VERSION ""

NS_ :

BS_:

BU_: PFAF_HS LVMPC_HS DCDC_HS AMP_HS VICM2_HS FICM_HS ARS_HS MCP_B_HS MCP_A_HS ICCM_OBD_HS SAS_HS ACCM_HS VLBS_HS EBCM_OBD_HS EDI_HS HPCC_HS VITM_OBD_HS PTAM_HS OBCM_HS VICM_HS HCP_HS FDCM_HS APPS_HS ICCM_HS EOCM_F_HS GPCM_HS FSCM_ITBC_HS SCM_HS ITBC_HS VCM_HS HMIM_HS FCP_HS VES_HS Dummy_HS MCP_C_HS RWS_HS ONSTAR_HS EPS_HS TestTool_HS MCP_HS BCP_HS ALC_HS AHL_AFL_HS SADS_HS EPB_HS FSCM_HS AFS_HS FCM_HS TCCM_HS RDCM_HS PTO_HS PCM_HS EBCM_HS ACC_HS BCM_HS TCM_HS ECM_HS
VAL_TABLE_ vt_BooleanValues 1 "true" 0 "false" ;
VAL_TABLE_ TCTPIR_DrvNotfn 15 "Indication 15" 14 "Indication 14" 13 "Indication 13" 12 "Indication 12" 11 "Indication 11" 10 "Indication 10" 9 "Indication 9" 8 "Indication 8" 7 "Indication 7" 6 "Indication 6" 5 "Indication 5" 4 "Indication 4" 3 "Indication 3" 2 "Indication 2" 1 "Indication 1" 0 "No Indication" ;
VAL_TABLE_ PltfrmEngSpdCmmndSt 3 "Request Denied" 2 "Lost Arbitration" 1 "Request Honored" 0 "No Request" ;
VAL_TABLE_ TrStPTGrdBrkDsMdOvr 3 "Unused and Reserved" 2 "To Grade Braking Disable" 1 "To Not Grade Braking Disable" 0 "No Override" ;
VAL_TABLE_ SpdLmtrSttngTyp 1 "Auto" 0 "Manual" ;
VAL_TABLE_ HiPresFuelPmpCntMd 6 "Zero Flow Mode" 5 "Noise Control Max Mode" 4 "Noise Control Disable Mode" 3 "Start Mode" 2 "Normal Mode" 1 "DFCO Mode" 0 "Disable Mode" ;
VAL_TABLE_ ClmtCtrlHtrEngRunRq 1 "Engine Run Requested" 0 "No Action" ;
VAL_TABLE_ TrnsStWntrMdOvrd 2 "Override To Winter" 1 "Override To Not Winter" 0 "No Override" ;
VAL_TABLE_ TrnsStTwHaulMdOvrd 2 "Override To Tow Haul" 1 "Override To Not Tow Haul" 0 "No Override" ;
VAL_TABLE_ TrnsStSprtMdOvrd 2 "Override To Sport" 1 "Override To Not Sport" 0 "No Override" ;
VAL_TABLE_ TrnsStEconMdOvrd 2 "Override To Economy" 1 "Override To Not Economy" 0 "No Override" ;
VAL_TABLE_ StgSysPerfMdRq 7 "Performance Mode 7" 6 "Performance Mode 6" 5 "Performance Mode 5" 4 "Performance Mode 4" 3 "Performance Mode 3" 2 "Performance Mode 2" 1 "Performance Mode 1" 0 "No Action" ;
VAL_TABLE_ SndEnhcmtPerfMdRq 7 "Performance Mode 7" 6 "Performance Mode 6" 5 "Performance Mode 5" 4 "Performance Mode 4" 3 "Performance Mode 3" 2 "Performance Mode 2" 1 "Performance Mode 1" 0 "No Action" ;
VAL_TABLE_ RideCntrlPerfMdRq 7 "Performance Mode 7" 6 "Performance Mode 6" 5 "Performance Mode 5" 4 "Performance Mode 4" 3 "Performance Mode 3" 2 "Performance Mode 2" 1 "Performance Mode 1" 0 "No Action" ;
VAL_TABLE_ ExhstPerfMdRq 7 "Performance Mode 7" 6 "Performance Mode 6" 5 "Performance Mode 5" 4 "Performance Mode 4" 3 "Performance Mode 3" 2 "Performance Mode 2" 1 "Performance Mode 1" 0 "No Action" ;
VAL_TABLE_ DsplyPerfMdRq 7 "Performance Mode 7" 6 "Performance Mode 6" 5 "Performance Mode 5" 4 "Performance Mode 4" 3 "Performance Mode 3" 2 "Performance Mode 2" 1 "Performance Mode 1" 0 "No Action" ;
VAL_TABLE_ DiffPerfMdRq 7 "Performance Mode 7" 6 "Performance Mode 6" 5 "Performance Mode 5" 4 "Performance Mode 4" 3 "Performance Mode 3" 2 "Performance Mode 2" 1 "Performance Mode 1" 0 "No Action" ;
VAL_TABLE_ AWDPerfMdRq 7 "Performance Mode 7" 6 "Performance Mode 6" 5 "Performance Mode 5" 4 "Performance Mode 4" 3 "Performance Mode 3" 2 "Performance Mode 2" 1 "Performance Mode 1" 0 "No Action" ;
VAL_TABLE_ RdHVltBatPckVltM 1 "Use Data" 0 "Don't Use Data" ;
VAL_TABLE_ RdHVltBatPckCrntM 1 "Use Data" 0 "Don't Use Data" ;
VAL_TABLE_ RdHVltBatMinClVltM 1 "Use Data" 0 "Don't Use Data" ;
VAL_TABLE_ RdHVltBatMaxClVltM 1 "Use Data" 0 "Don't Use Data" ;
VAL_TABLE_ AFRP_SnsTyp 3 "Gauge Pressure" 2 "Absolute Pressure" 1 "Pressure Relative Manifold Vacuum" 0 "Not Supported" ;
VAL_TABLE_ FICMDS3_DTCStatus 4 "Diagnostic Failed" 3 "Diagnostic Passed" 2 "No Status to Report" 1 "Critically Disabled" 0 "Not Supported" ;
VAL_TABLE_ FICMDS2_DTCStatus 4 "Diagnostic Failed" 3 "Diagnostic Passed" 2 "No Status to Report" 1 "Critically Disabled" 0 "Not Supported" ;
VAL_TABLE_ FICMDS1_DTCStatus 4 "Diagnostic Failed" 3 "Diagnostic Passed" 2 "No Status to Report" 1 "Critically Disabled" 0 "Not Supported" ;
VAL_TABLE_ PropSysOffTmeM 1 "Use Data" 0 "Don't Use Data" ;
VAL_TABLE_ OffBrdChrgOffTmeM 1 "Use Data" 0 "Don't Use Data" ;
VAL_TABLE_ BattThrmlCondOffTmeM 1 "Use Data" 0 "Don't Use Data" ;
VAL_TABLE_ CrsSecSwStat 15 "Unused and Reserved 7" 14 "Unused and Reserved 6" 13 "Unused and Reserved 5" 12 "Unused and Reserved 4" 11 "Unused and Reserved 3" 10 "Unused and Reserved 2" 9 "Between Ranges" 8 "Short to Power" 7 "Open/Short to Ground" 6 "Speed Decrease High" 5 "Speed Increase High" 4 "Gap Up" 3 "Gap Down" 2 "Unused and Reserved 1" 1 "No Activation" 0 "Indeterminate" ;
VAL_TABLE_ EDADS_RcmndtFwdGr 15 "Unused and Reserved 7" 14 "Unused and Reserved 6" 13 "Unused and Reserved 5" 12 "Unused and Reserved 4" 11 "Unused and Reserved 3" 10 "Unused and Reserved 2" 9 "Unused and Reserved 1" 8 "Eighth Gear" 7 "Seventh Gear" 6 "Sixth Gear" 5 "Fifth Gear" 4 "Fourth Gear" 3 "Third Gear" 2 "Second Gear" 1 "First Gear" 0 "None" ;
VAL_TABLE_ EDADS_CrntFwdMsdG 15 "Unused and Reserved 7" 14 "Unused and Reserved 6" 13 "Unused and Reserved 5" 12 "Unused and Reserved 4" 11 "Unused and Reserved 3" 10 "Unused and Reserved 2" 9 "Unused and Reserved 1" 8 "Eighth Gear" 7 "Seventh Gear" 6 "Sixth Gear" 5 "Fifth Gear" 4 "Fourth Gear" 3 "Third Gear" 2 "Second Gear" 1 "First Gear" 0 "None" ;
VAL_TABLE_ EDADS_ShftIndStat 2 "No Shift" 1 "Shift Up" 0 "Shift Down" ;
VAL_TABLE_ PrsElvtdIdlCntlStat 1 "Enabled" 0 "Disabled" ;
VAL_TABLE_ GPCMDS2_DTCStatus 4 "Diagnostic Failed" 3 "Diagnostic Passed" 2 "No Status to Report" 1 "Critically Disabled" 0 "Not Supported" ;
VAL_TABLE_ EngPwrCnfg 15 "Configuration 15" 14 "Configuration 14" 13 "Configuration 13" 12 "Configuration 12" 11 "Configuration 11" 10 "Configuration 10" 9 "Configuration 9" 8 "Configuration 8" 7 "Configuration 7" 6 "Configuration 6" 5 "Configuration 5" 4 "Configuration 4" 3 "Configuration 3" 2 "Configuration 2" 1 "Configuration 1" 0 "Default" ;
VAL_TABLE_ CTSS_StbltyLvl 7 "Level 7" 6 "Level 6" 5 "Level 5" 4 "Level 4" 3 "Level 3" 2 "Level 2" 1 "Level 1" 0 "Level 0" ;
VAL_TABLE_ CTSS_StbltyTyp 7 "Unused and Reserved 4" 6 "Unused and Reserved 3" 5 "Unused and Reserved 2" 4 "Unused and Reserved 1" 3 "Torque Increase Pending" 2 "Torque Decrease Pending" 1 "Torque High Pulsation" 0 "Normal Stability" ;
VAL_TABLE_ DslExhFldWrngIdRqER 15 "Warning Level 15" 14 "Warning Level 14" 13 "Warning Level 13" 12 "Warning Level 12" 11 "Warning Level 11" 10 "Warning Level 10" 9 "Warning Level 9" 8 "Warning Level 8" 7 "Warning Level 7" 6 "Warning Level 6" 5 "Warning Level 5" 4 "Warning Level 4" 3 "Warning Level 3" 2 "Warning Level 2" 1 "Warning Level 1" 0 "No Indication" ;
VAL_TABLE_ DslExhFldQlyWrngIReq 15 "Warning Level 15" 14 "Warning Level 14" 13 "Warning Level 13" 12 "Warning Level 12" 11 "Warning Level 11" 10 "Warning Level 10" 9 "Warning Level 9" 8 "Warning Level 8" 7 "Warning Level 7" 6 "Warning Level 6" 5 "Warning Level 5" 4 "Warning Level 4" 3 "Warning Level 3" 2 "Warning Level 2" 1 "Warning Level 1" 0 "No Indication" ;
VAL_TABLE_ DslExNxEmWrngIndRq 15 "Warning Level 15" 14 "Warning Level 14" 13 "Warning Level 13" 12 "Warning Level 12" 11 "Warning Level 11" 10 "Warning Level 10" 9 "Warning Level 9" 8 "Warning Level 8" 7 "Warning Level 7" 6 "Warning Level 6" 5 "Warning Level 5" 4 "Warning Level 4" 3 "Warning Level 3" 2 "Warning Level 2" 1 "Warning Level 1" 0 "No Indication" ;
VAL_TABLE_ DslExFldTpWrngIndRq 15 "Warning Level 15" 14 "Warning Level 14" 13 "Warning Level 13" 12 "Warning Level 12" 11 "Warning Level 11" 10 "Warning Level 10" 9 "Warning Level 9" 8 "Warning Level 8" 7 "Warning Level 7" 6 "Warning Level 6" 5 "Warning Level 5" 4 "Warning Level 4" 3 "Warning Level 3" 2 "Warning Level 2" 1 "Warning Level 1" 0 "No Indication" ;
VAL_TABLE_ DslExFldCnWrngIndRq 15 "Warning Level 15" 14 "Warning Level 14" 13 "Warning Level 13" 12 "Warning Level 12" 11 "Warning Level 11" 10 "Warning Level 10" 9 "Warning Level 9" 8 "Warning Level 8" 7 "Warning Level 7" 6 "Warning Level 6" 5 "Warning Level 5" 4 "Warning Level 4" 3 "Warning Level 3" 2 "Warning Level 2" 1 "Warning Level 1" 0 "No Indication" ;
VAL_TABLE_ DrvSelMdSw3Sta 1 "Active" 0 "Inactive" ;
VAL_TABLE_ DrvSelMdSw2Sta 1 "Active" 0 "Inactive" ;
VAL_TABLE_ DrvSelMd8Stat 1 "Active" 0 "Inactive" ;
VAL_TABLE_ DrvSelMd7Stat 1 "Active" 0 "Inactive" ;
VAL_TABLE_ DrvSelMd6Stat 1 "Active" 0 "Inactive" ;
VAL_TABLE_ DrvSelMd5Stat 1 "Active" 0 "Inactive" ;
VAL_TABLE_ DrvSelMd4Stat 1 "Active" 0 "Inactive" ;
VAL_TABLE_ DrvSelMd3Stat 1 "Active" 0 "Inactive" ;
VAL_TABLE_ DrvSelMd2Stat 1 "Active" 0 "Inactive" ;
VAL_TABLE_ A6ERRAlrmReq 2 "Cancel Alarm" 1 "Set Alarm" 0 "No Action" ;
VAL_TABLE_ MntnceMdDsplyRq 15 "Unused and Reserved" 14 "Continue FM" 13 "Force FM" 12 "FM 1 Day Warning" 11 "FM 2 Day Warning" 10 "FM 3 Day Warning" 9 "FM 4 Day Warning" 8 "FM 5 Day Warning" 7 "Continue EM" 6 "Force EM" 5 "EM 1 Day Warning" 4 "EM 2 Day Warning" 3 "EM 3 Day Warning" 2 "EM 4 Day Warning" 1 "EM 5 Day Warning" 0 "No Request" ;
VAL_TABLE_ HybACCompRq 3 "Reserved" 2 "Disengage" 1 "Engage" 0 "No Action" ;
VAL_TABLE_ TrnsInpDvcStat 7 "Unused and Reserved 5" 6 "Unused and Reserved 4" 5 "Unused and Reserved 3" 4 "Unused and Reserved 2" 3 "Unused and Reserved 1" 2 "Permanent Isolation" 1 "Temporary Isolation" 0 "Normal Control" ;
VAL_TABLE_ AuxClntHtrVlvStat 7 "Unused and Reserved 2" 6 "De-Aeration Routine Active" 5 "Diagnostic Override" 4 "Re-Calibration" 3 "Fault Active" 2 "Engine Link" 1 "Transition" 0 "Engine Bypass" ;
VAL_TABLE_ DrvSelMdSw1Sta 1 "Active" 0 "Inactive" ;
VAL_TABLE_ VICntlModRunCrkTrmSt 1 "Active" 0 "Inactive" ;
VAL_TABLE_ DrvSelMd1Stat 1 "Active" 0 "Inactive" ;
VAL_TABLE_ ETC_EngOpMd 1 "Half Cylinders" 0 "All cylinders" ;
VAL_TABLE_ EngCntrlUtldTrnCsRng 3 "Neutral" 2 "Unused and Reserved" 1 "Low" 0 "High" ;
VAL_TABLE_ CSTATRS_ReqStat 6 "Control System Failure Permanent" 5 "Control System Failure Temporary" 4 "Serial Data Failure Permanent" 3 "Serial Data Failure Temporary" 2 "Lost Arbitration" 1 "Request Honored" 0 "No Request" ;
VAL_TABLE_ CSTATRS_LmtgStat 3 "Rate and Value Limited" 2 "Value Limited" 1 "Rate Limited" 0 "Not Limited" ;
VAL_TABLE_ PTTrnsfrCseMd 3 "Neutral" 2 "4 Wheel Drive Low" 1 "4 Wheel Drive High" 0 "2 Wheel Drive High" ;
VAL_TABLE_ TrnsHybEngSrtStpOvrd 2 "Engine Off" 1 "Engine On" 0 "No Override" ;
VAL_TABLE_ EngCntrlDtrmdTrfCRng 3 "Neutral" 2 "Unused and Reserved" 1 "Low" 0 "High" ;
VAL_TABLE_ ElecPrkBrkAvailStat 7 "Unused and Reserved 3" 6 "Unused and Reserved 2" 5 "Unused and Reserved 1" 4 "Unavailable, Failed other" 3 "Unavailable, Failed Released" 2 "Unavailable, Failed Applied" 1 "Available, Not Failed" 0 "Unavailable, Not Failed" ;
VAL_TABLE_ ElecPrkBrkApplStat 3 "Park Brake Application in Progress" 2 "Park brake Released" 1 "Park Brake Applied" 0 "Unknown" ;
VAL_TABLE_ BCHR_BattCrntRwVlMu 3 "Multiplier Factor 256" 2 "Multiplier Factor 64" 1 "Multiplier Factor 8" 0 "Multiplier Factor 1" ;
VAL_TABLE_ BattSOXStat 1 "Use SOC,SOH, & SOF" 0 "Don't Use SOC,SOH, & SOF" ;
VAL_TABLE_ CSPATR_TrqIntrvnTyp 3 "Minimum and Maximum Limit" 2 "Minimum Limit" 1 "Maximum Limit" 0 "No Intervention" ;
VAL_TABLE_ CSPATR_TrqRqTyp 0 "Absolute Torque Request" ;
VAL_TABLE_ ChsSysAxlTqRqRspTyp 4 "Braking Torque Request" 3 "Automatic Actuator Selection" 2 "Maximum Range Request" 1 "Pleasability Limited Request" 0 "Inactive" ;
VAL_TABLE_ EngOffTmPTM 1 "Use Data" 0 "Don't Use Data" ;
VAL_TABLE_ HybMdDisp 15 "Engine Charging Battery While Idle" 14 "Engine Charging Battery Moving" 13 "Engine Power Load Sharing" 12 "Battery Power Load Sharing" 11 "Undetermined" 10 "Charging With Engine On" 9 "Charging With Engine Off" 8 "Hybrid Power 4WD" 7 "Hybrid Power 2WD" 6 "Engine Power 4WD" 5 "Engine Power 2WD" 4 "Battery Power 4WD" 3 "Battery Power 2WD" 2 "Auto Stop" 1 "Engine Idle" 0 "Default / Accessory" ;
VAL_TABLE_ PerfTrcTrqRqStat 6 "Control System Failure Permanent" 5 "Control System Failure Temporary" 4 "Serial Data Failure Permanent" 3 "Serial Data Failure Temporary" 2 "Lost Arbitration" 1 "Request Honored" 0 "No Request" ;
VAL_TABLE_ PTTR_TrqRedRlzSugg 1 "Transient Optimized" 0 "No Suggestion" ;
VAL_TABLE_ PTTR_TrqInvTyp 1 "Maximum Limit" 0 "No Intervention" ;
VAL_TABLE_ PerfTrcTrqLmtStat 3 "Rate & Value Limited" 2 "Value Limited" 1 "Rate Limited" 0 "Not Limited" ;
VAL_TABLE_ PerfTrcEngSpdRqStat 6 "Control System Failure Permanent" 5 "Control System Failure Temporary" 4 "Serial Data Failure Permanent" 3 "Serial Data Failure Temporary" 2 "Lost Arbitration" 1 "Request Honored" 0 "No Request" ;
VAL_TABLE_ PTESR_EngSpdCntlRs 3 "Stability Optimized Cond 2" 2 "Stability Optimized Cond 1" 1 "Transient Optimized" 0 "No Suggestion" ;
VAL_TABLE_ PTESR_EngSpdIntTyp 1 "Engine Speed Max Limit" 0 "No Intervention" ;
VAL_TABLE_ PerfTrcEngSpdLmtStat 3 "Rate & Value Limited" 2 "Value Limited" 1 "Rate Limited" 0 "Not Limited" ;
VAL_TABLE_ TPCTR_TrqIntrvnTyp 3 "Unused and Reserved" 2 "Minimum Limit" 1 "Maximum Limit" 0 "No Request" ;
VAL_TABLE_ TICTR_TorqRespTyp 3 "Automatic Actuator Selection" 2 "Maximum Range" 1 "Pleasability Limited" 0 "Inactive" ;
VAL_TABLE_ EngCrsCntrlMode 5 "Tap" 4 "Coast" 3 "Accel" 2 "Resume" 1 "Engaged" 0 "Inactive" ;
VAL_TABLE_ EngPrdctTrqTnsRqStat 7 "Unused and Reserved" 6 "Control System Failure Permanent" 5 "Control System Failure Temporary" 4 "Serial Data Failure Permanent" 3 "Serial Data Failure Temporary" 2 "Lost Arbitration" 1 "Request Honored" 0 "No Request" ;
VAL_TABLE_ EngPrdctTrqTnsRqLmS 7 "Unused and Reserved 4" 6 "Unused and Reserved 3" 5 "Unused and Reserved 2" 4 "Unused and Reserved 1" 3 "Value Limited High" 2 "Value Limited Low" 1 "Rate Limited" 0 "Not Limited" ;
VAL_TABLE_ EngImmTrqTnsRqStat 0 "No Request" 7 "Unused and Reserved" 6 "Control System Failure Permanent" 5 "Control System Failure Temporary" 4 "Serial Data Failure Permanent" 3 "Serial Data Failure Temporary" 2 "Lost Arbitration" 1 "Request Honored" ;
VAL_TABLE_ EngImmTrqTnsRqLmSt 7 "Unused and Reserved 4" 6 "Unused and Reserved 3" 5 "Unused and Reserved 2" 4 "Unused and Reserved 1" 3 "Value Limited High" 2 "Value Limited Low" 1 "Rate Limited" 0 "Not Limited" ;
VAL_TABLE_ CrsSpdLmtrSwStat 9 "Between Ranges" 8 "Short to Power" 7 "Open/Short to Ground" 6 "Cancel" 5 "Cruise On/Off" 4 "SL/SW On/Off/GAP" 3 "Set" 2 "Resume" 1 "No Activation" 0 "Indeterminate" ;
VAL_TABLE_ RrAxlSta 3 "Permanently Failed" 2 "Temporary Limited" 1 "Temporary Inhibit" 0 "Normal" ;
VAL_TABLE_ SecAxlStat 3 "Permanently Failed" 2 "Temporary Limited" 1 "Temporary Inhibit" 0 "Normal" ;
VAL_TABLE_ HESSI_EngStrtTyp 9 "Compression Test" 8 "Auto Start Generic" 7 "Auto Start Aggressive" 6 "Auto Start Normal" 5 "Auto Start Smooth" 4 "Key Start Generic" 3 "Key Start Low Power B" 2 "Key Start Low Power" 1 "Key Start Normal" 0 "No Start" ;
VAL_TABLE_ HESSI_EngStrtStpMd 7 "Start Failed" 6 "Stop Pending" 5 "Disable Fuel" 4 "Producing Torque" 3 "Enable Fuel" 2 "Start Pending" 1 "Immediate Stop" 0 "Stop" ;
VAL_TABLE_ HybDFCOReq 1 "DFCO Requested" 0 "DFCO Not Requested" ;
VAL_TABLE_ EngCntlSenPTRlyVltM 1 "Use Data" 0 "Don't Use Data" ;
VAL_TABLE_ GPCMDS_DTCStatus 4 "Diagnostic Failed" 3 "Diagnostic Passed" 2 "No Status to Report" 1 "Critically Disabled" 0 "Not Supported" ;
VAL_TABLE_ IQAI_InjIdInd 7 "Injector 8" 6 "Injector 7" 5 "Injector 6" 4 "Injector 5" 3 "Injector 4" 2 "Injector 3" 1 "Injector 2" 0 "Injector 1" ;
VAL_TABLE_ IQAI_DataStat 1 "IQA Data Byte Stored" 0 "IQA Data Byte Not Stored" ;
VAL_TABLE_ ACCATC_DrvAstdGoSt 2 "Apply Acc Pedal or Resume Sw To Go" 1 "Apply Accel Pedal to Go" 0 "Not Stopped" ;
VAL_TABLE_ WhlSlpSt 3 "Slip Detection Fault" 2 "Positive Slip Detected" 1 "Negative Slip Detected" 0 "No Slip Detected" ;
VAL_TABLE_ EnhSvVehTopSpdLmR 2 "Inactive" 1 "Active" 0 "No Action" ;
VAL_TABLE_ ACCmEngRunReq 1 "Engine Run Requested" 0 "No Action" ;
VAL_TABLE_ FuelMdSwAct 1 "True" 0 "False" ;
VAL_TABLE_ FuelMdStat 3 "Alternative Fuel Cut-off Active" 2 "Liquified Petroleum Gas Mode" 1 "Natural Gas Mode" 0 "Gasoline Mode" ;
VAL_TABLE_ WrmUpShftPtrnRq 1 "Active" 0 "Inactive" ;
VAL_TABLE_ EngCntrlRunCrnkTrmSt 1 "Active" 0 "Inactive" ;
VAL_TABLE_ ACCATC_ACCTyp 2 "Full Speed Range ACC with Booster" 1 "Full Speed Range ACC" 0 "Adaptive Cruise Control" ;
VAL_TABLE_ ACCATCS_RqStat 4 "Request Suspended Till Driver Input" 3 "Request Denied" 2 "Lost Arbitration" 1 "Request Honored" 0 "No Request" ;
VAL_TABLE_ ACCATCS_LmtgStat 3 "Request Rate Limited" 2 "Request Value Limited Maximum" 1 "Request Value Limited Minimum" 0 "Request Not Limited" ;
VAL_TABLE_ EPBSysWrnIndReq 3 "Flash Rate #2 Indication" 2 "Flash Rate #1 Indication" 1 "Continuous Indication" 0 "No Indication" ;
VAL_TABLE_ VehSpeSta 3 "Invalid" 2 "Fast" 1 "Slow" 0 "Stationary" ;
VAL_TABLE_ DslPartFltrClngAlgActM 1 "Use Data" 0 "Don't Use Data" ;
VAL_TABLE_ SecAxlOpeMod 3 "Active All Wheel Drive (High)" 2 "4 Wheel Drive Low Locked" 1 "4 Wheel Drive High Locked" 0 "2 Wheel Drive High" 15 "Neutral" 14 "Unknown" 7 "2 Wheel Drive Low" 6 "Active All Wheel Drive (Low)" 5 "4 Wheel Drive Low Open" 4 "4 Wheel Drive High Open" ;
VAL_TABLE_ SecAxlCtrlMod 1 "External" 0 "Internal" ;
VAL_TABLE_ RrAxlOpeMod 3 "Unknown" 2 "Locked" 1 "Active" 0 "Open" ;
VAL_TABLE_ RrAxlCtrlMod 1 "External" 0 "Internal" ;
VAL_TABLE_ EPBSwSta 2 "Apply" 1 "Release" 0 "NotActive" ;
VAL_TABLE_ EPBSta 2 "Fault" 1 "Applied" 0 "Released" ;
VAL_TABLE_ FlPmpEDscOtptCmdSta 1 "Fuel Pump Enabled" 0 "Fuel Pump Disabled" ;
VAL_TABLE_ TransTUDMdStat 2 "Electronic Range Select Active" 1 "Driver Shift Control Active" 0 "No Activation" ;
VAL_TABLE_ TrnShftPtrnActStat 6 "PT Protection Pattern Active" 5 "PT Non-Protection Pattern Active" 4 "Shift Pattern 4 Active" 3 "Shift Pattern 3 Active" 2 "Shift Pattern 2 Active" 1 "Shift Pattern 1 Active" 0 "Default Shift Pattern Active" ;
VAL_TABLE_ EPBSysAudWarnReq 2 "Warning #2" 1 "Warning #1" 0 "Off" ;
VAL_TABLE_ NotEventSta 2 "Pretensioner Deployment Event" 1 "Near Deployment Event" 0 "No Event" 3 "Airbag Deployment Event" ;
VAL_TABLE_ VehMovSta 4 "Invalid" 3 "Reverse" 2 "Forward" 1 "Neutral" 0 "Parked" ;
VAL_TABLE_ PFTrnsTUDSwSt 3 "Illegal Up/Down Switch State Active" 2 "Decrement Switch Active" 1 "Increment Switch Active" 0 "No Activation" ;
VAL_TABLE_ PFTrnsTUDEnSwSt 3 "Illegal Enable Switch State" 2 "Electronic Range Select Enable Sw" 1 "Driver Shift Control Enable Switch" 0 "No Activation" ;
VAL_TABLE_ AuxHtrRq 1 "On" 0 "Off" ;
VAL_TABLE_ TrnsEngdState 3 "Operating State Not Reached" 2 "Transmission Engaged in Reverse" 1 "Transmission Engaged in Forward" 0 "Transmission Not Engaged" ;
VAL_TABLE_ EPBSysDspMsgReq 7 "Message #7" 6 "Message #6" 5 "Message #5" 4 "Message #4" 3 "Message #3" 2 "Message #2" 1 "Message #1" 0 "Off" ;
VAL_TABLE_ OtsdAmbtLtLvlStat 2 "Day" 1 "Night" 0 "Unknown" ;
VAL_TABLE_ RdSpdCatType 3 "all speed categories 0 - 50 km/h" 2 "all speed categories 51-80 km/h" 1 "all speed categories 81-130 km/h" 0 "all speed categories > 130 km/h" ;
VAL_TABLE_ LnCat 3 "Four Or More Lanes" 2 "Two Or Three Lanes" 1 "One lane" 0 "no info available" ;
VAL_TABLE_ FncRdClass 7 "COLLECTOR" 6 "ALLEY" 5 "ARTERIAL" 4 "HIGHWAY" 3 "PED-MALL" 2 "FREEWAY" 1 "SFREEWAY" 0 "LOCAL (Residential Road)" ;
VAL_TABLE_ CustomizationSettingRequest 7 "Auto" 6 "Performance Mode 6" 5 "Performance Mode 5" 4 "Performance Mode 4" 3 "Performance Mode 3" 2 "Performance Mode 2" 1 "Performance Mode 1" 0 "No Action" ;
VAL_TABLE_ RstrCustFctrDef 1 "Restore Defaults" 0 "No Action" ;
VAL_TABLE_ PFTrnsTUDSecSwSt 3 "Illegal Up/Down Switch State Active" 2 "Decrement Switch Active" 1 "Increment Switch Active" 0 "No Activation" ;
VAL_TABLE_ AdvFrntLghtSysIndRq 7 "Indication 7" 6 "Indication 6" 5 "Indication 5" 4 "Indication 4" 3 "Indication 3" 2 "Indication 2" 1 "Indication 1" 0 "No Indication" ;
VAL_TABLE_ CustomizationCurrentSettingValue 7 "Auto" 6 "Performance Mode 6" 5 "Performance Mode 5" 4 "Performance Mode 4" 3 "Performance Mode 3" 0 "No Action" 1 "Performance Mode 1" 2 "Performance Mode 2" ;
VAL_TABLE_ EPBSysStatIndReq 3 "Flash Rate 2 Indication" 2 "Flash Rate 1 Indication" 1 "Continuous Indication" 0 "No Indication" ;
VAL_TABLE_ AllNodesVNA 1 "Activate Virtual Network" 0 "No Activation" ;
VAL_TABLE_ ClntCircPmpRq 1 "On" 0 "Off" ;
VAL_TABLE_ ImoIdSt 1 "Info valid" 0 "No info" ;
VAL_TABLE_ LrnEnvIdSt 1 "Info_valid" 0 "No_info" ;
VAL_TABLE_ EnvIdRspSt4 3 "Environment_id_request" 2 "Incorrect_immo_id" 1 "Info_valid" 0 "No_info" ;
VAL_TABLE_ VDAvailability 1 "VirtualDeviceAvailable" 0 "VirtualDeviceUnavailable" ;
VAL_TABLE_ AlrmStat 4 "Arming Delay" 3 "Alarm Active" 2 "Disarmed" 1 "Armed" 0 "Off" ;
VAL_TABLE_ RstVTDTmprDtctd 1 "Reset" 0 "No Action" ;
VAL_TABLE_ RstIllDrIdDevDtctd 1 "Reset" 0 "No Action" ;
VAL_TABLE_ RstDrIdDevLrnd 1 "Reset" 0 "No Action" ;
VAL_TABLE_ CldrMth 12 "December" 11 "November" 10 "October" 9 "September" 8 "August" 7 "July" 6 "June" 5 "May" 4 "April" 3 "March" 2 "February" 1 "January" 0 "Unknown" ;
VAL_TABLE_ TrnSwAct 2 "Right" 1 "Left" 0 "No Activation" ;
VAL_TABLE_ VehHghtStat 4 "Maximum Height" 3 "Kneeling Height" 2 "Aerodynamic Height" 1 "Normal Design Ride Height" 0 "Unknown" ;
VAL_TABLE_ HdlmpBmSelectStat 2 "High Beams" 1 "Low Beams" 0 "Unknown" ;
VAL_TABLE_ ACSAlarm9 2 "Expired" 1 "Active" 0 "Inactive" ;
VAL_TABLE_ ACSAlarm8 2 "Expired" 1 "Active" 0 "Inactive" ;
VAL_TABLE_ ACSAlarm7 2 "Expired" 1 "Active" 0 "Inactive" ;
VAL_TABLE_ ACSAlarm6 2 "Expired" 1 "Active" 0 "Inactive" ;
VAL_TABLE_ ACSAlarm5 2 "Expired" 1 "Active" 0 "Inactive" ;
VAL_TABLE_ ACSAlarm4 2 "Expired" 1 "Active" 0 "Inactive" ;
VAL_TABLE_ ACSAlarm3 2 "Expired" 1 "Active" 0 "Inactive" ;
VAL_TABLE_ ACSAlarm2 2 "Expired" 1 "Active" 0 "Inactive" ;
VAL_TABLE_ ACSAlarm15 2 "Expired" 1 "Active" 0 "Inactive" ;
VAL_TABLE_ ACSAlarm14 2 "Expired" 1 "Active" 0 "Inactive" ;
VAL_TABLE_ ACSAlarm13 2 "Expired" 1 "Active" 0 "Inactive" ;
VAL_TABLE_ ACSAlarm12 2 "Expired" 1 "Active" 0 "Inactive" ;
VAL_TABLE_ ACSAlarm11 2 "Expired" 1 "Active" 0 "Inactive" ;
VAL_TABLE_ ACSAlarm10 2 "Expired" 1 "Active" 0 "Inactive" ;
VAL_TABLE_ ACSAlarm1 2 "Expired" 1 "Active" 0 "Inactive" ;
VAL_TABLE_ ACSAlarm0 2 "Expired" 1 "Active" 0 "Inactive" ;
VAL_TABLE_ ACCHdwyStg 7 "Headway Setting 7" 6 "Headway Setting 6" 5 "Headway Setting 5" 4 "Headway Setting 4" 3 "Headway Setting 3" 2 "Headway Setting 2" 1 "Headway Setting 1" 0 "Minimum Headway Setting" ;
VAL_TABLE_ VehStabEnhmntMd 2 "Competitive" 1 "Normal" 0 "Off" ;
VAL_TABLE_ VehStabEnhmntStat 4 "Not Ready" 3 "Warming Up" 2 "Fault" 1 "Active" 0 "Inactive" ;
VAL_TABLE_ TCSysOpMd 2 "Off Road" 1 "Normal" 0 "Off" ;
VAL_TABLE_ TCSysOpStat 2 "Fault" 1 "Active" 0 "Inactive" ;
VAL_TABLE_ HillDscntCntlSysStat 4 "Temporarily Inhibited" 3 "Failed" 2 "Active" 1 "Enabled" 0 "Normal" ;
VAL_TABLE_ EnrgMgtLdShdRq 4 "Load Shed Level 4" 3 "Load Shed Level 3" 2 "Load Shed Level 2" 1 "Load Shed Level 1" 0 "No Load Shedding" ;
VAL_TABLE_ DrId 7 "Unknown" 6 "Driver #7" 5 "Driver #6" 4 "Driver #5" 3 "Driver #4" 2 "Driver #3" 1 "Driver #2" 0 "Driver #1" ;
VAL_TABLE_ TireRRPrsStat 5 "High" 4 "Low - Extended Mobility" 3 "Low" 2 "Low - Service Now" 1 "Nominal" 0 "Unknown" ;
VAL_TABLE_ TireRFPrsStat 5 "High" 4 "Low - Extended Mobility" 3 "Low" 2 "Low - Service Now" 1 "Nominal" 0 "Unknown" ;
VAL_TABLE_ TireLRPrsStat 5 "High" 4 "Low - Extended Mobility" 3 "Low" 2 "Low - Service Now" 1 "Nominal" 0 "Unknown" ;
VAL_TABLE_ TireLFPrsStat 5 "High" 4 "Low - Extended Mobility" 3 "Low" 2 "Low - Service Now" 1 "Nominal" 0 "Unknown" ;
VAL_TABLE_ DTCI_DTCFaultType 3 "Type C" 2 "Type B" 1 "Type A" 0 "Not Supported" ;
VAL_TABLE_ DistRollCntAvgDrvnSrc 1 "Wheel Speed" 0 "Transmission Output Speed" ;
VAL_TABLE_ VehSpdAvgDrvnSrc 1 "Wheel Speed" 0 "Transmission Output Speed" ;
VAL_TABLE_ TORSLstTransType 3 "Undefined" 2 "Falling Transition" 1 "Rising Transition" 0 "Single Edge Sensor" ;
VAL_TABLE_ TORSRotDir 3 "Undefined" 2 "Reverse" 1 "Forward" 0 "Unknown" ;
VAL_TABLE_ TrnsThrmlMngmntStat 2 "Driver Intervention Requested" 1 "Countermeasures Active" 0 "Normal" ;
VAL_TABLE_ TrnsSftMdStat 3 "Automatic Grade Braking Mode" 2 "Lift-Foot Cornering Mode" 1 "Performance Mode" 0 "No Override Mode" ;
VAL_TABLE_ TrnsRngInhbtStat 4 "Diagnostic Inhibit Active" 3 "Driveline Not Engaged" 2 "Transmission Range Re-Selection Req" 1 "Transmission Inhibit Active" 0 "No Range Inhibit Active" ;
VAL_TABLE_ DrvtShftCntrlTrgtGear 8 "Eighth Gear" 7 "Seventh Gear" 6 "Sixth Gear" 5 "Fifth Gear" 4 "Fourth Gear" 3 "Third Gear" 2 "Second Gear" 1 "First Gear" 0 "Not Supported" ;
VAL_TABLE_ StrWhlAngSenCalStat 2 "Calibrated" 1 "Estimated" 0 "Unknown" ;
VAL_TABLE_ PTOTGRReqdGear 8 "Eighth Gear" 7 "Seventh Gear" 6 "Sixth Gear" 5 "Fifth Gear" 4 "Fourth Gear" 3 "Third Gear" 2 "Second Gear" 1 "First Gear" 0 "No Action" ;
VAL_TABLE_ PTOTGRReqType 3 "Hold Gear" 2 "Min Gear Request" 1 "Max Gear Request" 0 "No Action" ;
VAL_TABLE_ PTORmtEngStrtReq 1 "PTO Remote Start Requested" 0 "PTO Remote Start Not Requested" ;
VAL_TABLE_ FSERDTC_SysDes 15 "U3-Network Codes Reserved" 14 "U2-Network Codes Reserved" 13 "U1-Network Codes MFG Controlled" 12 "U0-Network Codes SAE Controlled" 11 "B3-Body Codes Reserved" 10 "B2-Body Codes Reserved" 9 "B1-Body Codes MFG Controlled" 8 "B0-Body Codes SAE Controlled" 7 "C3-Chassis Codes Reserved" 6 "C2-Chassis Codes Reserved" 5 "C1-Chassis Codes MFG Controlled" 4 "C0-Chassis Codes SAE Controlled" 3 "P3-Powertrain Codes Reserved" 2 "P2-Powertrain Codes Reserved" 1 "P1-Powertrain Codes MFG Controlled" 0 "P0-Powertrain Codes SAE Controlled" ;
VAL_TABLE_ EngFuelCntlState 2 "Stoichiometric Closed Loop" 1 "Non-Stoichiometric Closed Loop" 0 "Open Loop" ;
VAL_TABLE_ EngTrqRdFlrSt 4 "Torq Reduction Communication Failed" 3 "Torque Reduction Limited" 2 "Torque Reduction Permanently Failed" 1 "Torque Reduction Temporarily Failed" 0 "Torque Reduction OK" ;
VAL_TABLE_ ParkNeutralSwStat 1 "Not Park/Neutral" 0 "Park/Neutral" ;
VAL_TABLE_ EngBrkStat 2 "Active Absorbing Torque" 1 "Active Not Absorbing Torque" 0 "Inactive" ;
VAL_TABLE_ ETGRReqdGear 8 "Eighth Gear" 7 "Seventh Gear" 6 "Sixth Gear" 5 "Fifth Gear" 4 "Fourth Gear" 3 "Third Gear" 2 "Second Gear" 1 "First Gear" 0 "No Action" ;
VAL_TABLE_ ETGRReqType 0 "No Action" 3 "Hold Gear" 2 "Min Gear Request" 1 "Max Gear Request" ;
VAL_TABLE_ OAT_PT_EstM 1 "Use Data" 0 "Don't Use Data" ;
VAL_TABLE_ ACCompCmnd 1 "On" 0 "Off" ;
VAL_TABLE_ EngEmsRelMalfIndReq 4 "Flashing 0.5 Hertz Indication" 3 "Flashing 2 Hertz Indication" 2 "Flashing 1 Hertz Indication" 1 "No Indication" 0 "Continuous Indication" ;
VAL_TABLE_ EngCylDeactMd 3 "Reactivation In Progress" 2 "Half of Total Cylinders Active" 1 "Deactivation In Progress" 0 "All Cylinders Active" ;
VAL_TABLE_ PltfrmEngSpdCmdInhtRq 1 "Inhibit Platform Eng. Speed Control" 0 "Allow Platform Engine Speed Control" ;
VAL_TABLE_ PT_BrkPedDscrtInpStat 1 "Brake Applied" 0 "Brake Not Applied" ;
VAL_TABLE_ EngSpdStat 3 "Invalid" 1 "Degraded Operation" 0 "Normal Operation" ;
VAL_TABLE_ TrnsCyDactTransStat 2 "Ready for Half of TotalCylinders" 1 "Ready for All Cylinders" 0 "Not Ready" ;
VAL_TABLE_ ACCompSysVDM 1 "Use Data" 0 "Don't Use Data" ;
VAL_TABLE_ BkupPwrModeMstrVDM 1 "Use Data" 0 "Don't Use Data" ;
VAL_TABLE_ PrkBrkVDM 1 "Use Data" 0 "Don't Use Data" ;
VAL_TABLE_ DispMeasSys 1 "English" 0 "Metric" ;
VAL_TABLE_ ACCompModReq 3 "No Action" 2 "Engage" 1 "Disengage" 0 "Disengage Immediately" ;
VAL_TABLE_ TransNtrlCntrlMdStat 3 "Exiting Neutral Control" 2 "Neutral Control Active" 1 "Entering Neutral Control" 0 "Neutral Control Not Active" ;
VAL_TABLE_ ACCompType 4 "Electric Driven Motor" 3 "Variable Displacement Electronic" 2 "Variable Displacement Mechanical" 1 "Fixed Displacement Clutched" 0 "None" ;
VAL_TABLE_ TrnsShftLvrPos 15 "Lever Position Unknown" 11 "Forward Range H" 10 "Forward Range G" 9 "Forward Range F" 8 "Forward Range E" 7 "Forward Range D" 6 "Forward Range C" 5 "Forward Range B" 4 "Forward Range A" 3 "Neutral Range" 2 "Reverse Range" 1 "Park Range" 0 "Between Ranges" ;
VAL_TABLE_ TrnsTrqCnvCltCmndMd 7 "Not Supported" 3 "Locked" 2 "Controlled Slip" 1 "Transitioning" 0 "Unlocked" ;
VAL_TABLE_ AutoTransComndGear 15 "Park Gear" 14 "Reverse Gear" 13 "Neutral Gear" 12 "CVT Forward Gear" 11 "EVT Mode 2" 10 "EVT Mode 1" 8 "Eighth Gear" 7 "Seventh Gear" 6 "Sixth Gear" 5 "Fifth Gear" 4 "Fourth Gear" 3 "Third Gear" 2 "Second Gear" 1 "First Gear" 0 "Not Supported" ;
VAL_TABLE_ AutoTransGrSftDirect 2 "Downshift in Progress" 1 "Upshift in Progress" 0 "No Shift in Progress" ;
VAL_TABLE_ TransEstGear 15 "Park Gear" 14 "Reverse Gear" 13 "Neutral Gear" 12 "CVT Forward Gear" 11 "EVT Mode 2" 10 "EVT Mode 1" 8 "Eighth Gear" 7 "Seventh Gear" 6 "Sixth Gear" 5 "Fifth Gear" 4 "Fourth Gear" 3 "Third Gear" 2 "Second Gear" 1 "First Gear" 0 "Not Supported" ;
VAL_TABLE_ TERDTC_SysDes 15 "U3-Network Codes Reserved" 14 "U2-Network Codes Reserved" 13 "U1-Network Codes MFG Controlled" 12 "U0-Network Codes SAE Controlled" 11 "B3-Body Codes Reserved" 10 "B2-Body Codes Reserved" 9 "B1-Body Codes MFG Controlled" 8 "B0-Body Codes SAE Controlled" 7 "C3-Chassis Codes Reserved" 6 "C2-Chassis Codes Reserved" 5 "C1-Chassis Codes MFG Controlled" 4 "C0-Chassis Codes SAE Controlled" 3 "P3-Powertrain Codes Reserved" 2 "P2-Powertrain Codes Reserved" 1 "P1-Powertrain Codes MFG Controlled" 0 "P0-Powertrain Codes SAE Controlled" ;
VAL_TABLE_ TESR_EngSpdCntlRsp 3 "Stability Optimized Condition 2" 2 "Stability Optimized Condition 1" 1 "Transient Optimized" 0 "No Suggestion" ;
VAL_TABLE_ TESR_EngSpdIntTyp 2 "Engine Speed Min Limit" 1 "Engine Speed Max Limit" 0 "No Intervention" ;
VAL_TABLE_ TTRLT_TqRdnRlznSgg 3 "Stability Optimized 2" 2 "Stability Optimized 1" 1 "Transient Optimized" 0 "No Suggestion" ;
VAL_TABLE_ TTRLT_TorqInvntnTyp 2 "Minimum Limit" 1 "Maximum Limit" 0 "No Intervention" ;
VAL_TABLE_ TTRST_TorqInvntnTyp 1 "Maximum Limit" 0 "No Intervention" ;
VAL_TABLE_ PTORmStMsEngStRq 1 "PTO Remote Start Requested" 0 "PTO Remote Start Not Requested" ;
VAL_TABLE_ PFESpdCmdSwDIntg 2 "Failure Detected" 1 "Data Invalid" 0 "Data Valid" ;
VAL_TABLE_ RmVehStrRq 1 "Remote Start Requested" 0 "Remote Start Not Requested" ;
VAL_TABLE_ VehSpdCntlSystmType 2 "Adaptive Cruise Control" 1 "Conventional Cruise Control" 0 "No Vehicle Speed Control" ;
VAL_TABLE_ PF_MinIdlBstLvlReq 3 "Boost Level 3" 2 "Boost Level 2" 1 "Boost Level 1" 0 "No Boost Requested" ;
VAL_TABLE_ PltfrmEngSpdCmdSysTp 6 "Auto Elevated Idle" 5 "Enhanced Fast Idle" 4 "Fast Idle" 3 "Mobile Variable PTO" 2 "Stationary Variable PTO" 1 "Stationary PTO" 0 "No Platform Eng. Speed Command Sys." ;
VAL_TABLE_ ThrtlPrgrsnReq 2 "Map C" 1 "Map B" 0 "Map A" ;
VAL_TABLE_ PMMAccTrmSt 1 "Active" 0 "Inactive" ;
VAL_TABLE_ PMMRunCrkTrmSt 1 "Active" 0 "Inactive" ;
VAL_TABLE_ SysBkUpPwrMd 3 "Crank Request" 2 "Run" 1 "Accessory" 0 "Off" ;
VAL_TABLE_ SysPwrMd 3 "Crank Request" 2 "Run" 1 "Accessory" 0 "Off" ;
VAL_TABLE_ ImmblzrPreRelPswdStat 1 "Information Valid" 0 "No Information" ;
VAL_TABLE_ AdptCrsGapSwAct 2 "Increase Gap" 1 "Decrease Gap" 0 "No Activation" ;
VAL_TABLE_ CrsCntrlSwStSwDataIntgty 3 "Illegal Range" 2 "Failure Detected" 1 "Data Invalid" 0 "Data Valid" ;
VAL_TABLE_ CrsCntCncRq 1 "Cancel" 0 "Do Not Cancel" ;
VAL_TABLE_ WhlSpdSnsgDTCStat 4 "Diagnostic Failed" 3 "Diagnostic Passed" 2 "No Status to Report" 1 "Critically Disabled" 0 "Not Supported" ;
VAL_TABLE_ SprTireSt 2 "Spare Detected" 1 "No Spare Detected" 0 "Undetermined" ;
VAL_TABLE_ BSTGRReqdGear 8 "Eighth Gear" 7 "Seventh Gear" 6 "Sixth Gear" 5 "Fifth Gear" 4 "Fourth Gear" 3 "Third Gear" 2 "Second Gear" 1 "First Gear" 0 "No Action" ;
VAL_TABLE_ BSTGRReqType 3 "Hold Gear" 2 "Min Gear Request" 1 "Max Gear Request" 0 "No Action" ;
VAL_TABLE_ VhDynCntlSysSt 7 "Driver Disabled" 6 "Enhanced Operation" 5 "Calibrating" 4 "Warming Up" 3 "Permanently Failed" 2 "Temporarily Inhibited" 1 "Reduced Function" 0 "Normal Operation" ;
VAL_TABLE_ TracCntrlSysDrIntnt 1 "Enabled" 0 "Disabled" ;
VAL_TABLE_ ValidityStates 1 "Invalid" 0 "Valid" ;
VAL_TABLE_ MainLghtSw 3 "HEADLAMP" 2 "PARKLAMP" 1 "OFF" 0 "AUTO" ;
VAL_TABLE_ ExhPrsRgVlvPos 1 "Closed" 0 "Open" ;
VAL_TABLE_ CSETRER_TqIntvnTyp 2 "Increase Torque" 1 "Reduce Torque" 0 "No Intervention" ;

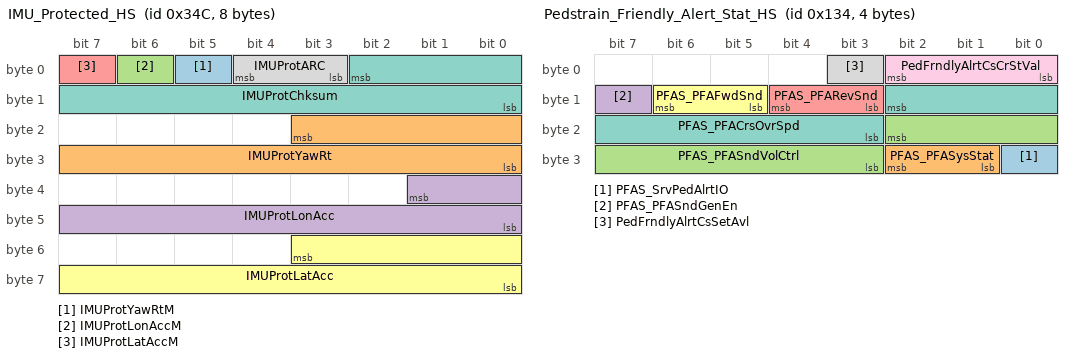
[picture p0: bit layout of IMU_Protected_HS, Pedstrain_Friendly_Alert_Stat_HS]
BO_ 844 IMU_Protected_HS: 8 EBCM_HS
 SG_ IMUProtYawRtM : 5|1@0+ (1,0) [0|1] ""  FCM_HS
 SG_ IMUProtYawRt : 19|12@0- (0.0625,0) [-128|127.9375] "deg/sec"  FCM_HS
 SG_ IMUProtLonAccM : 6|1@0+ (1,0) [0|1] ""  FCM_HS
 SG_ IMUProtLonAcc : 33|10@0- (0.03,0) [-15.36|15.33] "m/s^2"  FCM_HS
 SG_ IMUProtLatAccM : 7|1@0+ (1,0) [0|1] ""  FCM_HS
 SG_ IMUProtLatAcc : 51|12@0- (0.015625,0) [-32|31.984375] "m/s^2"  FCM_HS
 SG_ IMUProtChksum : 2|11@0+ (1,0) [0|2047] ""  FCM_HS
 SG_ IMUProtARC : 4|2@0+ (1,0) [0|3] ""  FCM_HS

BO_ 308 Pedstrain_Friendly_Alert_Stat_HS: 4 PFAF_HS
 SG_ PFAS_SrvPedAlrtIO : 24|1@0+ (1,0) [0|1] ""  BCM_HS
 SG_ PFAS_PFASysStat : 26|2@0+ (1,0) [0|3] ""  BCM_HS
 SG_ PFAS_PFASndVolCtrl : 18|8@0+ (0.392157,0) [0|100.000035] "%"  BCM_HS
 SG_ PFAS_PFASndGenEn : 15|1@0+ (1,0) [0|1] ""  BCM_HS
 SG_ PFAS_PFARevSnd : 12|2@0+ (1,0) [0|3] ""  BCM_HS
 SG_ PFAS_PFAFwdSnd : 14|2@0+ (1,0) [0|3] ""  BCM_HS
 SG_ PFAS_PFACrsOvrSpd : 10|8@0+ (1,0) [0|255] "km/h"  BCM_HS
 SG_ PedFrndlyAlrtCsSetAvl : 3|1@0+ (1,0) [0|1] ""  BCM_HS
 SG_ PedFrndlyAlrtCsCrStVal : 2|3@0+ (1,0) [0|7] ""  BCM_HS

BO_ 806 DC_Converter_Stabilization_HS: 1 DCDC_HS
 SG_ DCCnvStblznErrIO : 0|1@0+ (1,0) [0|1] ""  BCM_HS

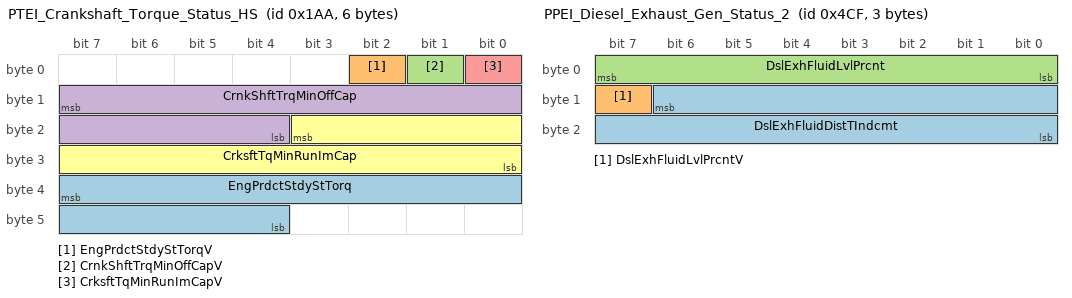
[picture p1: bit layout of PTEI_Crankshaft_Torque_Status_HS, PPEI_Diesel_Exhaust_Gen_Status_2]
BO_ 426 PTEI_Crankshaft_Torque_Status_HS: 6 ECM_HS
 SG_ EngPrdctStdyStTorq : 39|12@0+ (0.5,-848) [-848|1199.5] "Nm"  TCM_HS
 SG_ EngPrdctStdyStTorqV : 2|1@0+ (1,0) [0|1] ""  TCM_HS
 SG_ CrnkShftTrqMinOffCapV : 1|1@0+ (1,0) [0|1] ""  TCM_HS
 SG_ CrnkShftTrqMinOffCap : 15|12@0+ (0.5,-848) [-848|1199.5] "Nm"  TCM_HS
 SG_ CrksftTqMinRunImCapV : 0|1@0+ (1,0) [0|1] ""  TCM_HS
 SG_ CrksftTqMinRunImCap : 19|12@0+ (0.5,-848) [-848|1199.5] "Nm"  TCM_HS

BO_ 1231 PPEI_Diesel_Exhaust_Gen_Status_2: 3 ECM_HS
 SG_ DslExhFluidDistTIndcmt : 14|15@0+ (2,0) [0|65534] "km"  BCM_HS
 SG_ DslExhFluidLvlPrcntV : 15|1@0+ (1,0) [0|1] ""  BCM_HS
 SG_ DslExhFluidLvlPrcnt : 7|8@0+ (0.392157,0) [0|100.000035] "%"  BCM_HS

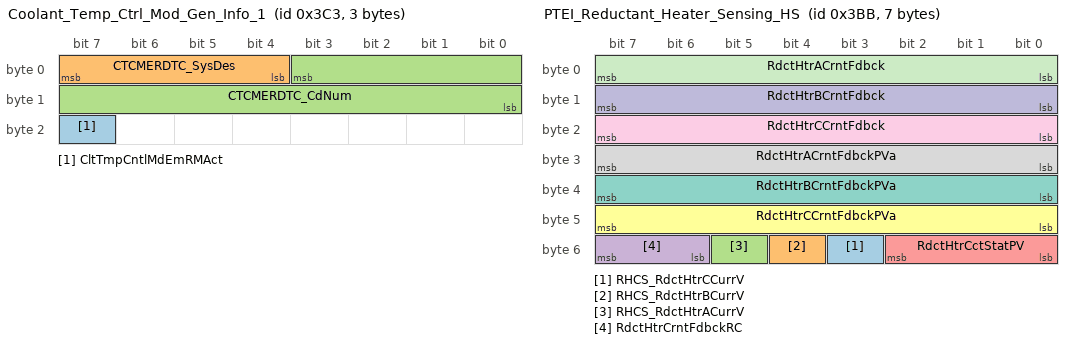
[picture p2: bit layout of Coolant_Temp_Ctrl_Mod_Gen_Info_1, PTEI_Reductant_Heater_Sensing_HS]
BO_ 963 Coolant_Temp_Ctrl_Mod_Gen_Info_1: 3 VICM2_HS
 SG_ CltTmpCntlMdEmRMAct : 23|1@0+ (1,0) [0|1] ""  ECM_HS
 SG_ CTCMERDTC_SysDes : 7|4@0+ (1,0) [0|15] ""  ECM_HS
 SG_ CTCMERDTC_CdNum : 3|12@0+ (1,0) [0|4095] ""  ECM_HS

BO_ 955 PTEI_Reductant_Heater_Sensing_HS: 7 GPCM_HS
 SG_ RHCS_RdctHtrCCurrV : 51|1@0+ (1,0) [0|1] ""  PCM_HS,ECM_HS
 SG_ RHCS_RdctHtrBCurrV : 52|1@0+ (1,0) [0|1] ""  PCM_HS,ECM_HS
 SG_ RHCS_RdctHtrACurrV : 53|1@0+ (1,0) [0|1] ""  PCM_HS,ECM_HS
 SG_ RdctHtrCrntFdbckRC : 55|2@0+ (1,0) [0|3] ""  PCM_HS,ECM_HS
 SG_ RdctHtrCctStatPV : 50|3@0+ (1,0) [0|7] ""  PCM_HS,ECM_HS
 SG_ RdctHtrCCrntFdbckPVa : 47|8@0+ (1,0) [0|255] ""  PCM_HS,ECM_HS
 SG_ RdctHtrBCrntFdbckPVa : 39|8@0+ (1,0) [0|255] ""  PCM_HS,ECM_HS
 SG_ RdctHtrACrntFdbckPVa : 31|8@0+ (1,0) [0|255] ""  PCM_HS,ECM_HS
 SG_ RdctHtrCCrntFdbck : 23|8@0+ (0.117647,0) [0|29.999985] "A"  PCM_HS,ECM_HS
 SG_ RdctHtrBCrntFdbck : 15|8@0+ (0.117647,0) [0|29.999985] "A"  PCM_HS,ECM_HS
 SG_ RdctHtrACrntFdbck : 7|8@0+ (0.117647,0) [0|29.999985] "A"  PCM_HS,ECM_HS

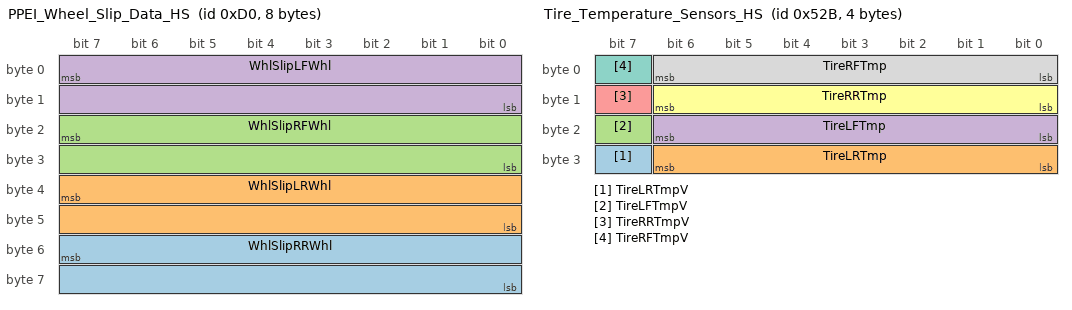
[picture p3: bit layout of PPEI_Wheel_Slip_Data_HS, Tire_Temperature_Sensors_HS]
BO_ 208 PPEI_Wheel_Slip_Data_HS: 8 EBCM_HS
 SG_ WhlSlipRRWhl : 55|16@0+ (0.390625,-12800) [-12800|12799.609375] "%"  TCM_HS
 SG_ WhlSlipLRWhl : 39|16@0+ (0.390625,-12800) [-12800|12799.609375] "%"  TCM_HS
 SG_ WhlSlipRFWhl : 23|16@0+ (0.390625,-12800) [-12800|12799.609375] "%"  TCM_HS
 SG_ WhlSlipLFWhl : 7|16@0+ (0.390625,-12800) [-12800|12799.609375] "%"  TCM_HS

BO_ 2034 CCP_Data_Transmission_Object_HS: 8 PTO_HS
 SG_ DgnInf : 7|64@0+ (1,0) [0|1.844674407371E+019] ""  TestTool_HS

BO_ 2032 CCP_Command_Receive_Object_HS: 8 TestTool_HS
 SG_ DgnInf : 7|64@0+ (1,0) [0|1.844674407371E+019] ""  PTO_HS

BO_ 563 Performance_Mode_Cust_Setings_HS: 5 EBCM_HS
 SG_ SPMCA_SusPrfMd6Avl : 32|1@0+ (1,0) [0|1] ""  BCM_HS
 SG_ SPMCA_SusPrfMd5Avl : 33|1@0+ (1,0) [0|1] ""  BCM_HS
 SG_ SPMCA_SusPrfMd4Avl : 34|1@0+ (1,0) [0|1] ""  BCM_HS
 SG_ SPMCA_SusPrfMd3Avl : 35|1@0+ (1,0) [0|1] ""  BCM_HS
 SG_ SPMCA_SusPrfMd2Avl : 36|1@0+ (1,0) [0|1] ""  BCM_HS
 SG_ SPMCA_SusPrfMd1Avl : 37|1@0+ (1,0) [0|1] ""  BCM_HS
 SG_ SPMCA_StrPrfMd6Avl : 24|1@0+ (1,0) [0|1] ""  BCM_HS
 SG_ SPMCA_StrPrfMd5Avl : 25|1@0+ (1,0) [0|1] ""  BCM_HS
 SG_ SPMCA_StrPrfMd4Avl : 26|1@0+ (1,0) [0|1] ""  BCM_HS
 SG_ SPMCA_StrPrfMd3Avl : 27|1@0+ (1,0) [0|1] ""  BCM_HS
 SG_ SPMCA_StrPrfMd2Avl : 28|1@0+ (1,0) [0|1] ""  BCM_HS
 SG_ SPMCA_StrPrfMd1Avl : 29|1@0+ (1,0) [0|1] ""  BCM_HS
 SG_ SPMCA_SndPrfMd6Avl : 16|1@0+ (1,0) [0|1] ""  BCM_HS
 SG_ SPMCA_SndPrfMd5Avl : 17|1@0+ (1,0) [0|1] ""  BCM_HS
 SG_ SPMCA_SndPrfMd4Avl : 18|1@0+ (1,0) [0|1] ""  BCM_HS
 SG_ SPMCA_SndPrfMd3Avl : 19|1@0+ (1,0) [0|1] ""  BCM_HS
 SG_ SPMCA_SndPrfMd2Avl : 20|1@0+ (1,0) [0|1] ""  BCM_HS
 SG_ SPMCA_SndPrfMd1Avl : 21|1@0+ (1,0) [0|1] ""  BCM_HS
 SG_ DPMCA_DispPrfMd6Avl : 8|1@0+ (1,0) [0|1] ""  BCM_HS
 SG_ DPMCA_DispPrfMd5Avl : 9|1@0+ (1,0) [0|1] ""  BCM_HS
 SG_ DPMCA_DispPrfMd4Avl : 10|1@0+ (1,0) [0|1] ""  BCM_HS
 SG_ DPMCA_DispPrfMd3Avl : 11|1@0+ (1,0) [0|1] ""  BCM_HS
 SG_ DPMCA_DispPrfMd2Avl : 12|1@0+ (1,0) [0|1] ""  BCM_HS
 SG_ DPMCA_DispPrfMd1Avl : 13|1@0+ (1,0) [0|1] ""  BCM_HS
 SG_ DPMCA_DrvlPrfMd6Avl : 0|1@0+ (1,0) [0|1] ""  BCM_HS
 SG_ DPMCA_DrvlPrfMd5Avl : 1|1@0+ (1,0) [0|1] ""  BCM_HS
 SG_ DPMCA_DrvlPrfMd4Avl : 2|1@0+ (1,0) [0|1] ""  BCM_HS
 SG_ DPMCA_DrvlPrfMd3Avl : 3|1@0+ (1,0) [0|1] ""  BCM_HS
 SG_ DPMCA_DrvlPrfMd2Avl : 4|1@0+ (1,0) [0|1] ""  BCM_HS
 SG_ DPMCA_DrvlPrfMd1Avl : 5|1@0+ (1,0) [0|1] ""  BCM_HS

BO_ 1323 Tire_Temperature_Sensors_HS: 4 BCM_HS
 SG_ TireLRTmpV : 31|1@0+ (1,0) [0|1] ""  LVMPC_HS,EDI_HS,EBCM_OBD_HS,EBCM_HS,ICCM_OBD_HS,ICCM_HS,RDCM_HS
 SG_ TireLRTmp : 30|7@0+ (1,-20) [-20|107] "deg C"  LVMPC_HS,EDI_HS,EBCM_OBD_HS,EBCM_HS,ICCM_OBD_HS,ICCM_HS,RDCM_HS
 SG_ TireLFTmpV : 23|1@0+ (1,0) [0|1] ""  LVMPC_HS,EDI_HS,EBCM_OBD_HS,EBCM_HS,ICCM_OBD_HS,ICCM_HS,RDCM_HS
 SG_ TireLFTmp : 22|7@0+ (1,-20) [-20|107] "deg C"  LVMPC_HS,EDI_HS,EBCM_OBD_HS,EBCM_HS,ICCM_OBD_HS,ICCM_HS,RDCM_HS
 SG_ TireRRTmpV : 15|1@0+ (1,0) [0|1] ""  LVMPC_HS,EDI_HS,EBCM_OBD_HS,EBCM_HS,ICCM_OBD_HS,ICCM_HS,RDCM_HS
 SG_ TireRRTmp : 14|7@0+ (1,-20) [-20|107] "deg C"  LVMPC_HS,EDI_HS,EBCM_OBD_HS,EBCM_HS,ICCM_OBD_HS,ICCM_HS,RDCM_HS
 SG_ TireRFTmpV : 7|1@0+ (1,0) [0|1] ""  LVMPC_HS,EDI_HS,EBCM_OBD_HS,EBCM_HS,ICCM_OBD_HS,ICCM_HS,RDCM_HS
 SG_ TireRFTmp : 6|7@0+ (1,-20) [-20|107] "deg C"  LVMPC_HS,EDI_HS,EBCM_OBD_HS,EBCM_HS,ICCM_OBD_HS,ICCM_HS,RDCM_HS

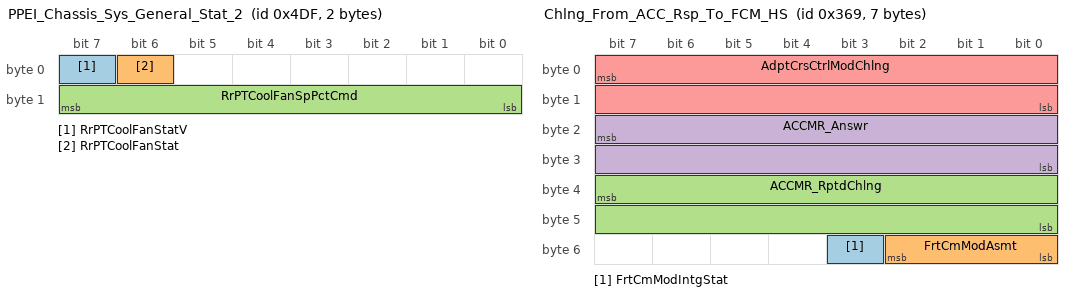
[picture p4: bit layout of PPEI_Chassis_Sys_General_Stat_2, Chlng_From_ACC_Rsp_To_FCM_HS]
BO_ 1247 PPEI_Chassis_Sys_General_Stat_2: 2 ICCM_HS
 SG_ RrPTCoolFanStatV : 7|1@0+ (1,0) [0|2] ""  TCM_HS
 SG_ RrPTCoolFanStat : 6|1@0+ (1,0) [0|1] ""  TCM_HS
 SG_ RrPTCoolFanSpPctCmd : 15|8@0+ (0.392157,0) [0|100.000035] "%"  TCM_HS

BO_ 873 Chlng_From_ACC_Rsp_To_FCM_HS: 7 ACC_HS
 SG_ FrtCmModIntgStat : 51|1@0+ (1,0) [0|1] ""  FCM_HS
 SG_ FrtCmModAsmt : 50|3@0+ (1,0) [0|7] ""  FCM_HS
 SG_ ACCMR_RptdChlng : 39|16@0+ (1,0) [0|65535] ""  FCM_HS
 SG_ ACCMR_Answr : 23|16@0+ (1,0) [0|65535] ""  FCM_HS
 SG_ AdptCrsCtrlModChlng : 7|16@0+ (1,0) [0|65535] ""  FCM_HS

BO_ 306 Exhst_Heat_Recvry_Mngmnt_HS: 1 VICM2_HS
 SG_ ClntCrcFlwRtEst : 7|8@0+ (0.392157,0) [0|100.000035] "%"  BCM_HS

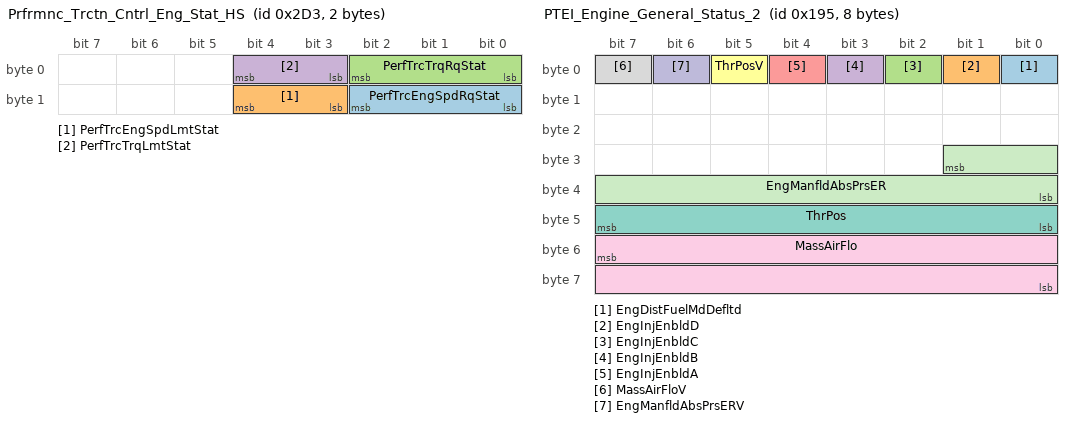
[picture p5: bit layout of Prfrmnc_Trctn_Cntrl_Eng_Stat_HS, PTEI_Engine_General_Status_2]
BO_ 723 Prfrmnc_Trctn_Cntrl_Eng_Stat_HS: 2 ECM_HS
 SG_ PerfTrcEngSpdRqStat : 10|3@0+ (1,0) [0|7] ""  EBCM_OBD_HS,EBCM_HS,PTAM_HS
 SG_ PerfTrcEngSpdLmtStat : 12|2@0+ (1,0) [0|3] ""  EBCM_OBD_HS,EBCM_HS,PTAM_HS
 SG_ PerfTrcTrqRqStat : 2|3@0+ (1,0) [0|7] ""  EBCM_OBD_HS,EBCM_HS,PTAM_HS
 SG_ PerfTrcTrqLmtStat : 4|2@0+ (1,0) [0|3] ""  EBCM_OBD_HS,EBCM_HS,PTAM_HS

BO_ 405 PTEI_Engine_General_Status_2: 8 ECM_HS
 SG_ EngDistFuelMdDefltd : 0|1@0+ (1,0) [0|1] ""  FICM_HS
 SG_ EngInjEnbldD : 1|1@0+ (1,0) [0|1] ""  FICM_HS
 SG_ EngInjEnbldC : 2|1@0+ (1,0) [0|1] ""  FICM_HS
 SG_ EngInjEnbldB : 3|1@0+ (1,0) [0|1] ""  FICM_HS
 SG_ EngInjEnbldA : 4|1@0+ (1,0) [0|1] ""  FICM_HS
 SG_ ThrPosV : 5|1@0+ (1,0) [0|1] ""  FICM_HS
 SG_ ThrPos : 47|8@0+ (0.392157,0) [0|100.000035] "%"  FICM_HS
 SG_ MassAirFloV : 7|1@0+ (1,0) [0|1] ""  VCM_HS,FICM_HS
 SG_ MassAirFlo : 55|16@0+ (0.01,0) [0|655.35] "grams/s"  VCM_HS,FICM_HS
 SG_ EngManfldAbsPrsERV : 6|1@0+ (1,0) [0|1] ""  FICM_HS
 SG_ EngManfldAbsPrsER : 25|10@0+ (0.5,0) [0|511.5] "kPa"  FICM_HS

BO_ 419 PTEI_Engine_Common_Use_1: 1 ECM_HS
 SG_ EngRunng : 7|1@0+ (1,0) [0|1] ""  BCM_HS,DCDC_HS,TCCM_HS,EBCM_OBD_HS,EBCM_HS,OBCM_HS,MCP_C_HS,MCP_B_HS,MCP_A_HS,FICM_HS,TCM_HS,HCP_HS,BCP_HS

BO_ 289 ADASIS_RawData_Multiplexed_HS: 8 HMIM_HS
 SG_ ARDM_RawData : 4|61@0+ (1,0) [0|2.3058430092137E+018] ""  Dummy_HS
 SG_ ARDM_MsgType : 7|3@0+ (1,0) [0|7] ""  Dummy_HS

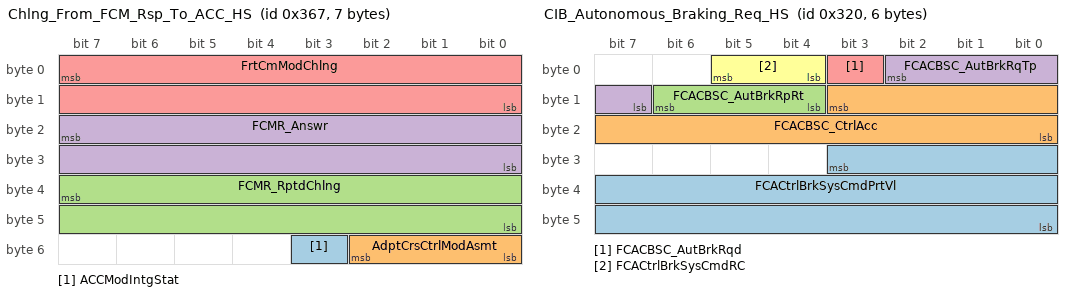
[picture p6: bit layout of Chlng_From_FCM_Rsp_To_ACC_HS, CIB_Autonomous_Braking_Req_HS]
BO_ 871 Chlng_From_FCM_Rsp_To_ACC_HS: 7 FCM_HS
 SG_ ACCModIntgStat : 51|1@0+ (1,0) [0|1] ""  ACC_HS
 SG_ AdptCrsCtrlModAsmt : 50|3@0+ (1,0) [0|7] ""  ACC_HS
 SG_ FCMR_RptdChlng : 39|16@0+ (1,0) [0|65535] ""  ACC_HS
 SG_ FCMR_Answr : 23|16@0+ (1,0) [0|65535] ""  ACC_HS
 SG_ FrtCmModChlng : 7|16@0+ (1,0) [0|65535] ""  ACC_HS

BO_ 800 CIB_Autonomous_Braking_Req_HS: 6 FCM_HS
 SG_ FCACtrlBrkSysCmdPrtVl : 27|20@0+ (1,0) [0|1048575] ""  EBCM_OBD_HS,EBCM_HS
 SG_ FCACBSC_CtrlAcc : 11|12@0- (0.01,0) [-20.48|20.47] "m/s^2"  EBCM_OBD_HS,EBCM_HS
 SG_ FCACBSC_AutBrkRpRt : 14|3@0+ (1,0) [0|7] ""  EBCM_OBD_HS,EBCM_HS
 SG_ FCACBSC_AutBrkRqTp : 2|4@0+ (1,0) [0|15] ""  EBCM_OBD_HS,EBCM_HS
 SG_ FCACBSC_AutBrkRqd : 3|1@0+ (1,0) [0|1] ""  EBCM_OBD_HS,EBCM_HS
 SG_ FCACtrlBrkSysCmdRC : 5|2@0+ (1,0) [0|3] ""  EBCM_OBD_HS,EBCM_HS

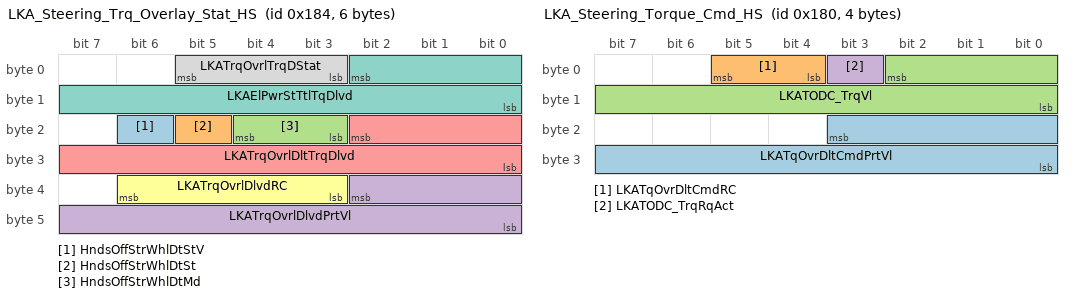
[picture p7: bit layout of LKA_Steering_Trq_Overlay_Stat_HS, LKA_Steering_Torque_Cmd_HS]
BO_ 388 LKA_Steering_Trq_Overlay_Stat_HS: 6 EPS_HS
 SG_ HndsOffStrWhlDtStV : 22|1@0+ (1,0) [0|1] ""  FCM_HS
 SG_ HndsOffStrWhlDtSt : 21|1@0+ (1,0) [0|1] ""  FCM_HS
 SG_ HndsOffStrWhlDtMd : 20|2@0+ (1,0) [0|3] ""  FCM_HS
 SG_ LKATrqOvrlDlvdPrtVl : 34|11@0+ (1,0) [0|2047] ""  FCM_HS
 SG_ LKATrqOvrlDltTrqDlvd : 18|11@0- (0.01,0) [-10.24|10.23] "Nm"  FCM_HS
 SG_ LKATrqOvrlDlvdRC : 38|4@0+ (1,0) [0|15] ""  FCM_HS
 SG_ LKAElPwrStTtlTqDlvd : 2|11@0- (0.01,0) [-10.24|10.23] "Nm"  FCM_HS
 SG_ LKATrqOvrlTrqDStat : 5|3@0+ (1,0) [0|7] ""  FCM_HS

BO_ 384 LKA_Steering_Torque_Cmd_HS: 4 FCM_HS
 SG_ LKATqOvrDltCmdPrtVl : 19|12@0+ (1,0) [0|4095] ""  EPS_HS
 SG_ LKATqOvrDltCmdRC : 5|2@0+ (1,0) [0|3] ""  EPS_HS
 SG_ LKATODC_TrqVl : 2|11@0- (0.01,0) [-10.24|10.23] "Nm"  EPS_HS
 SG_ LKATODC_TrqRqAct : 3|1@0+ (1,0) [0|1] ""  EPS_HS

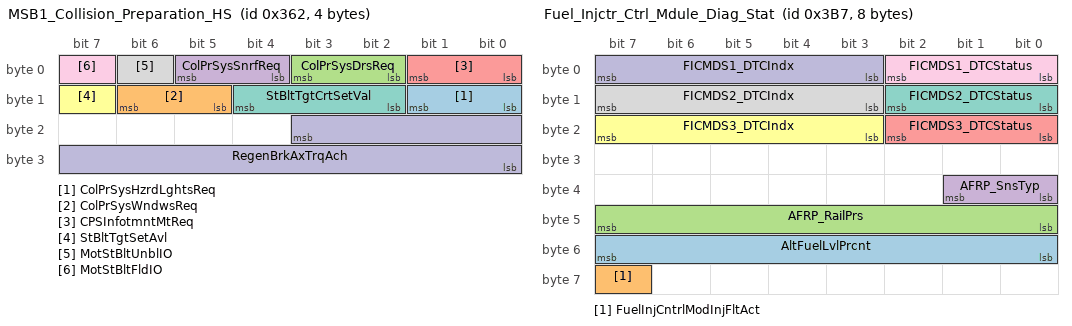
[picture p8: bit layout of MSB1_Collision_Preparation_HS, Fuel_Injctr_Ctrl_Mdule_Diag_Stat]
BO_ 866 MSB1_Collision_Preparation_HS: 4 EBCM_HS
 SG_ ColPrSysHzrdLghtsReq : 9|2@0+ (1,0) [0|3] ""  BCM_HS
 SG_ ColPrSysWndwsReq : 14|2@0+ (1,0) [0|3] ""  BCM_HS
 SG_ ColPrSysDrsReq : 3|2@0+ (1,0) [0|3] ""  BCM_HS
 SG_ ColPrSysSnrfReq : 5|2@0+ (1,0) [0|3] ""  BCM_HS
 SG_ CPSInfotmntMtReq : 1|2@0+ (1,0) [0|3] ""  BCM_HS
 SG_ StBltTgtSetAvl : 15|1@0+ (1,0) [0|1] ""  BCM_HS
 SG_ StBltTgtCrtSetVal : 12|3@0+ (1,0) [0|7] ""  BCM_HS
 SG_ MotStBltUnblIO : 6|1@0+ (1,0) [0|1] ""  BCM_HS
 SG_ MotStBltFldIO : 7|1@0+ (1,0) [0|1] ""  BCM_HS
 SG_ RegenBrkAxTrqAch : 19|12@0+ (2,0) [0|8190] "Nm"  VICM_HS

BO_ 951 Fuel_Injctr_Ctrl_Mdule_Diag_Stat: 8 FICM_HS
 SG_ AltFuelLvlPrcnt : 55|8@0+ (0.392157,0) [0|100.000035] "%"  ECM_HS
 SG_ FuelInjCntrlModInjFltAct : 63|1@0+ (1,0) [0|1] ""  ECM_HS
 SG_ AFRP_RailPrs : 47|8@0+ (3,0) [0|765] "kPa"  ECM_HS
 SG_ AFRP_SnsTyp : 33|2@0+ (1,0) [0|3] ""  ECM_HS
 SG_ FICMDS3_DTCStatus : 18|3@0+ (1,0) [0|7] ""  ECM_HS
 SG_ FICMDS3_DTCIndx : 23|5@0+ (1,0) [0|31] ""  ECM_HS
 SG_ FICMDS2_DTCStatus : 10|3@0+ (1,0) [0|7] ""  ECM_HS
 SG_ FICMDS2_DTCIndx : 15|5@0+ (1,0) [0|31] ""  ECM_HS
 SG_ FICMDS1_DTCStatus : 2|3@0+ (1,0) [0|7] ""  ECM_HS
 SG_ FICMDS1_DTCIndx : 7|5@0+ (1,0) [0|31] ""  ECM_HS

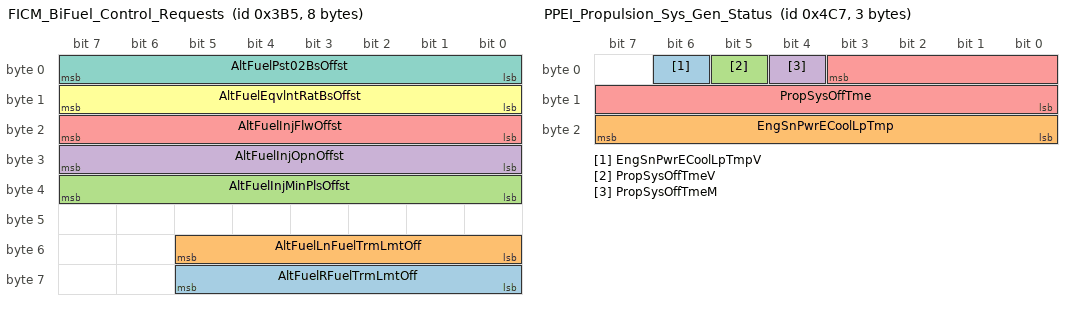
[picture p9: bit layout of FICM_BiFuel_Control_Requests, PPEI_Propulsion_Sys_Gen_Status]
BO_ 949 FICM_BiFuel_Control_Requests: 8 FICM_HS
 SG_ AltFuelRFuelTrmLmtOff : 61|6@0- (0.01,0) [-0.32|0.31] ""  ECM_HS
 SG_ AltFuelLnFuelTrmLmtOff : 53|6@0- (0.01,0) [-0.32|0.31] ""  ECM_HS
 SG_ AltFuelInjMinPlsOffst : 39|8@0- (0.0313725,0) [-4.01568|3.9843075] "grams/s"  ECM_HS
 SG_ AltFuelInjOpnOffst : 31|8@0- (0.0313725,0) [-4.01568|3.9843075] "grams/s"  ECM_HS
 SG_ AltFuelInjFlwOffst : 23|8@0- (0.0313725,0) [-4.01568|3.9843075] "grams/s"  ECM_HS
 SG_ AltFuelEqvlntRatBsOffst : 15|8@0- (0.000392157,0) [-0.050196096|0.049803939] ""  ECM_HS
 SG_ AltFuelPst02BsOffst : 7|8@0- (4,0) [-512|508] "mVolts"  ECM_HS

BO_ 1223 PPEI_Propulsion_Sys_Gen_Status: 3 ECM_HS
 SG_ EngSnPwrECoolLpTmpV : 6|1@0+ (1,0) [0|1] ""  VICM_HS
 SG_ EngSnPwrECoolLpTmp : 23|8@0+ (1,-40) [-40|215] "deg C"  VICM_HS
 SG_ PropSysOffTmeV : 5|1@0+ (1,0) [0|1] ""  VICM2_HS,EBCM_OBD_HS,EBCM_HS,MCP_C_HS,TCM_HS,HCP_HS,BCP_HS,MCP_B_HS,MCP_A_HS,VICM_HS
 SG_ PropSysOffTmeM : 4|1@0+ (1,0) [0|1] ""  VICM2_HS,EBCM_OBD_HS,EBCM_HS,MCP_C_HS,TCM_HS,HCP_HS,BCP_HS,MCP_B_HS,MCP_A_HS,VICM_HS
 SG_ PropSysOffTme : 3|12@0+ (0.5,0) [0|2047.5] "min"  VICM2_HS,EBCM_OBD_HS,EBCM_HS,MCP_C_HS,TCM_HS,HCP_HS,BCP_HS,MCP_B_HS,MCP_A_HS,VICM_HS

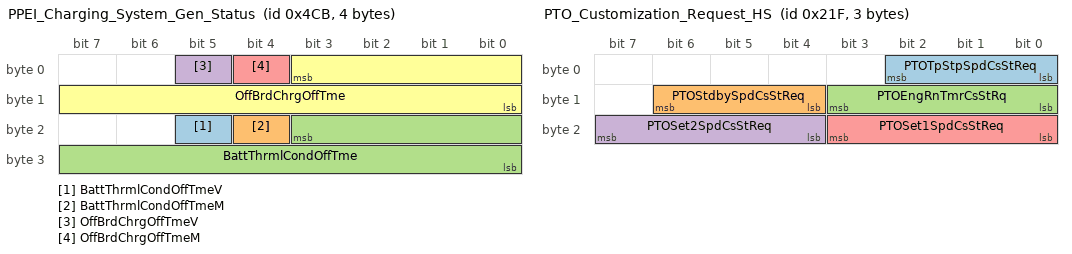
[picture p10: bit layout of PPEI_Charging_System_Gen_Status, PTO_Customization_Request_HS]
BO_ 1227 PPEI_Charging_System_Gen_Status: 4 VICM_HS
 SG_ BattThrmlCondOffTmeV : 21|1@0+ (1,0) [0|1] ""  MCP_C_HS,TCM_HS,HCP_HS,MCP_B_HS,MCP_A_HS,PCM_HS,ECM_HS
 SG_ BattThrmlCondOffTmeM : 20|1@0+ (1,0) [0|1] ""  MCP_C_HS,TCM_HS,HCP_HS,MCP_B_HS,MCP_A_HS,PCM_HS,ECM_HS
 SG_ BattThrmlCondOffTme : 19|12@0+ (0.5,0) [0|2047.5] "min"  MCP_C_HS,TCM_HS,HCP_HS,MCP_B_HS,MCP_A_HS,PCM_HS,ECM_HS
 SG_ OffBrdChrgOffTmeV : 5|1@0+ (1,0) [0|1] ""  MCP_C_HS,TCM_HS,HCP_HS,MCP_B_HS,MCP_A_HS,PCM_HS,ECM_HS
 SG_ OffBrdChrgOffTmeM : 4|1@0+ (1,0) [0|1] ""  MCP_C_HS,TCM_HS,HCP_HS,MCP_B_HS,MCP_A_HS,PCM_HS,ECM_HS
 SG_ OffBrdChrgOffTme : 3|12@0+ (0.5,0) [0|2047.5] "min"  MCP_C_HS,TCM_HS,HCP_HS,MCP_B_HS,MCP_A_HS,PCM_HS,ECM_HS

BO_ 543 PTO_Customization_Request_HS: 3 BCM_HS
 SG_ PTOTpStpSpdCsStReq : 2|3@0+ (1,0) [0|7] ""  PTO_HS
 SG_ PTOStdbySpdCsStReq : 14|3@0+ (1,0) [0|7] ""  PTO_HS
 SG_ PTOEngRnTmrCsStRq : 11|4@0+ (1,0) [0|15] ""  PTO_HS
 SG_ PTOSet2SpdCsStReq : 23|4@0+ (1,0) [0|15] ""  PTO_HS
 SG_ PTOSet1SpdCsStReq : 19|4@0+ (1,0) [0|15] ""  PTO_HS

BO_ 544 PTO_Status_HS: 5 PTO_HS
 SG_ PTOAudExtAlertReq : 19|1@0+ (1,0) [0|1] ""  BCM_HS
 SG_ PTOTransInGearIO : 13|1@0+ (1,0) [0|1] ""  BCM_HS
 SG_ PTOTpStpSpdCsStAvl : 10|1@0+ (1,0) [0|1] ""  BCM_HS
 SG_ PTOTpStSpdCsCrStVal : 26|3@0+ (1,0) [0|7] ""  BCM_HS
 SG_ PTOStdbySpdCsStAvl : 12|1@0+ (1,0) [0|1] ""  BCM_HS
 SG_ PTOStdbSpdCsCrStVal : 18|3@0+ (1,0) [0|7] ""  BCM_HS
 SG_ PTOSetPrkBrkIO : 14|1@0+ (1,0) [0|1] ""  BCM_HS
 SG_ PTOSet2SpdCsStAvl : 9|1@0+ (1,0) [0|1] ""  BCM_HS
 SG_ PTOSet2SpdCsCrStVal : 39|4@0+ (1,0) [0|15] ""  BCM_HS
 SG_ PTOSet1SpdCsStAvl : 8|1@0+ (1,0) [0|1] ""  BCM_HS
 SG_ PTOSet1SpdCsCrStVal : 35|4@0+ (1,0) [0|15] ""  BCM_HS
 SG_ PTORelCltPedIO : 15|1@0+ (1,0) [0|1] ""  BCM_HS
 SG_ PTORelBrkPedIO : 0|1@0+ (1,0) [0|1] ""  BCM_HS
 SG_ PTORelAccPedIO : 1|1@0+ (1,0) [0|1] ""  BCM_HS
 SG_ PTORedEngSpdIO : 2|1@0+ (1,0) [0|1] ""  BCM_HS
 SG_ PTOPrsRelCltPedIO : 3|1@0+ (1,0) [0|1] ""  BCM_HS
 SG_ PTOPrsRelBrkPedIO : 4|1@0+ (1,0) [0|1] ""  BCM_HS
 SG_ PTOEngRnTmrCsStAvl : 11|1@0+ (1,0) [0|1] ""  BCM_HS
 SG_ PTOEnRnTmCsCrStVal : 30|4@0+ (1,0) [0|15] ""  BCM_HS
 SG_ PTOEngmntStatInd : 6|2@0+ (1,0) [0|3] ""  BCM_HS
 SG_ PTODisengCrsCntlIO : 7|1@0+ (1,0) [0|1] ""  BCM_HS

BO_TX_BU_ 844 : EBCM_OBD_HS,EBCM_HS;
BO_TX_BU_ 426 : PCM_HS,ECM_HS;
BO_TX_BU_ 208 : EBCM_OBD_HS,EBCM_HS;
BO_TX_BU_ 563 : EBCM_OBD_HS,EBCM_HS;
BO_TX_BU_ 1247 : ICCM_OBD_HS,ICCM_HS;
BO_TX_BU_ 419 : PCM_HS,ECM_HS;
BO_TX_BU_ 866 : EBCM_OBD_HS,EBCM_HS;
BO_TX_BU_ 951 : VCM_HS,FICM_HS;
BO_TX_BU_ 1223 : PCM_HS,ECM_HS;

CM_ "Primary High Speed GMLAN";
CM_ BU_ PFAF_HS "Pedestrian Friendly Alert Function";
CM_ BU_ LVMPC_HS "Low Volume Module (Performance Computer )";
CM_ BU_ DCDC_HS "DC/DC Converter";
CM_ BU_ AMP_HS "Audio Amplifier";
CM_ BU_ VICM2_HS "Vehicle Integration Control Module 2 (CTCM - Coolant Temperature Control Module)";
CM_ BU_ FICM_HS "Fuel Injection Control Module";
CM_ BU_ ARS_HS "Active Rear Steering";
CM_ BU_ MCP_B_HS "Motor Control Processor B(part of TPIM-Traction Powertrain Inverter Module)";
CM_ BU_ MCP_A_HS "Motor Control Processor A(part of TPIM-Traction Powertrain Inverter Module)";
CM_ BU_ ICCM_OBD_HS "Integrated Chassis Control Module";
CM_ BU_ SAS_HS "Steering Angle Sensor";
CM_ BU_ ACCM_HS "Air Conditioning Control Module";
CM_ BU_ VLBS_HS "Vehicle Location & Blocking System";
CM_ BU_ EBCM_OBD_HS "Electronic Brake Control Module";
CM_ BU_ EDI_HS "Enhanced Driver Interface";
CM_ BU_ HPCC_HS "High Power Charging Contactor";
CM_ BU_ VITM_OBD_HS "Voltage, Current, Temperature Module BAS+";
CM_ BU_ PTAM_HS "Perfomance Traction Algorithm Module";
CM_ BU_ OBCM_HS "On Board Charger Module";
CM_ BU_ VICM_HS "Vehicle Integration Control Module 4Mode";
CM_ BU_ HCP_HS "Hybrid Control Processor";
CM_ BU_ FDCM_HS "Front Drive Control Module";
CM_ BU_ APPS_HS "Active Pedestrian Protection System";
CM_ BU_ ICCM_HS "Integrated Chassis Control Module";
CM_ BU_ EOCM_F_HS "External Object Control Module - Front";
CM_ BU_ GPCM_HS "Glow Plug Control Module";
CM_ BU_ FSCM_ITBC_HS "Fuel System Control Module";
CM_ BU_ SCM_HS "Supervisory Control";
CM_ BU_ ITBC_HS "Integrated Trail Brake Control";
CM_ BU_ VCM_HS "Vaporizer Control Module";
CM_ BU_ HMIM_HS "Next-Gen Infotainment HMIModule ";
CM_ BU_ FCP_HS "Flexible Compute Platform";
CM_ BU_ VES_HS "Variable Effort Steering";
CM_ BU_ Dummy_HS "This is for avoid signle ended signalling";
CM_ BU_ MCP_C_HS "Motor control processor C";
CM_ BU_ RWS_HS "Rear Wheel Steer";
CM_ BU_ ONSTAR_HS "OnStar Module";
CM_ BU_ EPS_HS "Electronic Power Steering";
CM_ BU_ MCP_HS "Motor Control Processor";
CM_ BU_ BCP_HS "BAS+";
CM_ BU_ ALC_HS "Automatic Level Control";
CM_ BU_ AHL_AFL_HS "Automatic Headlamp Levelling";
CM_ BU_ SADS_HS "Semi Active Damping System";
CM_ BU_ EPB_HS "Electronic Park Brake";
CM_ BU_ FSCM_HS "Fuel System Control Module";
CM_ BU_ AFS_HS "Active Front Steering";
CM_ BU_ FCM_HS "Front Camera Module";
CM_ BU_ TCCM_HS "Transfer Case Control Module";
CM_ BU_ RDCM_HS "Rear Drive Control Module";
CM_ BU_ PTO_HS "Power TakeOff Module";
CM_ BU_ PCM_HS "Engine Control Module";
CM_ BU_ EBCM_HS "Electronic Brake Control Module";
CM_ BU_ ACC_HS "Adaptive Cruise Control";
CM_ BU_ BCM_HS "HS Side Global Architecture Gateway and Body Control Module";
CM_ BU_ TCM_HS "Transmission Control Module";
CM_ BU_ ECM_HS "Engine Control Module";
CM_ SG_ 949 AltFuelEqvlntRatBsOffst "Units = Equivalence Ratio";
BA_DEF_  "BusType" STRING ;
BA_DEF_ SG_  "VNSigSLHS_VNReq" ENUM  "No","Yes";
BA_DEF_ SG_  "VNSigSLHSSharedDiagnostic" ENUM  "No","Yes";
BA_DEF_ SG_  "SignalType" STRING ;
BA_DEF_ SG_  "PacketOrder" INT 0 65535;
BA_DEF_ SG_  "SignalLongName" STRING ;
BA_DEF_ SG_  "GenSigStartValue" INT 0 65535;
BA_DEF_ SG_  "VNSigAllNodes" ENUM  "No","Yes";
BA_DEF_ SG_  "GenSigDeltaValue" INT 0 0;
BA_DEF_ SG_  "GenSigSendType" ENUM  "not used","not used","not used","not used","not used","not used","not used","NoSigSendType","not used","not used","OnAnyChange","OnChangeIfActive","OnDelta";
BA_DEF_ SG_  "GenSigSendOnInit" ENUM  "Not Initialized","Application","Handler";
BA_DEF_ BO_  "AppGenMsgCycleTime" INT 0 0;
BA_DEF_ BO_  "GenMsgILSupport" ENUM  "No","Yes";
BA_DEF_ BO_  "TpApplType" STRING ;
BA_DEF_ BO_  "Prio" INT 0 7;
BA_DEF_ BO_  "MessageSubnet" ENUM  "LS","MS","HS","CE","PE","HV","FO";
BA_DEF_ BO_  "DiagState" ENUM  "No","Yes";
BA_DEF_ BO_  "GenMsgDelayTime" INT 0 100000;
BA_DEF_ BO_  "GenMsgCycleTime" INT 0 100000;
BA_DEF_ BO_  "GenMsgSendType" ENUM  "cyclicX","spontanX","cyclicIfActiveX","spontanWithDelay","cyclicAndSpontanX","cyclicAndSpontanWithDelay","spontanWithRepitition","cyclicIfActiveAndSpontanWD";
BA_DEF_ BO_  "DiagResponse" ENUM  "No","Yes";
BA_DEF_ BO_  "DiagRequest" ENUM  "No","Yes";
BA_DEF_ BO_  "NmMessage" ENUM  "No","Yes";
BA_DEF_ BU_  "MessageManagerUsed" ENUM  "No","Yes";
BA_DEF_ BU_  "NmNode" ENUM  "No","Yes";
BA_DEF_ BU_  "ILUsed" ENUM  "No","Yes";
BA_DEF_ BU_  "NodeLayerModules" STRING ;
BA_DEF_ BU_  "VNECUSLHS_VNReq" ENUM  "None","Activator","Remoted","Activator and Remoted","Shared Local";
BA_DEF_ BU_  "VNECUSLHSSharedDiagnostic" ENUM  "None","Activator","Remoted","Activator and Remoted","Shared Local";
BA_DEF_ BU_  "D22_FRdDataByPID" ENUM  "No","Yes";
BA_DEF_ BU_  "D22_N12" ENUM  "No","Yes";
BA_DEF_ BU_  "D22_ReqType" ENUM  "Functional","Physical","Both";
BA_DEF_ BU_  "D2D_ReqType" ENUM  "Functional","Physical","Both";
BA_DEF_ BU_  "DAE_ReqType" ENUM  "Functional","Physical","Both";
BA_DEF_ BU_  "DAE_NE3" ENUM  "No","Yes";
BA_DEF_ BU_  "DAE_N78" ENUM  "No","Yes";
BA_DEF_ BU_  "DAE_N31" ENUM  "No","Yes";
BA_DEF_ BU_  "DAE_N12" ENUM  "No","Yes";
BA_DEF_ BU_  "DAE_FDevCtrl" ENUM  "No","Yes","vector_leerstring";
BA_DEF_ BU_  "DAA_ReqType" ENUM  "Functional","Physical","Both";
BA_DEF_ BU_  "DAA_N81" ENUM  "No","Yes";
BA_DEF_ BU_  "DAA_N78" ENUM  "No","Yes";
BA_DEF_ BU_  "DAA_N31" ENUM  "No","Yes";
BA_DEF_ BU_  "DAA_N12" ENUM  "No","Yes";
BA_DEF_ BU_  "DAA_L04_FastRate" ENUM  "No","Yes";
BA_DEF_ BU_  "DAA_L03_MedRate" ENUM  "No","Yes";
BA_DEF_ BU_  "DAA_L02_SlowRate" ENUM  "No","Yes";
BA_DEF_ BU_  "DAA_L01_SndOneRsp" ENUM  "No","Yes";
BA_DEF_ BU_  "DAA_L00_StopSnd" ENUM  "No","Yes";
BA_DEF_ BU_  "DAA_FRdDPID" ENUM  "No","Yes","vector_leerstring";
BA_DEF_ BU_  "DA9_ReqType" ENUM  "Functional","Physical","Both";
BA_DEF_ BU_  "DA9_N78" ENUM  "No","Yes";
BA_DEF_ BU_  "DA9_N31" ENUM  "No","Yes";
BA_DEF_ BU_  "DA9_N12" ENUM  "No","Yes";
BA_DEF_ BU_  "DA9_L82_SndChgDTC" ENUM  "No","Yes";
BA_DEF_ BU_  "DA9_L81_RdStatDTCbyMsk" ENUM  "No","Yes";
BA_DEF_ BU_  "DA9_L80_RdStatDTCbyNum" ENUM  "No","Yes";
BA_DEF_ BU_  "DA9_FRdDiagInfo" ENUM  "No","Yes","vector_leerstring";
BA_DEF_ BU_  "DA5_ReqType" ENUM  "Functional","Physical","Both";
BA_DEF_ BU_  "DA5_N78" ENUM  "No","Yes";
BA_DEF_ BU_  "DA5_N22" ENUM  "No","Yes";
BA_DEF_ BU_  "DA5_N12" ENUM  "No","Yes";
BA_DEF_ BU_  "DA5_L03_EnabProgMode" ENUM  "No","Yes";
BA_DEF_ BU_  "DA5_L01_ReqProgMode" ENUM  "No","Yes";
BA_DEF_ BU_  "DA5_FProgMode" ENUM  "No","Yes","vector_leerstring";
BA_DEF_ BU_  "DA2_ReqType" ENUM  "Functional","Physical","Both";
BA_DEF_ BU_  "DA2_N78" ENUM  "No","Yes";
BA_DEF_ BU_  "DA2_N12" ENUM  "No","Yes";
BA_DEF_ BU_  "DA2_FRptPrgStat" ENUM  "No","Yes","vector_leerstring";
BA_DEF_ BU_  "D3E_ReqType" ENUM  "Functional","Physical","Both";
BA_DEF_ BU_  "D3E_N12" ENUM  "No","Yes";
BA_DEF_ BU_  "D3E_FTstrPres" ENUM  "No","Yes","vector_leerstring";
BA_DEF_ BU_  "D3B_ReqType" ENUM  "Functional","Physical","Both";
BA_DEF_ BU_  "D3B_N78" ENUM  "No","Yes";
BA_DEF_ BU_  "D3B_N31" ENUM  "No","Yes";
BA_DEF_ BU_  "D3B_N22" ENUM  "No","Yes";
BA_DEF_ BU_  "D3B_N12" ENUM  "No","Yes";
BA_DEF_ BU_  "D3B_FWrtBlk" ENUM  "No","Yes","vector_leerstring";
BA_DEF_ BU_  "D36_ReqType" ENUM  "Functional","Physical","Both";
BA_DEF_ BU_  "D36_N89" ENUM  "No","Yes";
BA_DEF_ BU_  "D36_N85" ENUM  "No","Yes";
BA_DEF_ BU_  "D36_N83" ENUM  "No","Yes";
BA_DEF_ BU_  "D36_N78" ENUM  "No","Yes";
BA_DEF_ BU_  "D36_N31" ENUM  "No","Yes";
BA_DEF_ BU_  "D36_N22" ENUM  "No","Yes";
BA_DEF_ BU_  "D36_N12" ENUM  "No","Yes";
BA_DEF_ BU_  "D36_L80_DwnldExec" ENUM  "No","Yes";
BA_DEF_ BU_  "D36_L00_DownLoad" ENUM  "No","Yes";
BA_DEF_ BU_  "D36_FXfrData" ENUM  "No","Yes","vector_leerstring";
BA_DEF_ BU_  "D34_ReqType" ENUM  "Functional","Physical","Both";
BA_DEF_ BU_  "D34_N99" ENUM  "No","Yes";
BA_DEF_ BU_  "D34_N78" ENUM  "No","Yes";
BA_DEF_ BU_  "D34_N22" ENUM  "No","Yes";
BA_DEF_ BU_  "D34_N12" ENUM  "No","Yes";
BA_DEF_ BU_  "D34_FReqDwnld" ENUM  "No","Yes";
BA_DEF_ BU_  "D2C_ReqType" ENUM  "Functional","Physical","Both";
BA_DEF_ BU_  "D2C_N78" ENUM  "No","Yes";
BA_DEF_ BU_  "D2C_N31" ENUM  "No","Yes";
BA_DEF_ BU_  "D2C_N12" ENUM  "No","Yes";
BA_DEF_ BU_  "D2C_FDynMsg" ENUM  "No","Yes","vector_leerstring";
BA_DEF_ BU_  "D28_ReqType" ENUM  "Functional","Physical","Both";
BA_DEF_ BU_  "D28_N22" ENUM  "No","Yes";
BA_DEF_ BU_  "D28_N12" ENUM  "No","Yes";
BA_DEF_ BU_  "D28_FDisNormComm" ENUM  "No","Yes","vector_leerstring";
BA_DEF_ BU_  "D27_ReqType" ENUM  "Functional","Physical","Both";
BA_DEF_ BU_  "D27_N78" ENUM  "No","Yes";
BA_DEF_ BU_  "D27_N37" ENUM  "No","Yes";
BA_DEF_ BU_  "D27_N36" ENUM  "No","Yes";
BA_DEF_ BU_  "D27_N35" ENUM  "No","Yes";
BA_DEF_ BU_  "D27_N22" ENUM  "No","Yes";
BA_DEF_ BU_  "D27_N12" ENUM  "No","Yes";
BA_DEF_ BU_  "D27_L04_DevCtrlSeedKey" ENUM  "No","Yes";
BA_DEF_ BU_  "D27_L03_CtrlReqSeed" ENUM  "No","Yes";
BA_DEF_ BU_  "D27_L02_SndKey" ENUM  "No","Yes";
BA_DEF_ BU_  "D27_L01_ReqSeed" ENUM  "No","Yes";
BA_DEF_ BU_  "D27_FSecAcc" ENUM  "No","Yes","vector_leerstring";
BA_DEF_ BU_  "D23_ReqType" ENUM  "Functional","Physical","Both";
BA_DEF_ BU_  "D23_N78" ENUM  "No","Yes";
BA_DEF_ BU_  "D23_N31" ENUM  "No","Yes";
BA_DEF_ BU_  "D23_N12" ENUM  "No","Yes";
BA_DEF_ BU_  "D23_FRdMemAddr" ENUM  "No","Yes","vector_leerstring";
BA_DEF_ BU_  "D20_ReqType" ENUM  "Functional","Physical","Both";
BA_DEF_ BU_  "D20_N12" ENUM  "No","Yes";
BA_DEF_ BU_  "D20_FRtnNormComm" ENUM  "No","Yes","vector_leerstring";
BA_DEF_ BU_  "D1A_ReqType" ENUM  "Functional","Physical","Both";
BA_DEF_ BU_  "D1A_N78" ENUM  "No","Yes";
BA_DEF_ BU_  "D1A_N31" ENUM  "No","Yes";
BA_DEF_ BU_  "D1A_N22" ENUM  "No","Yes";
BA_DEF_ BU_  "D1A_N12" ENUM  "No","Yes";
BA_DEF_ BU_  "D1A_FRdDataID" ENUM  "No","Yes","vector_leerstring";
BA_DEF_ BU_  "D12_ReqType" ENUM  "Functional","Physical","Both";
BA_DEF_ BU_  "D12_N78" ENUM  "No","Yes";
BA_DEF_ BU_  "D12_N31" ENUM  "No","Yes";
BA_DEF_ BU_  "D12_N12" ENUM  "No","Yes";
BA_DEF_ BU_  "D12_L02_RdFRcdParam" ENUM  "No","Yes";
BA_DEF_ BU_  "D12_L01_RdFRcdData" ENUM  "No","Yes";
BA_DEF_ BU_  "D12_FRdFailRec" ENUM  "No","Yes","vector_leerstring";
BA_DEF_ BU_  "D10_ReqType" ENUM  "Functional","Physical ","Both";
BA_DEF_ BU_  "D10_N78" ENUM  "No","Yes","vector_leerstring";
BA_DEF_ BU_  "D10_N22" ENUM  "No","Yes","vector_leerstring";
BA_DEF_ BU_  "D10_N12" ENUM  "No","Yes","vector_leerstring";
BA_DEF_ BU_  "D10_L04_WakeUpLinks" ENUM  "No","Yes","vector_leerstring";
BA_DEF_ BU_  "D10_L03_DTCsDurDevCtrl" ENUM  "No","Yes","vector_leerstring";
BA_DEF_ BU_  "D10_L02_DisAllDTCs" ENUM  "No","Yes","vector_leerstring";
BA_DEF_ BU_  "D10_FInitDiagOp" ENUM  "No","Yes","vector_leerstring";
BA_DEF_ BU_  "D04_ReqType" ENUM  "Functional","Physical","Both","vector_leerstring";
BA_DEF_ BU_  "D04_N78" ENUM  "No","Yes","vector_leerstring";
BA_DEF_ BU_  "D04_N22" ENUM  "No","Yes","vector_leerstring";
BA_DEF_ BU_  "D04_N12" ENUM  "No","Yes","vector_leerstring";
BA_DEF_ BU_  "D04_FClrDTC" ENUM  "No","Yes","vector_leerstring";
BA_DEF_ BU_  "VNECUAllNodes" ENUM  "None","Activator","Remoted","Activator and Remoted","Shared Local";
BA_DEF_ BU_  "ECU_Id" HEX 0 255;
BA_DEF_ BU_  "SourceId" HEX 0 253;
BA_DEF_  "SyncJumpWidthMax" INT 0 255;
BA_DEF_  "SyncJumpWidthMin" INT 0 255;
BA_DEF_  "SamplePointMax" FLOAT 0 100;
BA_DEF_  "SamplePointMin" FLOAT 0 100;
BA_DEF_  "Baudrate" INT 0 1000000;
BA_DEF_  "VehicleArchitecture" STRING ;
BA_DEF_  "VNInitActSLHS_VNReq" ENUM  "No","Yes";
BA_DEF_  "VN_SLHS_VNReq" INT 0 255;
BA_DEF_  "VNInitActSLHSSharedDiagnostic" ENUM  "No","Yes";
BA_DEF_  "VN_SLHSSharedDiagnostic" INT 0 255;
BA_DEF_  "NmMessageCount" INT 0 32;
BA_DEF_  "NmBaseAddress" HEX 0 2032;
BA_DEF_  "NetworkType" STRING ;
BA_DEF_  "VNMFPeriodicInterval" INT 0 65535;
BA_DEF_  "BusWakeUpDelay" INT 0 65535;
BA_DEF_  "BusOffRecoveryTime" INT 0 65535;
BA_DEF_  "NodeStatusMsgID" HEX 0 536870911;
BA_DEF_  "NodeStatusMsgCycleTime" INT 0 65535;
BA_DEF_  "NodeStatusMsgTimeoutTime" INT 0 65535;
BA_DEF_  "UseGMParameterIDs" INT 0 1;
BA_DEF_  "VersionWeek" INT 0 255;
BA_DEF_  "VersionYear" INT 0 255;
BA_DEF_  "VN_AllNodes" INT 0 255;
BA_DEF_  "Manufacturer" ENUM  "DBAG","VAG","BMW","PAG","GM";
BA_DEF_  "NmType" STRING ;
BA_DEF_REL_ BU_SG_REL_  "GenSigSuprvRespComment" STRING ;
BA_DEF_REL_ BU_SG_REL_  "GenSigVBitResp" ENUM  "No","Yes";
BA_DEF_REL_ BU_SG_REL_  "GenSigVBitRespComment" STRING ;
BA_DEF_REL_ BU_SG_REL_  "GenSigVDAFailComment" STRING ;
BA_DEF_REL_ BU_SG_REL_  "GenSigVDAFailResp" ENUM  "No","Yes";
BA_DEF_REL_ BU_SG_REL_  "GenSigRxStartValue" STRING ;
BA_DEF_REL_ BU_SG_REL_  "GenSigSuprvRespSubValue" INT 0 65535;
BA_DEF_REL_ BU_SG_REL_  "GenSigSuprvResp" ENUM  "None","Notify App","Substitute Default";
BA_DEF_REL_ BU_SG_REL_  "GenSigTimeoutMsg" HEX -2147483648 268435455;
BA_DEF_REL_ BU_SG_REL_  "GenSigTimeoutTime" INT 0 15000;
BA_DEF_DEF_  "BusType" "";
BA_DEF_DEF_  "VNSigSLHS_VNReq" "No";
BA_DEF_DEF_  "VNSigSLHSSharedDiagnostic" "No";
BA_DEF_DEF_  "SignalType" "";
BA_DEF_DEF_  "PacketOrder" 0;
BA_DEF_DEF_  "SignalLongName" "";
BA_DEF_DEF_  "GenSigStartValue" 0;
BA_DEF_DEF_  "VNSigAllNodes" "No";
BA_DEF_DEF_  "GenSigDeltaValue" 0;
BA_DEF_DEF_  "GenSigSendType" "NoSigSendType";
BA_DEF_DEF_  "GenSigSendOnInit" "Not Initialized";
BA_DEF_DEF_  "AppGenMsgCycleTime" 0;
BA_DEF_DEF_  "GenMsgILSupport" "Yes";
BA_DEF_DEF_  "TpApplType" "";
BA_DEF_DEF_  "Prio" 4;
BA_DEF_DEF_  "MessageSubnet" "FO";
BA_DEF_DEF_  "DiagState" "No";
BA_DEF_DEF_  "GenMsgDelayTime" 0;
BA_DEF_DEF_  "GenMsgCycleTime" 0;
BA_DEF_DEF_  "GenMsgSendType" "spontanX";
BA_DEF_DEF_  "DiagResponse" "No";
BA_DEF_DEF_  "DiagRequest" "No";
BA_DEF_DEF_  "NmMessage" "No";
BA_DEF_DEF_REL_ "GenSigSuprvRespComment" "";
BA_DEF_DEF_REL_ "GenSigVBitResp" "No";
BA_DEF_DEF_REL_ "GenSigVBitRespComment" "";
BA_DEF_DEF_REL_ "GenSigVDAFailComment" "";
BA_DEF_DEF_REL_ "GenSigVDAFailResp" "No";
BA_DEF_DEF_REL_ "GenSigRxStartValue" "";
BA_DEF_DEF_REL_ "GenSigSuprvRespSubValue" 0;
BA_DEF_DEF_REL_ "GenSigSuprvResp" "None";
BA_DEF_DEF_REL_ "GenSigTimeoutMsg" 0;
BA_DEF_DEF_REL_ "GenSigTimeoutTime" 0;
BA_DEF_DEF_  "MessageManagerUsed" "Yes";
BA_DEF_DEF_  "NmNode" "Yes";
BA_DEF_DEF_  "ILUsed" "Yes";
BA_DEF_DEF_  "NodeLayerModules" "gmlan02.dll";
BA_DEF_DEF_  "VNECUSLHS_VNReq" "None";
BA_DEF_DEF_  "VNECUSLHSSharedDiagnostic" "None";
BA_DEF_DEF_  "D22_FRdDataByPID" "No";
BA_DEF_DEF_  "D22_N12" "No";
BA_DEF_DEF_  "D22_ReqType" "Both";
BA_DEF_DEF_  "D2D_ReqType" "Both";
BA_DEF_DEF_  "DAE_ReqType" "Both";
BA_DEF_DEF_  "DAE_NE3" "No";
BA_DEF_DEF_  "DAE_N78" "No";
BA_DEF_DEF_  "DAE_N31" "No";
BA_DEF_DEF_  "DAE_N12" "No";
BA_DEF_DEF_  "DAE_FDevCtrl" "No";
BA_DEF_DEF_  "DAA_ReqType" "Both";
BA_DEF_DEF_  "DAA_N81" "No";
BA_DEF_DEF_  "DAA_N78" "No";
BA_DEF_DEF_  "DAA_N31" "No";
BA_DEF_DEF_  "DAA_N12" "No";
BA_DEF_DEF_  "DAA_L04_FastRate" "No";
BA_DEF_DEF_  "DAA_L03_MedRate" "No";
BA_DEF_DEF_  "DAA_L02_SlowRate" "No";
BA_DEF_DEF_  "DAA_L01_SndOneRsp" "No";
BA_DEF_DEF_  "DAA_L00_StopSnd" "No";
BA_DEF_DEF_  "DAA_FRdDPID" "No";
BA_DEF_DEF_  "DA9_ReqType" "Both";
BA_DEF_DEF_  "DA9_N78" "No";
BA_DEF_DEF_  "DA9_N31" "No";
BA_DEF_DEF_  "DA9_N12" "No";
BA_DEF_DEF_  "DA9_L82_SndChgDTC" "No";
BA_DEF_DEF_  "DA9_L81_RdStatDTCbyMsk" "No";
BA_DEF_DEF_  "DA9_L80_RdStatDTCbyNum" "No";
BA_DEF_DEF_  "DA9_FRdDiagInfo" "Yes";
BA_DEF_DEF_  "DA5_ReqType" "Both";
BA_DEF_DEF_  "DA5_N78" "No";
BA_DEF_DEF_  "DA5_N22" "No";
BA_DEF_DEF_  "DA5_N12" "No";
BA_DEF_DEF_  "DA5_L03_EnabProgMode" "No";
BA_DEF_DEF_  "DA5_L01_ReqProgMode" "No";
BA_DEF_DEF_  "DA5_FProgMode" "Yes";
BA_DEF_DEF_  "DA2_ReqType" "Both";
BA_DEF_DEF_  "DA2_N78" "No";
BA_DEF_DEF_  "DA2_N12" "No";
BA_DEF_DEF_  "DA2_FRptPrgStat" "Yes";
BA_DEF_DEF_  "D3E_ReqType" "Both";
BA_DEF_DEF_  "D3E_N12" "No";
BA_DEF_DEF_  "D3E_FTstrPres" "Yes";
BA_DEF_DEF_  "D3B_ReqType" "Both";
BA_DEF_DEF_  "D3B_N78" "No";
BA_DEF_DEF_  "D3B_N31" "No";
BA_DEF_DEF_  "D3B_N22" "No";
BA_DEF_DEF_  "D3B_N12" "No";
BA_DEF_DEF_  "D3B_FWrtBlk" "No";
BA_DEF_DEF_  "D36_ReqType" "Both";
BA_DEF_DEF_  "D36_N89" "No";
BA_DEF_DEF_  "D36_N85" "No";
BA_DEF_DEF_  "D36_N83" "No";
BA_DEF_DEF_  "D36_N78" "No";
BA_DEF_DEF_  "D36_N31" "No";
BA_DEF_DEF_  "D36_N22" "No";
BA_DEF_DEF_  "D36_N12" "No";
BA_DEF_DEF_  "D36_L80_DwnldExec" "No";
BA_DEF_DEF_  "D36_L00_DownLoad" "No";
BA_DEF_DEF_  "D36_FXfrData" "Yes";
BA_DEF_DEF_  "D34_ReqType" "Both";
BA_DEF_DEF_  "D34_N99" "No";
BA_DEF_DEF_  "D34_N78" "No";
BA_DEF_DEF_  "D34_N22" "No";
BA_DEF_DEF_  "D34_N12" "No";
BA_DEF_DEF_  "D34_FReqDwnld" "Yes";
BA_DEF_DEF_  "D2C_ReqType" "Both";
BA_DEF_DEF_  "D2C_N78" "No";
BA_DEF_DEF_  "D2C_N31" "No";
BA_DEF_DEF_  "D2C_N12" "No";
BA_DEF_DEF_  "D2C_FDynMsg" "No";
BA_DEF_DEF_  "D28_ReqType" "Both";
BA_DEF_DEF_  "D28_N22" "No";
BA_DEF_DEF_  "D28_N12" "No";
BA_DEF_DEF_  "D28_FDisNormComm" "Yes";
BA_DEF_DEF_  "D27_ReqType" "Both";
BA_DEF_DEF_  "D27_N78" "No";
BA_DEF_DEF_  "D27_N37" "No";
BA_DEF_DEF_  "D27_N36" "No";
BA_DEF_DEF_  "D27_N35" "No";
BA_DEF_DEF_  "D27_N22" "No";
BA_DEF_DEF_  "D27_N12" "No";
BA_DEF_DEF_  "D27_L04_DevCtrlSeedKey" "No";
BA_DEF_DEF_  "D27_L03_CtrlReqSeed" "No";
BA_DEF_DEF_  "D27_L02_SndKey" "No";
BA_DEF_DEF_  "D27_L01_ReqSeed" "No";
BA_DEF_DEF_  "D27_FSecAcc" "No";
BA_DEF_DEF_  "D23_ReqType" "Both";
BA_DEF_DEF_  "D23_N78" "No";
BA_DEF_DEF_  "D23_N31" "No";
BA_DEF_DEF_  "D23_N12" "No";
BA_DEF_DEF_  "D23_FRdMemAddr" "No";
BA_DEF_DEF_  "D20_ReqType" "Both";
BA_DEF_DEF_  "D20_N12" "No";
BA_DEF_DEF_  "D20_FRtnNormComm" "Yes";
BA_DEF_DEF_  "D1A_ReqType" "Both";
BA_DEF_DEF_  "D1A_N78" "No";
BA_DEF_DEF_  "D1A_N31" "No";
BA_DEF_DEF_  "D1A_N22" "No";
BA_DEF_DEF_  "D1A_N12" "No";
BA_DEF_DEF_  "D1A_FRdDataID" "Yes";
BA_DEF_DEF_  "D12_ReqType" "Both";
BA_DEF_DEF_  "D12_N78" "No";
BA_DEF_DEF_  "D12_N31" "No";
BA_DEF_DEF_  "D12_N12" "No";
BA_DEF_DEF_  "D12_L02_RdFRcdParam" "No";
BA_DEF_DEF_  "D12_L01_RdFRcdData" "No";
BA_DEF_DEF_  "D12_FRdFailRec" "No";
BA_DEF_DEF_  "D10_ReqType" "Both";
BA_DEF_DEF_  "D10_N78" "No";
BA_DEF_DEF_  "D10_N22" "No";
BA_DEF_DEF_  "D10_N12" "No";
BA_DEF_DEF_  "D10_L04_WakeUpLinks" "No";
BA_DEF_DEF_  "D10_L03_DTCsDurDevCtrl" "No";
BA_DEF_DEF_  "D10_L02_DisAllDTCs" "No";
BA_DEF_DEF_  "D10_FInitDiagOp" "Yes";
BA_DEF_DEF_  "D04_ReqType" "Both";
BA_DEF_DEF_  "D04_N78" "No";
BA_DEF_DEF_  "D04_N22" "No";
BA_DEF_DEF_  "D04_N12" "No";
BA_DEF_DEF_  "D04_FClrDTC" "Yes";
BA_DEF_DEF_  "VNECUAllNodes" "None";
BA_DEF_DEF_  "ECU_Id" 0;
BA_DEF_DEF_  "SourceId" 0;
BA_DEF_DEF_  "SyncJumpWidthMax" 0;
BA_DEF_DEF_  "SyncJumpWidthMin" 0;
BA_DEF_DEF_  "SamplePointMax" 0;
BA_DEF_DEF_  "SamplePointMin" 0;
BA_DEF_DEF_  "Baudrate" 0;
BA_DEF_DEF_  "VehicleArchitecture" "";
BA_DEF_DEF_  "VNInitActSLHS_VNReq" "No";
BA_DEF_DEF_  "VN_SLHS_VNReq" 2;
BA_DEF_DEF_  "VNInitActSLHSSharedDiagnostic" "No";
BA_DEF_DEF_  "VN_SLHSSharedDiagnostic" 0;
BA_DEF_DEF_  "NmMessageCount" 32;
BA_DEF_DEF_  "NmBaseAddress" 1568;
BA_DEF_DEF_  "NetworkType" "";
BA_DEF_DEF_  "VNMFPeriodicInterval" 3000;
BA_DEF_DEF_  "BusWakeUpDelay" 100;
BA_DEF_DEF_  "BusOffRecoveryTime" 0;
BA_DEF_DEF_  "NodeStatusMsgID" 268427264;
BA_DEF_DEF_  "NodeStatusMsgCycleTime" 1200;
BA_DEF_DEF_  "NodeStatusMsgTimeoutTime" 0;
BA_DEF_DEF_  "UseGMParameterIDs" 1;
BA_DEF_DEF_  "VersionWeek" 0;
BA_DEF_DEF_  "VersionYear" 0;
BA_DEF_DEF_  "VN_AllNodes" 1;
BA_DEF_DEF_  "Manufacturer" "GM";
BA_DEF_DEF_  "NmType" "GMLAN";
BA_ "SyncJumpWidthMax" 4;
BA_ "SyncJumpWidthMin" 3;
BA_ "SamplePointMax" 81.25;
BA_ "SamplePointMin" 80;
BA_ "Baudrate" 500000;
BA_ "VehicleArchitecture" "Global A";
BA_ "VNInitActSLHS_VNReq" 1;
BA_ "VNInitActSLHSSharedDiagnostic" 1;
BA_ "NmMessageCount" 16;
BA_ "NmBaseAddress" 1536;
BA_ "NetworkType" "Powertrain";
BA_ "BusWakeUpDelay" 70;
BA_ "BusOffRecoveryTime" 160;
BA_ "NodeStatusMsgID" 0;
BA_ "UseGMParameterIDs" 0;
BA_ "VersionWeek" 49;
BA_ "VersionYear" 6;
BA_ "BusType" "CAN";
BA_ "VNECUSLHS_VNReq" BU_ PFAF_HS 4;
BA_ "VNECUSLHSSharedDiagnostic" BU_ PFAF_HS 4;
BA_ "VNECUAllNodes" BU_ PFAF_HS 4;
BA_ "ECU_Id" BU_ PFAF_HS 12;
BA_ "SourceId" BU_ PFAF_HS 87;
BA_ "VNECUSLHS_VNReq" BU_ LVMPC_HS 4;
BA_ "VNECUSLHSSharedDiagnostic" BU_ LVMPC_HS 4;
BA_ "VNECUAllNodes" BU_ LVMPC_HS 4;
BA_ "VNECUSLHS_VNReq" BU_ DCDC_HS 4;
BA_ "VNECUSLHSSharedDiagnostic" BU_ DCDC_HS 4;
BA_ "VNECUAllNodes" BU_ DCDC_HS 4;
BA_ "ECU_Id" BU_ DCDC_HS 4;
BA_ "SourceId" BU_ DCDC_HS 204;
BA_ "VNECUSLHS_VNReq" BU_ AMP_HS 4;
BA_ "VNECUSLHSSharedDiagnostic" BU_ AMP_HS 4;
BA_ "VNECUAllNodes" BU_ AMP_HS 4;
BA_ "ECU_Id" BU_ AMP_HS 19;
BA_ "SourceId" BU_ AMP_HS 129;
BA_ "VNECUSLHS_VNReq" BU_ VICM2_HS 4;
BA_ "VNECUSLHSSharedDiagnostic" BU_ VICM2_HS 4;
BA_ "VNECUAllNodes" BU_ VICM2_HS 4;
BA_ "ECU_Id" BU_ VICM2_HS 230;
BA_ "SourceId" BU_ VICM2_HS 206;
BA_ "VNECUSLHS_VNReq" BU_ FICM_HS 4;
BA_ "VNECUSLHSSharedDiagnostic" BU_ FICM_HS 4;
BA_ "VNECUAllNodes" BU_ FICM_HS 4;
BA_ "ECU_Id" BU_ FICM_HS 230;
BA_ "SourceId" BU_ FICM_HS 19;
BA_ "VNECUSLHS_VNReq" BU_ ARS_HS 4;
BA_ "VNECUSLHSSharedDiagnostic" BU_ ARS_HS 4;
BA_ "VNECUAllNodes" BU_ ARS_HS 4;
BA_ "ECU_Id" BU_ ARS_HS 29;
BA_ "SourceId" BU_ ARS_HS 50;
BA_ "VNECUSLHS_VNReq" BU_ MCP_B_HS 4;
BA_ "VNECUSLHSSharedDiagnostic" BU_ MCP_B_HS 4;
BA_ "VNECUAllNodes" BU_ MCP_B_HS 4;
BA_ "ECU_Id" BU_ MCP_B_HS 24;
BA_ "SourceId" BU_ MCP_B_HS 30;
BA_ "VNECUSLHS_VNReq" BU_ MCP_A_HS 4;
BA_ "VNECUSLHSSharedDiagnostic" BU_ MCP_A_HS 4;
BA_ "VNECUAllNodes" BU_ MCP_A_HS 4;
BA_ "ECU_Id" BU_ MCP_A_HS 23;
BA_ "SourceId" BU_ MCP_A_HS 206;
BA_ "VNECUSLHS_VNReq" BU_ ICCM_OBD_HS 4;
BA_ "VNECUSLHSSharedDiagnostic" BU_ ICCM_OBD_HS 4;
BA_ "VNECUAllNodes" BU_ ICCM_OBD_HS 4;
BA_ "ECU_Id" BU_ ICCM_OBD_HS 227;
BA_ "SourceId" BU_ ICCM_OBD_HS 19;
BA_ "VNECUSLHS_VNReq" BU_ SAS_HS 4;
BA_ "VNECUSLHSSharedDiagnostic" BU_ SAS_HS 4;
BA_ "VNECUAllNodes" BU_ SAS_HS 4;
BA_ "ECU_Id" BU_ SAS_HS 23;
BA_ "SourceId" BU_ SAS_HS 52;
BA_ "VNECUSLHS_VNReq" BU_ ACCM_HS 4;
BA_ "VNECUSLHSSharedDiagnostic" BU_ ACCM_HS 4;
BA_ "VNECUAllNodes" BU_ ACCM_HS 4;
BA_ "ECU_Id" BU_ ACCM_HS 53;
BA_ "SourceId" BU_ ACCM_HS 156;
BA_ "VNECUSLHS_VNReq" BU_ VLBS_HS 4;
BA_ "VNECUSLHSSharedDiagnostic" BU_ VLBS_HS 4;
BA_ "VNECUAllNodes" BU_ VLBS_HS 4;
BA_ "ECU_Id" BU_ VLBS_HS 31;
BA_ "SourceId" BU_ VLBS_HS 144;
BA_ "VNECUSLHS_VNReq" BU_ EBCM_OBD_HS 4;
BA_ "VNECUSLHSSharedDiagnostic" BU_ EBCM_OBD_HS 4;
BA_ "D22_FRdDataByPID" BU_ EBCM_OBD_HS 1;
BA_ "D22_N12" BU_ EBCM_OBD_HS 1;
BA_ "DAE_NE3" BU_ EBCM_OBD_HS 1;
BA_ "DAE_N78" BU_ EBCM_OBD_HS 1;
BA_ "DAE_N31" BU_ EBCM_OBD_HS 1;
BA_ "DAE_N12" BU_ EBCM_OBD_HS 1;
BA_ "DAE_FDevCtrl" BU_ EBCM_OBD_HS 1;
BA_ "DAA_N81" BU_ EBCM_OBD_HS 1;
BA_ "DAA_N78" BU_ EBCM_OBD_HS 1;
BA_ "DAA_N31" BU_ EBCM_OBD_HS 1;
BA_ "DAA_N12" BU_ EBCM_OBD_HS 1;
BA_ "DAA_L04_FastRate" BU_ EBCM_OBD_HS 1;
BA_ "DAA_L03_MedRate" BU_ EBCM_OBD_HS 1;
BA_ "DAA_L02_SlowRate" BU_ EBCM_OBD_HS 1;
BA_ "DAA_L01_SndOneRsp" BU_ EBCM_OBD_HS 1;
BA_ "DAA_L00_StopSnd" BU_ EBCM_OBD_HS 1;
BA_ "DAA_FRdDPID" BU_ EBCM_OBD_HS 1;
BA_ "DA9_N78" BU_ EBCM_OBD_HS 1;
BA_ "DA9_N31" BU_ EBCM_OBD_HS 1;
BA_ "DA9_N12" BU_ EBCM_OBD_HS 1;
BA_ "DA9_L82_SndChgDTC" BU_ EBCM_OBD_HS 1;
BA_ "DA9_L80_RdStatDTCbyNum" BU_ EBCM_OBD_HS 1;
BA_ "DA5_N22" BU_ EBCM_OBD_HS 1;
BA_ "DA5_N12" BU_ EBCM_OBD_HS 1;
BA_ "DA5_L03_EnabProgMode" BU_ EBCM_OBD_HS 1;
BA_ "DA5_L01_ReqProgMode" BU_ EBCM_OBD_HS 1;
BA_ "DA2_N12" BU_ EBCM_OBD_HS 1;
BA_ "D3E_N12" BU_ EBCM_OBD_HS 1;
BA_ "D3B_N78" BU_ EBCM_OBD_HS 1;
BA_ "D3B_N31" BU_ EBCM_OBD_HS 1;
BA_ "D3B_N22" BU_ EBCM_OBD_HS 1;
BA_ "D3B_N12" BU_ EBCM_OBD_HS 1;
BA_ "D3B_FWrtBlk" BU_ EBCM_OBD_HS 1;
BA_ "D36_N85" BU_ EBCM_OBD_HS 1;
BA_ "D36_N83" BU_ EBCM_OBD_HS 1;
BA_ "D36_N78" BU_ EBCM_OBD_HS 1;
BA_ "D36_N31" BU_ EBCM_OBD_HS 1;
BA_ "D36_N22" BU_ EBCM_OBD_HS 1;
BA_ "D36_N12" BU_ EBCM_OBD_HS 1;
BA_ "D36_L80_DwnldExec" BU_ EBCM_OBD_HS 1;
BA_ "D36_L00_DownLoad" BU_ EBCM_OBD_HS 1;
BA_ "D34_N99" BU_ EBCM_OBD_HS 1;
BA_ "D34_N78" BU_ EBCM_OBD_HS 1;
BA_ "D34_N22" BU_ EBCM_OBD_HS 1;
BA_ "D34_N12" BU_ EBCM_OBD_HS 1;
BA_ "D2C_N78" BU_ EBCM_OBD_HS 1;
BA_ "D2C_N31" BU_ EBCM_OBD_HS 1;
BA_ "D2C_N12" BU_ EBCM_OBD_HS 1;
BA_ "D2C_FDynMsg" BU_ EBCM_OBD_HS 1;
BA_ "D28_N22" BU_ EBCM_OBD_HS 1;
BA_ "D28_N12" BU_ EBCM_OBD_HS 1;
BA_ "D27_N78" BU_ EBCM_OBD_HS 1;
BA_ "D27_N37" BU_ EBCM_OBD_HS 1;
BA_ "D27_N36" BU_ EBCM_OBD_HS 1;
BA_ "D27_N35" BU_ EBCM_OBD_HS 1;
BA_ "D27_N22" BU_ EBCM_OBD_HS 1;
BA_ "D27_N12" BU_ EBCM_OBD_HS 1;
BA_ "D27_L04_DevCtrlSeedKey" BU_ EBCM_OBD_HS 1;
BA_ "D27_L03_CtrlReqSeed" BU_ EBCM_OBD_HS 1;
BA_ "D27_L02_SndKey" BU_ EBCM_OBD_HS 1;
BA_ "D27_L01_ReqSeed" BU_ EBCM_OBD_HS 1;
BA_ "D27_FSecAcc" BU_ EBCM_OBD_HS 1;
BA_ "D23_N31" BU_ EBCM_OBD_HS 1;
BA_ "D23_N12" BU_ EBCM_OBD_HS 1;
BA_ "D23_FRdMemAddr" BU_ EBCM_OBD_HS 1;
BA_ "D20_N12" BU_ EBCM_OBD_HS 1;
BA_ "D1A_N78" BU_ EBCM_OBD_HS 1;
BA_ "D1A_N31" BU_ EBCM_OBD_HS 1;
BA_ "D1A_N22" BU_ EBCM_OBD_HS 1;
BA_ "D1A_N12" BU_ EBCM_OBD_HS 1;
BA_ "D12_N78" BU_ EBCM_OBD_HS 1;
BA_ "D12_N31" BU_ EBCM_OBD_HS 1;
BA_ "D12_N12" BU_ EBCM_OBD_HS 1;
BA_ "D12_L02_RdFRcdParam" BU_ EBCM_OBD_HS 1;
BA_ "D12_L01_RdFRcdData" BU_ EBCM_OBD_HS 1;
BA_ "D12_FRdFailRec" BU_ EBCM_OBD_HS 1;
BA_ "D10_N22" BU_ EBCM_OBD_HS 1;
BA_ "D10_N12" BU_ EBCM_OBD_HS 1;
BA_ "D10_L03_DTCsDurDevCtrl" BU_ EBCM_OBD_HS 1;
BA_ "D10_L02_DisAllDTCs" BU_ EBCM_OBD_HS 1;
BA_ "D04_N22" BU_ EBCM_OBD_HS 1;
BA_ "D04_N12" BU_ EBCM_OBD_HS 1;
BA_ "VNECUAllNodes" BU_ EBCM_OBD_HS 4;
BA_ "ECU_Id" BU_ EBCM_OBD_HS 3;
BA_ "SourceId" BU_ EBCM_OBD_HS 40;
BA_ "VNECUSLHS_VNReq" BU_ EDI_HS 4;
BA_ "VNECUSLHSSharedDiagnostic" BU_ EDI_HS 4;
BA_ "VNECUAllNodes" BU_ EDI_HS 4;
BA_ "VNECUSLHS_VNReq" BU_ HPCC_HS 4;
BA_ "VNECUSLHSSharedDiagnostic" BU_ HPCC_HS 4;
BA_ "VNECUAllNodes" BU_ HPCC_HS 4;
BA_ "ECU_Id" BU_ HPCC_HS 3;
BA_ "SourceId" BU_ HPCC_HS 200;
BA_ "VNECUSLHS_VNReq" BU_ VITM_OBD_HS 4;
BA_ "VNECUSLHSSharedDiagnostic" BU_ VITM_OBD_HS 4;
BA_ "VNECUAllNodes" BU_ VITM_OBD_HS 4;
BA_ "ECU_Id" BU_ VITM_OBD_HS 231;
BA_ "SourceId" BU_ VITM_OBD_HS 205;
BA_ "VNECUSLHS_VNReq" BU_ PTAM_HS 4;
BA_ "VNECUSLHSSharedDiagnostic" BU_ PTAM_HS 4;
BA_ "VNECUAllNodes" BU_ PTAM_HS 4;
BA_ "ECU_Id" BU_ PTAM_HS 16;
BA_ "SourceId" BU_ PTAM_HS 32;
BA_ "VNECUSLHS_VNReq" BU_ OBCM_HS 4;
BA_ "VNECUSLHSSharedDiagnostic" BU_ OBCM_HS 4;
BA_ "VNECUAllNodes" BU_ OBCM_HS 4;
BA_ "ECU_Id" BU_ OBCM_HS 68;
BA_ "SourceId" BU_ OBCM_HS 202;
BA_ "VNECUSLHS_VNReq" BU_ VICM_HS 4;
BA_ "VNECUSLHSSharedDiagnostic" BU_ VICM_HS 4;
BA_ "VNECUAllNodes" BU_ VICM_HS 4;
BA_ "ECU_Id" BU_ VICM_HS 228;
BA_ "SourceId" BU_ VICM_HS 203;
BA_ "VNECUAllNodes" BU_ HCP_HS 4;
BA_ "ECU_Id" BU_ HCP_HS 225;
BA_ "SourceId" BU_ HCP_HS 23;
BA_ "VNECUSLHS_VNReq" BU_ FDCM_HS 4;
BA_ "VNECUSLHSSharedDiagnostic" BU_ FDCM_HS 4;
BA_ "VNECUAllNodes" BU_ FDCM_HS 4;
BA_ "ECU_Id" BU_ FDCM_HS 17;
BA_ "SourceId" BU_ FDCM_HS 54;
BA_ "VNECUSLHS_VNReq" BU_ APPS_HS 4;
BA_ "VNECUSLHSSharedDiagnostic" BU_ APPS_HS 4;
BA_ "VNECUAllNodes" BU_ APPS_HS 4;
BA_ "ECU_Id" BU_ APPS_HS 6;
BA_ "SourceId" BU_ APPS_HS 93;
BA_ "VNECUSLHS_VNReq" BU_ ICCM_HS 4;
BA_ "VNECUSLHSSharedDiagnostic" BU_ ICCM_HS 4;
BA_ "VNECUAllNodes" BU_ ICCM_HS 4;
BA_ "ECU_Id" BU_ ICCM_HS 227;
BA_ "SourceId" BU_ ICCM_HS 34;
BA_ "VNECUSLHS_VNReq" BU_ EOCM_F_HS 4;
BA_ "VNECUSLHSSharedDiagnostic" BU_ EOCM_F_HS 4;
BA_ "VNECUAllNodes" BU_ EOCM_F_HS 4;
BA_ "ECU_Id" BU_ EOCM_F_HS 75;
BA_ "SourceId" BU_ EOCM_F_HS 108;
BA_ "VNECUSLHS_VNReq" BU_ GPCM_HS 4;
BA_ "VNECUSLHSSharedDiagnostic" BU_ GPCM_HS 4;
BA_ "VNECUAllNodes" BU_ GPCM_HS 4;
BA_ "ECU_Id" BU_ GPCM_HS 230;
BA_ "SourceId" BU_ GPCM_HS 22;
BA_ "VNECUSLHS_VNReq" BU_ FSCM_ITBC_HS 4;
BA_ "VNECUSLHSSharedDiagnostic" BU_ FSCM_ITBC_HS 4;
BA_ "VNECUAllNodes" BU_ FSCM_ITBC_HS 4;
BA_ "ECU_Id" BU_ FSCM_ITBC_HS 227;
BA_ "SourceId" BU_ FSCM_ITBC_HS 19;
BA_ "VNECUSLHS_VNReq" BU_ SCM_HS 4;
BA_ "VNECUSLHSSharedDiagnostic" BU_ SCM_HS 4;
BA_ "VNECUAllNodes" BU_ SCM_HS 4;
BA_ "ECU_Id" BU_ SCM_HS 16;
BA_ "SourceId" BU_ SCM_HS 32;
BA_ "VNECUSLHS_VNReq" BU_ ITBC_HS 4;
BA_ "VNECUSLHSSharedDiagnostic" BU_ ITBC_HS 4;
BA_ "VNECUAllNodes" BU_ ITBC_HS 4;
BA_ "ECU_Id" BU_ ITBC_HS 4;
BA_ "SourceId" BU_ ITBC_HS 45;
BA_ "VNECUSLHS_VNReq" BU_ VCM_HS 4;
BA_ "VNECUSLHSSharedDiagnostic" BU_ VCM_HS 4;
BA_ "VNECUAllNodes" BU_ VCM_HS 4;
BA_ "ECU_Id" BU_ VCM_HS 30;
BA_ "SourceId" BU_ VCM_HS 20;
BA_ "VNECUSLHS_VNReq" BU_ HMIM_HS 4;
BA_ "VNECUSLHSSharedDiagnostic" BU_ HMIM_HS 4;
BA_ "VNECUAllNodes" BU_ HMIM_HS 4;
BA_ "ECU_Id" BU_ HMIM_HS 18;
BA_ "SourceId" BU_ HMIM_HS 143;
BA_ "VNECUSLHS_VNReq" BU_ FCP_HS 4;
BA_ "VNECUSLHSSharedDiagnostic" BU_ FCP_HS 4;
BA_ "VNECUAllNodes" BU_ FCP_HS 4;
BA_ "ECU_Id" BU_ FCP_HS 13;
BA_ "SourceId" BU_ FCP_HS 151;
BA_ "VNECUSLHS_VNReq" BU_ VES_HS 4;
BA_ "VNECUSLHSSharedDiagnostic" BU_ VES_HS 4;
BA_ "VNECUAllNodes" BU_ VES_HS 4;
BA_ "ECU_Id" BU_ VES_HS 2;
BA_ "SourceId" BU_ VES_HS 49;
BA_ "VNECUSLHSSharedDiagnostic" BU_ Dummy_HS 4;
BA_ "VNECUAllNodes" BU_ Dummy_HS 4;
BA_ "VNECUSLHS_VNReq" BU_ MCP_C_HS 4;
BA_ "VNECUSLHSSharedDiagnostic" BU_ MCP_C_HS 4;
BA_ "VNECUAllNodes" BU_ MCP_C_HS 4;
BA_ "ECU_Id" BU_ MCP_C_HS 25;
BA_ "SourceId" BU_ MCP_C_HS 31;
BA_ "VNECUSLHS_VNReq" BU_ RWS_HS 4;
BA_ "VNECUSLHSSharedDiagnostic" BU_ RWS_HS 4;
BA_ "VNECUAllNodes" BU_ RWS_HS 4;
BA_ "ECU_Id" BU_ RWS_HS 6;
BA_ "SourceId" BU_ RWS_HS 50;
BA_ "VNECUSLHS_VNReq" BU_ ONSTAR_HS 4;
BA_ "VNECUSLHSSharedDiagnostic" BU_ ONSTAR_HS 4;
BA_ "VNECUAllNodes" BU_ ONSTAR_HS 4;
BA_ "ECU_Id" BU_ ONSTAR_HS 13;
BA_ "SourceId" BU_ ONSTAR_HS 151;
BA_ "VNECUSLHS_VNReq" BU_ EPS_HS 4;
BA_ "VNECUSLHSSharedDiagnostic" BU_ EPS_HS 4;
BA_ "VNECUAllNodes" BU_ EPS_HS 4;
BA_ "ECU_Id" BU_ EPS_HS 2;
BA_ "SourceId" BU_ EPS_HS 49;
BA_ "VNECUSLHS_VNReq" BU_ TestTool_HS 4;
BA_ "VNECUSLHSSharedDiagnostic" BU_ TestTool_HS 4;
BA_ "VNECUAllNodes" BU_ TestTool_HS 4;
BA_ "SourceId" BU_ TestTool_HS 253;
BA_ "VNECUSLHS_VNReq" BU_ MCP_HS 4;
BA_ "VNECUSLHSSharedDiagnostic" BU_ MCP_HS 4;
BA_ "VNECUAllNodes" BU_ MCP_HS 4;
BA_ "ECU_Id" BU_ MCP_HS 23;
BA_ "SourceId" BU_ MCP_HS 206;
BA_ "VNECUSLHS_VNReq" BU_ BCP_HS 4;
BA_ "VNECUSLHSSharedDiagnostic" BU_ BCP_HS 4;
BA_ "VNECUAllNodes" BU_ BCP_HS 4;
BA_ "ECU_Id" BU_ BCP_HS 225;
BA_ "SourceId" BU_ BCP_HS 23;
BA_ "VNECUSLHS_VNReq" BU_ ALC_HS 4;
BA_ "VNECUSLHSSharedDiagnostic" BU_ ALC_HS 4;
BA_ "VNECUAllNodes" BU_ ALC_HS 4;
BA_ "ECU_Id" BU_ ALC_HS 14;
BA_ "SourceId" BU_ ALC_HS 58;
BA_ "VNECUSLHS_VNReq" BU_ AHL_AFL_HS 4;
BA_ "VNECUSLHSSharedDiagnostic" BU_ AHL_AFL_HS 4;
BA_ "VNECUAllNodes" BU_ AHL_AFL_HS 4;
BA_ "ECU_Id" BU_ AHL_AFL_HS 9;
BA_ "SourceId" BU_ AHL_AFL_HS 114;
BA_ "VNECUSLHS_VNReq" BU_ SADS_HS 4;
BA_ "VNECUSLHSSharedDiagnostic" BU_ SADS_HS 4;
BA_ "VNECUAllNodes" BU_ SADS_HS 4;
BA_ "ECU_Id" BU_ SADS_HS 14;
BA_ "SourceId" BU_ SADS_HS 56;
BA_ "VNECUSLHS_VNReq" BU_ EPB_HS 4;
BA_ "VNECUSLHSSharedDiagnostic" BU_ EPB_HS 4;
BA_ "VNECUAllNodes" BU_ EPB_HS 4;
BA_ "ECU_Id" BU_ EPB_HS 20;
BA_ "SourceId" BU_ EPB_HS 43;
BA_ "VNECUSLHS_VNReq" BU_ FSCM_HS 4;
BA_ "VNECUSLHSSharedDiagnostic" BU_ FSCM_HS 4;
BA_ "VNECUAllNodes" BU_ FSCM_HS 4;
BA_ "ECU_Id" BU_ FSCM_HS 227;
BA_ "SourceId" BU_ FSCM_HS 19;
BA_ "VNECUSLHS_VNReq" BU_ AFS_HS 4;
BA_ "VNECUSLHSSharedDiagnostic" BU_ AFS_HS 4;
BA_ "VNECUAllNodes" BU_ AFS_HS 4;
BA_ "ECU_Id" BU_ AFS_HS 21;
BA_ "SourceId" BU_ AFS_HS 51;
BA_ "VNECUSLHS_VNReq" BU_ FCM_HS 4;
BA_ "VNECUSLHSSharedDiagnostic" BU_ FCM_HS 4;
BA_ "VNECUAllNodes" BU_ FCM_HS 4;
BA_ "ECU_Id" BU_ FCM_HS 11;
BA_ "SourceId" BU_ FCM_HS 188;
BA_ "VNECUSLHS_VNReq" BU_ TCCM_HS 4;
BA_ "VNECUSLHSSharedDiagnostic" BU_ TCCM_HS 4;
BA_ "VNECUAllNodes" BU_ TCCM_HS 4;
BA_ "ECU_Id" BU_ TCCM_HS 22;
BA_ "SourceId" BU_ TCCM_HS 26;
BA_ "VNECUSLHS_VNReq" BU_ RDCM_HS 4;
BA_ "VNECUSLHSSharedDiagnostic" BU_ RDCM_HS 4;
BA_ "VNECUAllNodes" BU_ RDCM_HS 4;
BA_ "ECU_Id" BU_ RDCM_HS 15;
BA_ "SourceId" BU_ RDCM_HS 27;
BA_ "VNECUSLHS_VNReq" BU_ PTO_HS 4;
BA_ "VNECUSLHSSharedDiagnostic" BU_ PTO_HS 4;
BA_ "VNECUAllNodes" BU_ PTO_HS 4;
BA_ "ECU_Id" BU_ PTO_HS 7;
BA_ "SourceId" BU_ PTO_HS 25;
BA_ "VNECUSLHS_VNReq" BU_ PCM_HS 4;
BA_ "VNECUSLHSSharedDiagnostic" BU_ PCM_HS 4;
BA_ "VNECUAllNodes" BU_ PCM_HS 4;
BA_ "ECU_Id" BU_ PCM_HS 225;
BA_ "SourceId" BU_ PCM_HS 17;
BA_ "VNECUSLHS_VNReq" BU_ EBCM_HS 4;
BA_ "VNECUSLHSSharedDiagnostic" BU_ EBCM_HS 4;
BA_ "D22_FRdDataByPID" BU_ EBCM_HS 1;
BA_ "D22_N12" BU_ EBCM_HS 1;
BA_ "DAE_NE3" BU_ EBCM_HS 1;
BA_ "DAE_N78" BU_ EBCM_HS 1;
BA_ "DAE_N31" BU_ EBCM_HS 1;
BA_ "DAE_N12" BU_ EBCM_HS 1;
BA_ "DAE_FDevCtrl" BU_ EBCM_HS 1;
BA_ "DAA_N81" BU_ EBCM_HS 1;
BA_ "DAA_N78" BU_ EBCM_HS 1;
BA_ "DAA_N31" BU_ EBCM_HS 1;
BA_ "DAA_N12" BU_ EBCM_HS 1;
BA_ "DAA_L04_FastRate" BU_ EBCM_HS 1;
BA_ "DAA_L03_MedRate" BU_ EBCM_HS 1;
BA_ "DAA_L02_SlowRate" BU_ EBCM_HS 1;
BA_ "DAA_L01_SndOneRsp" BU_ EBCM_HS 1;
BA_ "DAA_L00_StopSnd" BU_ EBCM_HS 1;
BA_ "DAA_FRdDPID" BU_ EBCM_HS 1;
BA_ "DA9_N78" BU_ EBCM_HS 1;
BA_ "DA9_N31" BU_ EBCM_HS 1;
BA_ "DA9_N12" BU_ EBCM_HS 1;
BA_ "DA9_L82_SndChgDTC" BU_ EBCM_HS 1;
BA_ "DA9_L80_RdStatDTCbyNum" BU_ EBCM_HS 1;
BA_ "DA5_N22" BU_ EBCM_HS 1;
BA_ "DA5_N12" BU_ EBCM_HS 1;
BA_ "DA5_L03_EnabProgMode" BU_ EBCM_HS 1;
BA_ "DA5_L01_ReqProgMode" BU_ EBCM_HS 1;
BA_ "DA2_N12" BU_ EBCM_HS 1;
BA_ "D3E_N12" BU_ EBCM_HS 1;
BA_ "D3B_N78" BU_ EBCM_HS 1;
BA_ "D3B_N31" BU_ EBCM_HS 1;
BA_ "D3B_N22" BU_ EBCM_HS 1;
BA_ "D3B_N12" BU_ EBCM_HS 1;
BA_ "D3B_FWrtBlk" BU_ EBCM_HS 1;
BA_ "D36_N85" BU_ EBCM_HS 1;
BA_ "D36_N83" BU_ EBCM_HS 1;
BA_ "D36_N78" BU_ EBCM_HS 1;
BA_ "D36_N31" BU_ EBCM_HS 1;
BA_ "D36_N22" BU_ EBCM_HS 1;
BA_ "D36_N12" BU_ EBCM_HS 1;
BA_ "D36_L80_DwnldExec" BU_ EBCM_HS 1;
BA_ "D36_L00_DownLoad" BU_ EBCM_HS 1;
BA_ "D34_N99" BU_ EBCM_HS 1;
BA_ "D34_N78" BU_ EBCM_HS 1;
BA_ "D34_N22" BU_ EBCM_HS 1;
BA_ "D34_N12" BU_ EBCM_HS 1;
BA_ "D2C_N78" BU_ EBCM_HS 1;
BA_ "D2C_N31" BU_ EBCM_HS 1;
BA_ "D2C_N12" BU_ EBCM_HS 1;
BA_ "D2C_FDynMsg" BU_ EBCM_HS 1;
BA_ "D28_N22" BU_ EBCM_HS 1;
BA_ "D28_N12" BU_ EBCM_HS 1;
BA_ "D27_N78" BU_ EBCM_HS 1;
BA_ "D27_N37" BU_ EBCM_HS 1;
BA_ "D27_N36" BU_ EBCM_HS 1;
BA_ "D27_N35" BU_ EBCM_HS 1;
BA_ "D27_N22" BU_ EBCM_HS 1;
BA_ "D27_N12" BU_ EBCM_HS 1;
BA_ "D27_L04_DevCtrlSeedKey" BU_ EBCM_HS 1;
BA_ "D27_L03_CtrlReqSeed" BU_ EBCM_HS 1;
BA_ "D27_L02_SndKey" BU_ EBCM_HS 1;
BA_ "D27_L01_ReqSeed" BU_ EBCM_HS 1;
BA_ "D27_FSecAcc" BU_ EBCM_HS 1;
BA_ "D23_N31" BU_ EBCM_HS 1;
BA_ "D23_N12" BU_ EBCM_HS 1;
BA_ "D23_FRdMemAddr" BU_ EBCM_HS 1;
BA_ "D20_N12" BU_ EBCM_HS 1;
BA_ "D1A_N78" BU_ EBCM_HS 1;
BA_ "D1A_N31" BU_ EBCM_HS 1;
BA_ "D1A_N22" BU_ EBCM_HS 1;
BA_ "D1A_N12" BU_ EBCM_HS 1;
BA_ "D12_N78" BU_ EBCM_HS 1;
BA_ "D12_N31" BU_ EBCM_HS 1;
BA_ "D12_N12" BU_ EBCM_HS 1;
BA_ "D12_L02_RdFRcdParam" BU_ EBCM_HS 1;
BA_ "D12_L01_RdFRcdData" BU_ EBCM_HS 1;
BA_ "D12_FRdFailRec" BU_ EBCM_HS 1;
BA_ "D10_N22" BU_ EBCM_HS 1;
BA_ "D10_N12" BU_ EBCM_HS 1;
BA_ "D10_L03_DTCsDurDevCtrl" BU_ EBCM_HS 1;
BA_ "D10_L02_DisAllDTCs" BU_ EBCM_HS 1;
BA_ "D04_N22" BU_ EBCM_HS 1;
BA_ "D04_N12" BU_ EBCM_HS 1;
BA_ "VNECUAllNodes" BU_ EBCM_HS 4;
BA_ "ECU_Id" BU_ EBCM_HS 3;
BA_ "SourceId" BU_ EBCM_HS 40;
BA_ "VNECUSLHS_VNReq" BU_ ACC_HS 4;
BA_ "VNECUSLHSSharedDiagnostic" BU_ ACC_HS 4;
BA_ "DAE_NE3" BU_ ACC_HS 1;
BA_ "DAE_N78" BU_ ACC_HS 1;
BA_ "DAE_N31" BU_ ACC_HS 1;
BA_ "DAE_N12" BU_ ACC_HS 1;
BA_ "DAE_FDevCtrl" BU_ ACC_HS 1;
BA_ "DAA_N81" BU_ ACC_HS 1;
BA_ "DAA_N78" BU_ ACC_HS 1;
BA_ "DAA_N31" BU_ ACC_HS 1;
BA_ "DAA_N12" BU_ ACC_HS 1;
BA_ "DAA_L04_FastRate" BU_ ACC_HS 1;
BA_ "DAA_L03_MedRate" BU_ ACC_HS 1;
BA_ "DAA_L02_SlowRate" BU_ ACC_HS 1;
BA_ "DAA_L01_SndOneRsp" BU_ ACC_HS 1;
BA_ "DAA_L00_StopSnd" BU_ ACC_HS 1;
BA_ "DAA_FRdDPID" BU_ ACC_HS 1;
BA_ "DA9_N78" BU_ ACC_HS 1;
BA_ "DA9_N31" BU_ ACC_HS 1;
BA_ "DA9_N12" BU_ ACC_HS 1;
BA_ "DA9_L82_SndChgDTC" BU_ ACC_HS 1;
BA_ "DA9_L81_RdStatDTCbyMsk" BU_ ACC_HS 1;
BA_ "DA9_L80_RdStatDTCbyNum" BU_ ACC_HS 1;
BA_ "DA5_N78" BU_ ACC_HS 1;
BA_ "DA5_N22" BU_ ACC_HS 1;
BA_ "DA5_N12" BU_ ACC_HS 1;
BA_ "DA5_L03_EnabProgMode" BU_ ACC_HS 1;
BA_ "DA5_L01_ReqProgMode" BU_ ACC_HS 1;
BA_ "DA2_N78" BU_ ACC_HS 1;
BA_ "DA2_N12" BU_ ACC_HS 1;
BA_ "D3E_N12" BU_ ACC_HS 1;
BA_ "D3B_N78" BU_ ACC_HS 1;
BA_ "D3B_N31" BU_ ACC_HS 1;
BA_ "D3B_N22" BU_ ACC_HS 1;
BA_ "D3B_N12" BU_ ACC_HS 1;
BA_ "D3B_FWrtBlk" BU_ ACC_HS 1;
BA_ "D36_N89" BU_ ACC_HS 1;
BA_ "D36_N85" BU_ ACC_HS 1;
BA_ "D36_N83" BU_ ACC_HS 1;
BA_ "D36_N78" BU_ ACC_HS 1;
BA_ "D36_N31" BU_ ACC_HS 1;
BA_ "D36_N22" BU_ ACC_HS 1;
BA_ "D36_N12" BU_ ACC_HS 1;
BA_ "D36_L80_DwnldExec" BU_ ACC_HS 1;
BA_ "D36_L00_DownLoad" BU_ ACC_HS 1;
BA_ "D34_N99" BU_ ACC_HS 1;
BA_ "D34_N78" BU_ ACC_HS 1;
BA_ "D34_N22" BU_ ACC_HS 1;
BA_ "D34_N12" BU_ ACC_HS 1;
BA_ "D28_N22" BU_ ACC_HS 1;
BA_ "D28_N12" BU_ ACC_HS 1;
BA_ "D27_N78" BU_ ACC_HS 1;
BA_ "D27_N37" BU_ ACC_HS 1;
BA_ "D27_N36" BU_ ACC_HS 1;
BA_ "D27_N35" BU_ ACC_HS 1;
BA_ "D27_N22" BU_ ACC_HS 1;
BA_ "D27_N12" BU_ ACC_HS 1;
BA_ "D27_L04_DevCtrlSeedKey" BU_ ACC_HS 1;
BA_ "D27_L03_CtrlReqSeed" BU_ ACC_HS 1;
BA_ "D27_L02_SndKey" BU_ ACC_HS 1;
BA_ "D27_L01_ReqSeed" BU_ ACC_HS 1;
BA_ "D27_FSecAcc" BU_ ACC_HS 1;
BA_ "D23_N78" BU_ ACC_HS 1;
BA_ "D23_N31" BU_ ACC_HS 1;
BA_ "D23_N12" BU_ ACC_HS 1;
BA_ "D23_FRdMemAddr" BU_ ACC_HS 1;
BA_ "D20_N12" BU_ ACC_HS 1;
BA_ "D1A_N78" BU_ ACC_HS 1;
BA_ "D1A_N31" BU_ ACC_HS 1;
BA_ "D1A_N22" BU_ ACC_HS 1;
BA_ "D1A_N12" BU_ ACC_HS 1;
BA_ "D12_N78" BU_ ACC_HS 1;
BA_ "D12_N31" BU_ ACC_HS 1;
BA_ "D12_N12" BU_ ACC_HS 1;
BA_ "D12_L02_RdFRcdParam" BU_ ACC_HS 1;
BA_ "D12_L01_RdFRcdData" BU_ ACC_HS 1;
BA_ "D12_FRdFailRec" BU_ ACC_HS 1;
BA_ "D10_N78" BU_ ACC_HS 1;
BA_ "D10_N22" BU_ ACC_HS 1;
BA_ "D10_N12" BU_ ACC_HS 1;
BA_ "D10_L03_DTCsDurDevCtrl" BU_ ACC_HS 1;
BA_ "D10_L02_DisAllDTCs" BU_ ACC_HS 1;
BA_ "D04_N78" BU_ ACC_HS 1;
BA_ "D04_N22" BU_ ACC_HS 1;
BA_ "D04_N12" BU_ ACC_HS 1;
BA_ "VNECUAllNodes" BU_ ACC_HS 4;
BA_ "ECU_Id" BU_ ACC_HS 27;
BA_ "SourceId" BU_ ACC_HS 33;
BA_ "VNECUSLHS_VNReq" BU_ BCM_HS 4;
BA_ "VNECUSLHSSharedDiagnostic" BU_ BCM_HS 4;
BA_ "DAE_NE3" BU_ BCM_HS 1;
BA_ "DAE_N78" BU_ BCM_HS 1;
BA_ "DAE_N31" BU_ BCM_HS 1;
BA_ "DAE_N12" BU_ BCM_HS 1;
BA_ "DAE_FDevCtrl" BU_ BCM_HS 1;
BA_ "DAA_N81" BU_ BCM_HS 1;
BA_ "DAA_N78" BU_ BCM_HS 1;
BA_ "DAA_N31" BU_ BCM_HS 1;
BA_ "DAA_N12" BU_ BCM_HS 1;
BA_ "DAA_L04_FastRate" BU_ BCM_HS 1;
BA_ "DAA_L03_MedRate" BU_ BCM_HS 1;
BA_ "DAA_L02_SlowRate" BU_ BCM_HS 1;
BA_ "DAA_L01_SndOneRsp" BU_ BCM_HS 1;
BA_ "DAA_L00_StopSnd" BU_ BCM_HS 1;
BA_ "DAA_FRdDPID" BU_ BCM_HS 1;
BA_ "DA9_N78" BU_ BCM_HS 1;
BA_ "DA9_N31" BU_ BCM_HS 1;
BA_ "DA9_N12" BU_ BCM_HS 1;
BA_ "DA5_N78" BU_ BCM_HS 1;
BA_ "DA5_N22" BU_ BCM_HS 1;
BA_ "DA5_N12" BU_ BCM_HS 1;
BA_ "DA5_L03_EnabProgMode" BU_ BCM_HS 1;
BA_ "DA5_L01_ReqProgMode" BU_ BCM_HS 1;
BA_ "DA2_N78" BU_ BCM_HS 1;
BA_ "DA2_N12" BU_ BCM_HS 1;
BA_ "D3E_N12" BU_ BCM_HS 1;
BA_ "D3B_N78" BU_ BCM_HS 1;
BA_ "D3B_N31" BU_ BCM_HS 1;
BA_ "D3B_N22" BU_ BCM_HS 1;
BA_ "D3B_N12" BU_ BCM_HS 1;
BA_ "D3B_FWrtBlk" BU_ BCM_HS 1;
BA_ "D36_N85" BU_ BCM_HS 1;
BA_ "D36_N83" BU_ BCM_HS 1;
BA_ "D36_N78" BU_ BCM_HS 1;
BA_ "D36_N31" BU_ BCM_HS 1;
BA_ "D36_N22" BU_ BCM_HS 1;
BA_ "D36_N12" BU_ BCM_HS 1;
BA_ "D36_L80_DwnldExec" BU_ BCM_HS 1;
BA_ "D36_L00_DownLoad" BU_ BCM_HS 1;
BA_ "D34_N99" BU_ BCM_HS 1;
BA_ "D34_N78" BU_ BCM_HS 1;
BA_ "D34_N22" BU_ BCM_HS 1;
BA_ "D34_N12" BU_ BCM_HS 1;
BA_ "D2C_N78" BU_ BCM_HS 1;
BA_ "D2C_N31" BU_ BCM_HS 1;
BA_ "D2C_N12" BU_ BCM_HS 1;
BA_ "D2C_FDynMsg" BU_ BCM_HS 1;
BA_ "D28_N22" BU_ BCM_HS 1;
BA_ "D28_N12" BU_ BCM_HS 1;
BA_ "D27_N78" BU_ BCM_HS 1;
BA_ "D27_N37" BU_ BCM_HS 1;
BA_ "D27_N36" BU_ BCM_HS 1;
BA_ "D27_N35" BU_ BCM_HS 1;
BA_ "D27_N22" BU_ BCM_HS 1;
BA_ "D27_N12" BU_ BCM_HS 1;
BA_ "D27_L02_SndKey" BU_ BCM_HS 1;
BA_ "D27_L01_ReqSeed" BU_ BCM_HS 1;
BA_ "D27_FSecAcc" BU_ BCM_HS 1;
BA_ "D23_N78" BU_ BCM_HS 1;
BA_ "D23_N31" BU_ BCM_HS 1;
BA_ "D23_N12" BU_ BCM_HS 1;
BA_ "D23_FRdMemAddr" BU_ BCM_HS 1;
BA_ "D20_N12" BU_ BCM_HS 1;
BA_ "D1A_N78" BU_ BCM_HS 1;
BA_ "D1A_N31" BU_ BCM_HS 1;
BA_ "D1A_N22" BU_ BCM_HS 1;
BA_ "D1A_N12" BU_ BCM_HS 1;
BA_ "D10_N78" BU_ BCM_HS 1;
BA_ "D10_N22" BU_ BCM_HS 1;
BA_ "D10_N12" BU_ BCM_HS 1;
BA_ "D10_L04_WakeUpLinks" BU_ BCM_HS 1;
BA_ "D10_L03_DTCsDurDevCtrl" BU_ BCM_HS 1;
BA_ "D10_L02_DisAllDTCs" BU_ BCM_HS 1;
BA_ "D04_N78" BU_ BCM_HS 1;
BA_ "D04_N22" BU_ BCM_HS 1;
BA_ "D04_N12" BU_ BCM_HS 1;
BA_ "VNECUAllNodes" BU_ BCM_HS 4;
BA_ "ECU_Id" BU_ BCM_HS 1;
BA_ "SourceId" BU_ BCM_HS 64;
BA_ "VNECUSLHS_VNReq" BU_ TCM_HS 4;
BA_ "VNECUSLHSSharedDiagnostic" BU_ TCM_HS 4;
BA_ "DAE_NE3" BU_ TCM_HS 1;
BA_ "DAE_N78" BU_ TCM_HS 1;
BA_ "DAE_N31" BU_ TCM_HS 1;
BA_ "DAE_N12" BU_ TCM_HS 1;
BA_ "DAE_FDevCtrl" BU_ TCM_HS 1;
BA_ "DAA_N81" BU_ TCM_HS 1;
BA_ "DAA_N78" BU_ TCM_HS 1;
BA_ "DAA_N31" BU_ TCM_HS 1;
BA_ "DAA_N12" BU_ TCM_HS 1;
BA_ "DAA_L04_FastRate" BU_ TCM_HS 1;
BA_ "DAA_L03_MedRate" BU_ TCM_HS 1;
BA_ "DAA_L02_SlowRate" BU_ TCM_HS 1;
BA_ "DAA_L01_SndOneRsp" BU_ TCM_HS 1;
BA_ "DAA_L00_StopSnd" BU_ TCM_HS 1;
BA_ "DAA_FRdDPID" BU_ TCM_HS 1;
BA_ "DA9_N78" BU_ TCM_HS 1;
BA_ "DA9_N31" BU_ TCM_HS 1;
BA_ "DA9_N12" BU_ TCM_HS 1;
BA_ "DA9_L82_SndChgDTC" BU_ TCM_HS 1;
BA_ "DA9_L81_RdStatDTCbyMsk" BU_ TCM_HS 1;
BA_ "DA9_L80_RdStatDTCbyNum" BU_ TCM_HS 1;
BA_ "DA5_N78" BU_ TCM_HS 1;
BA_ "DA5_N22" BU_ TCM_HS 1;
BA_ "DA5_N12" BU_ TCM_HS 1;
BA_ "DA5_L03_EnabProgMode" BU_ TCM_HS 1;
BA_ "DA5_L01_ReqProgMode" BU_ TCM_HS 1;
BA_ "DA2_N78" BU_ TCM_HS 1;
BA_ "DA2_N12" BU_ TCM_HS 1;
BA_ "D3E_N12" BU_ TCM_HS 1;
BA_ "D3B_N78" BU_ TCM_HS 1;
BA_ "D3B_N31" BU_ TCM_HS 1;
BA_ "D3B_N22" BU_ TCM_HS 1;
BA_ "D3B_N12" BU_ TCM_HS 1;
BA_ "D3B_FWrtBlk" BU_ TCM_HS 1;
BA_ "D36_N89" BU_ TCM_HS 1;
BA_ "D36_N85" BU_ TCM_HS 1;
BA_ "D36_N83" BU_ TCM_HS 1;
BA_ "D36_N78" BU_ TCM_HS 1;
BA_ "D36_N31" BU_ TCM_HS 1;
BA_ "D36_N22" BU_ TCM_HS 1;
BA_ "D36_N12" BU_ TCM_HS 1;
BA_ "D36_L80_DwnldExec" BU_ TCM_HS 1;
BA_ "D36_L00_DownLoad" BU_ TCM_HS 1;
BA_ "D34_N99" BU_ TCM_HS 1;
BA_ "D34_N78" BU_ TCM_HS 1;
BA_ "D34_N22" BU_ TCM_HS 1;
BA_ "D34_N12" BU_ TCM_HS 1;
BA_ "D2C_N78" BU_ TCM_HS 1;
BA_ "D2C_N31" BU_ TCM_HS 1;
BA_ "D2C_N12" BU_ TCM_HS 1;
BA_ "D2C_FDynMsg" BU_ TCM_HS 1;
BA_ "D28_N22" BU_ TCM_HS 1;
BA_ "D28_N12" BU_ TCM_HS 1;
BA_ "D27_N78" BU_ TCM_HS 1;
BA_ "D27_N37" BU_ TCM_HS 1;
BA_ "D27_N36" BU_ TCM_HS 1;
BA_ "D27_N35" BU_ TCM_HS 1;
BA_ "D27_N22" BU_ TCM_HS 1;
BA_ "D27_N12" BU_ TCM_HS 1;
BA_ "D27_L04_DevCtrlSeedKey" BU_ TCM_HS 1;
BA_ "D27_L03_CtrlReqSeed" BU_ TCM_HS 1;
BA_ "D27_L02_SndKey" BU_ TCM_HS 1;
BA_ "D27_L01_ReqSeed" BU_ TCM_HS 1;
BA_ "D27_FSecAcc" BU_ TCM_HS 1;
BA_ "D23_N78" BU_ TCM_HS 1;
BA_ "D23_N31" BU_ TCM_HS 1;
BA_ "D23_N12" BU_ TCM_HS 1;
BA_ "D23_FRdMemAddr" BU_ TCM_HS 1;
BA_ "D20_N12" BU_ TCM_HS 1;
BA_ "D1A_N78" BU_ TCM_HS 1;
BA_ "D1A_N31" BU_ TCM_HS 1;
BA_ "D1A_N22" BU_ TCM_HS 1;
BA_ "D1A_N12" BU_ TCM_HS 1;
BA_ "D12_N78" BU_ TCM_HS 1;
BA_ "D12_N31" BU_ TCM_HS 1;
BA_ "D12_N12" BU_ TCM_HS 1;
BA_ "D12_L02_RdFRcdParam" BU_ TCM_HS 1;
BA_ "D12_L01_RdFRcdData" BU_ TCM_HS 1;
BA_ "D12_FRdFailRec" BU_ TCM_HS 1;
BA_ "D10_N78" BU_ TCM_HS 1;
BA_ "D10_N22" BU_ TCM_HS 1;
BA_ "D10_N12" BU_ TCM_HS 1;
BA_ "D10_L03_DTCsDurDevCtrl" BU_ TCM_HS 1;
BA_ "D10_L02_DisAllDTCs" BU_ TCM_HS 1;
BA_ "D04_ReqType" BU_ TCM_HS 0;
BA_ "D04_N78" BU_ TCM_HS 1;
BA_ "D04_N22" BU_ TCM_HS 1;
BA_ "D04_N12" BU_ TCM_HS 1;
BA_ "VNECUAllNodes" BU_ TCM_HS 4;
BA_ "ECU_Id" BU_ TCM_HS 226;
BA_ "SourceId" BU_ TCM_HS 24;
BA_ "VNECUSLHS_VNReq" BU_ ECM_HS 4;
BA_ "VNECUSLHSSharedDiagnostic" BU_ ECM_HS 4;
BA_ "DAE_NE3" BU_ ECM_HS 1;
BA_ "DAE_N78" BU_ ECM_HS 1;
BA_ "DAE_N31" BU_ ECM_HS 1;
BA_ "DAE_N12" BU_ ECM_HS 1;
BA_ "DAE_FDevCtrl" BU_ ECM_HS 1;
BA_ "DAA_N81" BU_ ECM_HS 1;
BA_ "DAA_N78" BU_ ECM_HS 1;
BA_ "DAA_N31" BU_ ECM_HS 1;
BA_ "DAA_N12" BU_ ECM_HS 1;
BA_ "DAA_L04_FastRate" BU_ ECM_HS 1;
BA_ "DAA_L03_MedRate" BU_ ECM_HS 1;
BA_ "DAA_L02_SlowRate" BU_ ECM_HS 1;
BA_ "DAA_L01_SndOneRsp" BU_ ECM_HS 1;
BA_ "DAA_L00_StopSnd" BU_ ECM_HS 1;
BA_ "DAA_FRdDPID" BU_ ECM_HS 1;
BA_ "DA9_N78" BU_ ECM_HS 1;
BA_ "DA9_N31" BU_ ECM_HS 1;
BA_ "DA9_N12" BU_ ECM_HS 1;
BA_ "DA9_L82_SndChgDTC" BU_ ECM_HS 1;
BA_ "DA9_L81_RdStatDTCbyMsk" BU_ ECM_HS 1;
BA_ "DA9_L80_RdStatDTCbyNum" BU_ ECM_HS 1;
BA_ "DA5_N78" BU_ ECM_HS 1;
BA_ "DA5_N22" BU_ ECM_HS 1;
BA_ "DA5_N12" BU_ ECM_HS 1;
BA_ "DA5_L03_EnabProgMode" BU_ ECM_HS 1;
BA_ "DA5_L01_ReqProgMode" BU_ ECM_HS 1;
BA_ "DA2_N78" BU_ ECM_HS 1;
BA_ "DA2_N12" BU_ ECM_HS 1;
BA_ "D3E_N12" BU_ ECM_HS 1;
BA_ "D3B_N78" BU_ ECM_HS 1;
BA_ "D3B_N31" BU_ ECM_HS 1;
BA_ "D3B_N22" BU_ ECM_HS 1;
BA_ "D3B_N12" BU_ ECM_HS 1;
BA_ "D3B_FWrtBlk" BU_ ECM_HS 1;
BA_ "D36_N89" BU_ ECM_HS 1;
BA_ "D36_N85" BU_ ECM_HS 1;
BA_ "D36_N83" BU_ ECM_HS 1;
BA_ "D36_N78" BU_ ECM_HS 1;
BA_ "D36_N31" BU_ ECM_HS 1;
BA_ "D36_N22" BU_ ECM_HS 1;
BA_ "D36_N12" BU_ ECM_HS 1;
BA_ "D36_L80_DwnldExec" BU_ ECM_HS 1;
BA_ "D36_L00_DownLoad" BU_ ECM_HS 1;
BA_ "D34_N99" BU_ ECM_HS 1;
BA_ "D34_N78" BU_ ECM_HS 1;
BA_ "D34_N22" BU_ ECM_HS 1;
BA_ "D34_N12" BU_ ECM_HS 1;
BA_ "D2C_N78" BU_ ECM_HS 1;
BA_ "D2C_N31" BU_ ECM_HS 1;
BA_ "D2C_N12" BU_ ECM_HS 1;
BA_ "D2C_FDynMsg" BU_ ECM_HS 1;
BA_ "D28_N22" BU_ ECM_HS 1;
BA_ "D28_N12" BU_ ECM_HS 1;
BA_ "D27_N78" BU_ ECM_HS 1;
BA_ "D27_N37" BU_ ECM_HS 1;
BA_ "D27_N36" BU_ ECM_HS 1;
BA_ "D27_N35" BU_ ECM_HS 1;
BA_ "D27_N22" BU_ ECM_HS 1;
BA_ "D27_N12" BU_ ECM_HS 1;
BA_ "D27_L04_DevCtrlSeedKey" BU_ ECM_HS 1;
BA_ "D27_L03_CtrlReqSeed" BU_ ECM_HS 1;
BA_ "D27_L02_SndKey" BU_ ECM_HS 1;
BA_ "D27_L01_ReqSeed" BU_ ECM_HS 1;
BA_ "D27_FSecAcc" BU_ ECM_HS 1;
BA_ "D23_N78" BU_ ECM_HS 1;
BA_ "D23_N31" BU_ ECM_HS 1;
BA_ "D23_N12" BU_ ECM_HS 1;
BA_ "D23_FRdMemAddr" BU_ ECM_HS 1;
BA_ "D20_N12" BU_ ECM_HS 1;
BA_ "D1A_N78" BU_ ECM_HS 1;
BA_ "D1A_N31" BU_ ECM_HS 1;
BA_ "D1A_N22" BU_ ECM_HS 1;
BA_ "D1A_N12" BU_ ECM_HS 1;
BA_ "D12_N78" BU_ ECM_HS 1;
BA_ "D12_N31" BU_ ECM_HS 1;
BA_ "D12_N12" BU_ ECM_HS 1;
BA_ "D12_L02_RdFRcdParam" BU_ ECM_HS 1;
BA_ "D12_L01_RdFRcdData" BU_ ECM_HS 1;
BA_ "D12_FRdFailRec" BU_ ECM_HS 1;
BA_ "D10_N78" BU_ ECM_HS 1;
BA_ "D10_N22" BU_ ECM_HS 1;
BA_ "D10_N12" BU_ ECM_HS 1;
BA_ "D10_L03_DTCsDurDevCtrl" BU_ ECM_HS 1;
BA_ "D10_L02_DisAllDTCs" BU_ ECM_HS 1;
BA_ "D04_ReqType" BU_ ECM_HS 0;
BA_ "D04_N78" BU_ ECM_HS 1;
BA_ "D04_N22" BU_ ECM_HS 1;
BA_ "D04_N12" BU_ ECM_HS 1;
BA_ "VNECUAllNodes" BU_ ECM_HS 4;
BA_ "ECU_Id" BU_ ECM_HS 224;
BA_ "SourceId" BU_ ECM_HS 17;
BA_ "Prio" BO_ 844 0;
BA_ "MessageSubnet" BO_ 844 2;
BA_ "GenMsgCycleTime" BO_ 844 50;
BA_ "GenMsgSendType" BO_ 844 0;
BA_ "Prio" BO_ 308 0;
BA_ "MessageSubnet" BO_ 308 2;
BA_ "GenMsgCycleTime" BO_ 308 1000;
BA_ "GenMsgSendType" BO_ 308 0;
BA_ "Prio" BO_ 806 0;
BA_ "MessageSubnet" BO_ 806 2;
BA_ "GenMsgCycleTime" BO_ 806 500;
BA_ "GenMsgSendType" BO_ 806 0;
BA_ "Prio" BO_ 426 0;
BA_ "MessageSubnet" BO_ 426 2;
BA_ "GenMsgCycleTime" BO_ 426 25;
BA_ "GenMsgSendType" BO_ 426 0;
BA_ "Prio" BO_ 1231 0;
BA_ "MessageSubnet" BO_ 1231 2;
BA_ "GenMsgCycleTime" BO_ 1231 1000;
BA_ "GenMsgSendType" BO_ 1231 0;
BA_ "Prio" BO_ 963 0;
BA_ "MessageSubnet" BO_ 963 2;
BA_ "GenMsgCycleTime" BO_ 963 100;
BA_ "GenMsgSendType" BO_ 963 0;
BA_ "Prio" BO_ 955 0;
BA_ "MessageSubnet" BO_ 955 2;
BA_ "GenMsgCycleTime" BO_ 955 100;
BA_ "GenMsgSendType" BO_ 955 0;
BA_ "Prio" BO_ 208 0;
BA_ "MessageSubnet" BO_ 208 2;
BA_ "GenMsgCycleTime" BO_ 208 100;
BA_ "GenMsgSendType" BO_ 208 0;
BA_ "Prio" BO_ 2034 0;
BA_ "MessageSubnet" BO_ 2034 2;
BA_ "DiagResponse" BO_ 2034 1;
BA_ "Prio" BO_ 2032 0;
BA_ "MessageSubnet" BO_ 2032 2;
BA_ "DiagRequest" BO_ 2032 1;
BA_ "Prio" BO_ 563 0;
BA_ "MessageSubnet" BO_ 563 2;
BA_ "GenMsgCycleTime" BO_ 563 2000;
BA_ "GenMsgSendType" BO_ 563 0;
BA_ "Prio" BO_ 1323 0;
BA_ "MessageSubnet" BO_ 1323 2;
BA_ "GenMsgCycleTime" BO_ 1323 1000;
BA_ "GenMsgSendType" BO_ 1323 0;
BA_ "Prio" BO_ 1247 0;
BA_ "MessageSubnet" BO_ 1247 2;
BA_ "GenMsgCycleTime" BO_ 1247 500;
BA_ "GenMsgSendType" BO_ 1247 0;
BA_ "Prio" BO_ 873 0;
BA_ "MessageSubnet" BO_ 873 2;
BA_ "GenMsgCycleTime" BO_ 873 100;
BA_ "GenMsgSendType" BO_ 873 0;
BA_ "Prio" BO_ 306 0;
BA_ "MessageSubnet" BO_ 306 2;
BA_ "GenMsgCycleTime" BO_ 306 100;
BA_ "GenMsgSendType" BO_ 306 0;
BA_ "Prio" BO_ 723 0;
BA_ "MessageSubnet" BO_ 723 2;
BA_ "GenMsgCycleTime" BO_ 723 50;
BA_ "GenMsgSendType" BO_ 723 0;
BA_ "Prio" BO_ 405 0;
BA_ "MessageSubnet" BO_ 405 2;
BA_ "GenMsgCycleTime" BO_ 405 12;
BA_ "GenMsgSendType" BO_ 405 0;
BA_ "Prio" BO_ 419 0;
BA_ "MessageSubnet" BO_ 419 2;
BA_ "GenMsgCycleTime" BO_ 419 25;
BA_ "GenMsgSendType" BO_ 419 0;
BA_ "Prio" BO_ 289 0;
BA_ "MessageSubnet" BO_ 289 2;
BA_ "GenMsgCycleTime" BO_ 289 20;
BA_ "GenMsgSendType" BO_ 289 0;
BA_ "Prio" BO_ 871 0;
BA_ "MessageSubnet" BO_ 871 2;
BA_ "GenMsgCycleTime" BO_ 871 100;
BA_ "GenMsgSendType" BO_ 871 0;
BA_ "Prio" BO_ 800 0;
BA_ "MessageSubnet" BO_ 800 2;
BA_ "GenMsgCycleTime" BO_ 800 100;
BA_ "GenMsgSendType" BO_ 800 0;
BA_ "Prio" BO_ 388 0;
BA_ "MessageSubnet" BO_ 388 2;
BA_ "GenMsgCycleTime" BO_ 388 100;
BA_ "GenMsgSendType" BO_ 388 0;
BA_ "Prio" BO_ 384 0;
BA_ "MessageSubnet" BO_ 384 2;
BA_ "GenMsgCycleTime" BO_ 384 100;
BA_ "GenMsgSendType" BO_ 384 0;
BA_ "Prio" BO_ 866 0;
BA_ "MessageSubnet" BO_ 866 2;
BA_ "GenMsgCycleTime" BO_ 866 50;
BA_ "GenMsgSendType" BO_ 866 0;
BA_ "Prio" BO_ 951 0;
BA_ "MessageSubnet" BO_ 951 2;
BA_ "GenMsgCycleTime" BO_ 951 100;
BA_ "GenMsgSendType" BO_ 951 0;
BA_ "Prio" BO_ 949 0;
BA_ "MessageSubnet" BO_ 949 2;
BA_ "GenMsgCycleTime" BO_ 949 100;
BA_ "GenMsgSendType" BO_ 949 0;
BA_ "Prio" BO_ 1223 0;
BA_ "MessageSubnet" BO_ 1223 2;
BA_ "GenMsgCycleTime" BO_ 1223 500;
BA_ "GenMsgSendType" BO_ 1223 0;
BA_ "Prio" BO_ 1227 0;
BA_ "MessageSubnet" BO_ 1227 2;
BA_ "GenMsgCycleTime" BO_ 1227 500;
BA_ "GenMsgSendType" BO_ 1227 0;
BA_ "Prio" BO_ 543 0;
BA_ "MessageSubnet" BO_ 543 2;
BA_ "GenMsgCycleTime" BO_ 543 100;
BA_ "GenMsgSendType" BO_ 543 0;
BA_ "Prio" BO_ 544 0;
BA_ "MessageSubnet" BO_ 544 2;
BA_ "GenMsgCycleTime" BO_ 544 250;
BA_ "GenMsgSendType" BO_ 544 0;
BA_ "SignalType" SG_ 844 IMUProtYawRtM "ENM";
BA_ "SignalLongName" SG_ 844 IMUProtYawRtM "Inertial Measurement Unit Protected Yaw Rate Mask";
BA_ "VNSigAllNodes" SG_ 844 IMUProtYawRtM 1;
BA_ "SignalType" SG_ 844 IMUProtYawRt "SNM";
BA_ "SignalLongName" SG_ 844 IMUProtYawRt "Inertial Measurement Unit Protected Yaw Rate";
BA_ "VNSigAllNodes" SG_ 844 IMUProtYawRt 1;
BA_ "SignalType" SG_ 844 IMUProtLonAccM "ENM";
BA_ "SignalLongName" SG_ 844 IMUProtLonAccM "Inertial Measurement Unit Protected Longitudinal Acceleration Mask";
BA_ "VNSigAllNodes" SG_ 844 IMUProtLonAccM 1;
BA_ "SignalType" SG_ 844 IMUProtLonAcc "SNM";
BA_ "SignalLongName" SG_ 844 IMUProtLonAcc "Inertial Measurement Unit Protected Longitudinal Acceleration";
BA_ "VNSigAllNodes" SG_ 844 IMUProtLonAcc 1;
BA_ "SignalType" SG_ 844 IMUProtLatAccM "ENM";
BA_ "SignalLongName" SG_ 844 IMUProtLatAccM "Inertial Measurement Unit Protected Lateral Acceleration Mask";
BA_ "VNSigAllNodes" SG_ 844 IMUProtLatAccM 1;
BA_ "SignalType" SG_ 844 IMUProtLatAcc "SNM";
BA_ "SignalLongName" SG_ 844 IMUProtLatAcc "Inertial Measurement Unit Protected Lateral Acceleration";
BA_ "VNSigAllNodes" SG_ 844 IMUProtLatAcc 1;
BA_ "SignalType" SG_ 844 IMUProtChksum "UNM";
BA_ "SignalLongName" SG_ 844 IMUProtChksum "Inertial Measurement Unit Protected Checksum";
BA_ "VNSigAllNodes" SG_ 844 IMUProtChksum 1;
BA_ "SignalType" SG_ 844 IMUProtARC "UNM";
BA_ "SignalLongName" SG_ 844 IMUProtARC "Inertial Measurement Unit Protected Alive Rolling Count";
BA_ "VNSigAllNodes" SG_ 844 IMUProtARC 1;
BA_ "SignalType" SG_ 308 PFAS_SrvPedAlrtIO "BLN";
BA_ "SignalLongName" SG_ 308 PFAS_SrvPedAlrtIO "Pedestrian Friendly Alert Status : Service Pedestrian Friendly Alert Indication On";
BA_ "VNSigAllNodes" SG_ 308 PFAS_SrvPedAlrtIO 1;
BA_ "SignalType" SG_ 308 PFAS_PFASysStat "ENM";
BA_ "SignalLongName" SG_ 308 PFAS_PFASysStat "Pedestrian Friendly Alert Status : Pedestrian Friendly Alert System Status";
BA_ "VNSigAllNodes" SG_ 308 PFAS_PFASysStat 1;
BA_ "SignalType" SG_ 308 PFAS_PFASndVolCtrl "UNM";
BA_ "SignalLongName" SG_ 308 PFAS_PFASndVolCtrl "Pedestrian Friendly Alert Status : Pedestrian Friendly Alert Sound Volume Control";
BA_ "VNSigAllNodes" SG_ 308 PFAS_PFASndVolCtrl 1;
BA_ "SignalType" SG_ 308 PFAS_PFASndGenEn "BLN";
BA_ "SignalLongName" SG_ 308 PFAS_PFASndGenEn "Pedestrian Friendly Alert Status : Pedestrian Friendly Alert Sound Generation Enable";
BA_ "VNSigAllNodes" SG_ 308 PFAS_PFASndGenEn 1;
BA_ "SignalType" SG_ 308 PFAS_PFARevSnd "ENM";
BA_ "SignalLongName" SG_ 308 PFAS_PFARevSnd "Pedestrian Friendly Alert Status : Pedestrian Friendly Alert Reverse Sound";
BA_ "VNSigAllNodes" SG_ 308 PFAS_PFARevSnd 1;
BA_ "SignalType" SG_ 308 PFAS_PFAFwdSnd "ENM";
BA_ "SignalLongName" SG_ 308 PFAS_PFAFwdSnd "Pedestrian Friendly Alert Status : Pedestrian Friendly Alert Forward Sound";
BA_ "VNSigAllNodes" SG_ 308 PFAS_PFAFwdSnd 1;
BA_ "SignalType" SG_ 308 PFAS_PFACrsOvrSpd "UNM";
BA_ "SignalLongName" SG_ 308 PFAS_PFACrsOvrSpd "Pedestrian Friendly Alert Status : Pedestrian Friendly Alert Crossover Speed";
BA_ "VNSigAllNodes" SG_ 308 PFAS_PFACrsOvrSpd 1;
BA_ "SignalType" SG_ 308 PedFrndlyAlrtCsSetAvl "BLN";
BA_ "SignalLongName" SG_ 308 PedFrndlyAlrtCsSetAvl "Pedestrian Friendly Alert Customization Setting Available";
BA_ "VNSigAllNodes" SG_ 308 PedFrndlyAlrtCsSetAvl 1;
BA_ "SignalType" SG_ 308 PedFrndlyAlrtCsCrStVal "ENM";
BA_ "SignalLongName" SG_ 308 PedFrndlyAlrtCsCrStVal "Pedestrian Friendly Alert Customization Current Setting Value";
BA_ "VNSigAllNodes" SG_ 308 PedFrndlyAlrtCsCrStVal 1;
BA_ "SignalType" SG_ 806 DCCnvStblznErrIO "BLN";
BA_ "SignalLongName" SG_ 806 DCCnvStblznErrIO "DC Converter Stabilization Error Indication On";
BA_ "VNSigAllNodes" SG_ 806 DCCnvStblznErrIO 1;
BA_ "SignalType" SG_ 426 EngPrdctStdyStTorq "UNM";
BA_ "SignalLongName" SG_ 426 EngPrdctStdyStTorq "Engine Predicted Steady State Torque";
BA_ "VNSigAllNodes" SG_ 426 EngPrdctStdyStTorq 1;
BA_ "SignalType" SG_ 426 EngPrdctStdyStTorqV "ENM";
BA_ "SignalLongName" SG_ 426 EngPrdctStdyStTorqV "Engine Predicted Steady State Torque Validity";
BA_ "VNSigAllNodes" SG_ 426 EngPrdctStdyStTorqV 1;
BA_ "SignalType" SG_ 426 CrnkShftTrqMinOffCapV "ENM";
BA_ "SignalLongName" SG_ 426 CrnkShftTrqMinOffCapV "Crankshaft Torque Minimum Off Capacity Validity";
BA_ "VNSigAllNodes" SG_ 426 CrnkShftTrqMinOffCapV 1;
BA_ "SignalType" SG_ 426 CrnkShftTrqMinOffCap "UNM";
BA_ "SignalLongName" SG_ 426 CrnkShftTrqMinOffCap "Crankshaft Torque Minimum Off Capacity";
BA_ "VNSigAllNodes" SG_ 426 CrnkShftTrqMinOffCap 1;
BA_ "SignalType" SG_ 426 CrksftTqMinRunImCapV "ENM";
BA_ "SignalLongName" SG_ 426 CrksftTqMinRunImCapV "Crankshaft Torque Minimum Run Immediate Capacity Validity";
BA_ "VNSigAllNodes" SG_ 426 CrksftTqMinRunImCapV 1;
BA_ "SignalType" SG_ 426 CrksftTqMinRunImCap "UNM";
BA_ "SignalLongName" SG_ 426 CrksftTqMinRunImCap "Crankshaft Torque Minimum Run Immediate Capacity";
BA_ "VNSigAllNodes" SG_ 426 CrksftTqMinRunImCap 1;
BA_ "SignalType" SG_ 1231 DslExhFluidDistTIndcmt "UNM";
BA_ "SignalLongName" SG_ 1231 DslExhFluidDistTIndcmt "Diesel Exhaust Fluid Distance to Inducement";
BA_ "VNSigAllNodes" SG_ 1231 DslExhFluidDistTIndcmt 1;
BA_ "SignalType" SG_ 1231 DslExhFluidLvlPrcntV "ENM";
BA_ "SignalLongName" SG_ 1231 DslExhFluidLvlPrcntV "Diesel Exhaust Fluid Level Percent Validity";
BA_ "VNSigAllNodes" SG_ 1231 DslExhFluidLvlPrcntV 1;
BA_ "SignalType" SG_ 1231 DslExhFluidLvlPrcnt "UNM";
BA_ "SignalLongName" SG_ 1231 DslExhFluidLvlPrcnt "Diesel Exhaust Fluid Level Percent";
BA_ "VNSigAllNodes" SG_ 1231 DslExhFluidLvlPrcnt 1;
BA_ "SignalType" SG_ 963 CltTmpCntlMdEmRMAct "BLN";
BA_ "SignalLongName" SG_ 963 CltTmpCntlMdEmRMAct "Coolant Temperature Control Module Emissions Related Malfunction Active";
BA_ "VNSigAllNodes" SG_ 963 CltTmpCntlMdEmRMAct 1;
BA_ "SignalType" SG_ 963 CTCMERDTC_SysDes "ENM";
BA_ "SignalLongName" SG_ 963 CTCMERDTC_SysDes "Coolant Temperature Control Module Emissions Related DTC : System Designator";
BA_ "VNSigAllNodes" SG_ 963 CTCMERDTC_SysDes 1;
BA_ "SignalType" SG_ 963 CTCMERDTC_CdNum "UNM";
BA_ "PacketOrder" SG_ 963 CTCMERDTC_CdNum 1;
BA_ "SignalLongName" SG_ 963 CTCMERDTC_CdNum "Coolant Temperature Control Module Emissions Related DTC : Code Number";
BA_ "VNSigAllNodes" SG_ 963 CTCMERDTC_CdNum 1;
BA_ "SignalType" SG_ 955 RHCS_RdctHtrCCurrV "ENM";
BA_ "SignalLongName" SG_ 955 RHCS_RdctHtrCCurrV "Reductant Heater Circuits Status : Reductant Heater C Current Validity";
BA_ "VNSigAllNodes" SG_ 955 RHCS_RdctHtrCCurrV 1;
BA_ "SignalType" SG_ 955 RHCS_RdctHtrBCurrV "ENM";
BA_ "PacketOrder" SG_ 955 RHCS_RdctHtrBCurrV 2;
BA_ "SignalLongName" SG_ 955 RHCS_RdctHtrBCurrV "Reductant Heater Circuits Status : Reductant Heater B Current Validity";
BA_ "VNSigAllNodes" SG_ 955 RHCS_RdctHtrBCurrV 1;
BA_ "SignalType" SG_ 955 RHCS_RdctHtrACurrV "ENM";
BA_ "PacketOrder" SG_ 955 RHCS_RdctHtrACurrV 1;
BA_ "SignalLongName" SG_ 955 RHCS_RdctHtrACurrV "Reductant Heater Circuits Status : Reductant Heater A Current Validity";
BA_ "VNSigAllNodes" SG_ 955 RHCS_RdctHtrACurrV 1;
BA_ "SignalType" SG_ 955 RdctHtrCrntFdbckRC "UNM";
BA_ "SignalLongName" SG_ 955 RdctHtrCrntFdbckRC "Reductant Heaters Current Feedback Alive Rolling Count";
BA_ "VNSigAllNodes" SG_ 955 RdctHtrCrntFdbckRC 1;
BA_ "SignalType" SG_ 955 RdctHtrCctStatPV "UNM";
BA_ "SignalLongName" SG_ 955 RdctHtrCctStatPV "Reductant Heater Circuits Status Protection Value";
BA_ "VNSigAllNodes" SG_ 955 RdctHtrCctStatPV 1;
BA_ "SignalType" SG_ 955 RdctHtrCCrntFdbckPVa "UNM";
BA_ "SignalLongName" SG_ 955 RdctHtrCCrntFdbckPVa "Reductant Heater C Current Feedback Protection Value";
BA_ "VNSigAllNodes" SG_ 955 RdctHtrCCrntFdbckPVa 1;
BA_ "SignalType" SG_ 955 RdctHtrBCrntFdbckPVa "UNM";
BA_ "SignalLongName" SG_ 955 RdctHtrBCrntFdbckPVa "Reductant Heater B Current Feedback Protection Value";
BA_ "VNSigAllNodes" SG_ 955 RdctHtrBCrntFdbckPVa 1;
BA_ "SignalType" SG_ 955 RdctHtrACrntFdbckPVa "UNM";
BA_ "SignalLongName" SG_ 955 RdctHtrACrntFdbckPVa "Reductant Heater A Current Feedback Protection Value";
BA_ "VNSigAllNodes" SG_ 955 RdctHtrACrntFdbckPVa 1;
BA_ "SignalType" SG_ 955 RdctHtrCCrntFdbck "UNM";
BA_ "SignalLongName" SG_ 955 RdctHtrCCrntFdbck "Reductant Heater C Current Feedback";
BA_ "VNSigAllNodes" SG_ 955 RdctHtrCCrntFdbck 1;
BA_ "SignalType" SG_ 955 RdctHtrBCrntFdbck "UNM";
BA_ "SignalLongName" SG_ 955 RdctHtrBCrntFdbck "Reductant Heater B Current Feedback";
BA_ "VNSigAllNodes" SG_ 955 RdctHtrBCrntFdbck 1;
BA_ "SignalType" SG_ 955 RdctHtrACrntFdbck "UNM";
BA_ "SignalLongName" SG_ 955 RdctHtrACrntFdbck "Reductant Heater A Current Feedback";
BA_ "VNSigAllNodes" SG_ 955 RdctHtrACrntFdbck 1;
BA_ "SignalType" SG_ 208 WhlSlipRRWhl "UNM";
BA_ "SignalLongName" SG_ 208 WhlSlipRRWhl "Wheel Slip Right Rear Wheel";
BA_ "GenSigStartValue" SG_ 208 WhlSlipRRWhl 32768;
BA_ "VNSigAllNodes" SG_ 208 WhlSlipRRWhl 1;
BA_ "SignalType" SG_ 208 WhlSlipLRWhl "UNM";
BA_ "SignalLongName" SG_ 208 WhlSlipLRWhl "Wheel Slip Left Rear Wheel";
BA_ "GenSigStartValue" SG_ 208 WhlSlipLRWhl 32768;
BA_ "VNSigAllNodes" SG_ 208 WhlSlipLRWhl 1;
BA_ "SignalType" SG_ 208 WhlSlipRFWhl "UNM";
BA_ "SignalLongName" SG_ 208 WhlSlipRFWhl "Wheel Slip Right Front Wheel";
BA_ "GenSigStartValue" SG_ 208 WhlSlipRFWhl 32768;
BA_ "VNSigAllNodes" SG_ 208 WhlSlipRFWhl 1;
BA_ "SignalType" SG_ 208 WhlSlipLFWhl "UNM";
BA_ "SignalLongName" SG_ 208 WhlSlipLFWhl "Wheel Slip Left Front Wheel";
BA_ "GenSigStartValue" SG_ 208 WhlSlipLFWhl 32768;
BA_ "VNSigAllNodes" SG_ 208 WhlSlipLFWhl 1;
BA_ "VNSigSLHSSharedDiagnostic" SG_ 2034 DgnInf 1;
BA_ "SignalType" SG_ 2034 DgnInf "UNM";
BA_ "SignalLongName" SG_ 2034 DgnInf "Diagnostic Information";
BA_ "VNSigAllNodes" SG_ 2034 DgnInf 1;
BA_ "VNSigSLHSSharedDiagnostic" SG_ 2032 DgnInf 1;
BA_ "SignalType" SG_ 2032 DgnInf "UNM";
BA_ "SignalLongName" SG_ 2032 DgnInf "Diagnostic Information";
BA_ "VNSigAllNodes" SG_ 2032 DgnInf 1;
BA_ "SignalType" SG_ 563 SPMCA_SusPrfMd6Avl "BLN";
BA_ "SignalLongName" SG_ 563 SPMCA_SusPrfMd6Avl "Suspension Performance Mode Customization Available : Suspension Performance Mode 6 Available";
BA_ "VNSigAllNodes" SG_ 563 SPMCA_SusPrfMd6Avl 1;
BA_ "SignalType" SG_ 563 SPMCA_SusPrfMd5Avl "BLN";
BA_ "PacketOrder" SG_ 563 SPMCA_SusPrfMd5Avl 6;
BA_ "SignalLongName" SG_ 563 SPMCA_SusPrfMd5Avl "Suspension Performance Mode Customization Available : Suspension Performance Mode 5 Available";
BA_ "VNSigAllNodes" SG_ 563 SPMCA_SusPrfMd5Avl 1;
BA_ "SignalType" SG_ 563 SPMCA_SusPrfMd4Avl "BLN";
BA_ "PacketOrder" SG_ 563 SPMCA_SusPrfMd4Avl 5;
BA_ "SignalLongName" SG_ 563 SPMCA_SusPrfMd4Avl "Suspension Performance Mode Customization Available : Suspension Performance Mode 4 Available";
BA_ "VNSigAllNodes" SG_ 563 SPMCA_SusPrfMd4Avl 1;
BA_ "SignalType" SG_ 563 SPMCA_SusPrfMd3Avl "BLN";
BA_ "PacketOrder" SG_ 563 SPMCA_SusPrfMd3Avl 4;
BA_ "SignalLongName" SG_ 563 SPMCA_SusPrfMd3Avl "Suspension Performance Mode Customization Available : Suspension Performance Mode 3 Available";
BA_ "VNSigAllNodes" SG_ 563 SPMCA_SusPrfMd3Avl 1;
BA_ "SignalType" SG_ 563 SPMCA_SusPrfMd2Avl "BLN";
BA_ "PacketOrder" SG_ 563 SPMCA_SusPrfMd2Avl 3;
BA_ "SignalLongName" SG_ 563 SPMCA_SusPrfMd2Avl "Suspension Performance Mode Customization Available : Suspension Performance Mode 2 Available";
BA_ "VNSigAllNodes" SG_ 563 SPMCA_SusPrfMd2Avl 1;
BA_ "SignalType" SG_ 563 SPMCA_SusPrfMd1Avl "BLN";
BA_ "PacketOrder" SG_ 563 SPMCA_SusPrfMd1Avl 2;
BA_ "SignalLongName" SG_ 563 SPMCA_SusPrfMd1Avl "Suspension Performance Mode Customization Available : Suspension Performance Mode 1 Available";
BA_ "VNSigAllNodes" SG_ 563 SPMCA_SusPrfMd1Avl 1;
BA_ "PacketOrder" SG_ 563 SPMCA_StrPrfMd6Avl 1;
BA_ "SignalType" SG_ 563 SPMCA_StrPrfMd6Avl "BLN";
BA_ "SignalLongName" SG_ 563 SPMCA_StrPrfMd6Avl "Steering Performance Mode Customization Available : Steering Performance Mode 6 Available";
BA_ "VNSigAllNodes" SG_ 563 SPMCA_StrPrfMd6Avl 1;
BA_ "SignalType" SG_ 563 SPMCA_StrPrfMd5Avl "BLN";
BA_ "PacketOrder" SG_ 563 SPMCA_StrPrfMd5Avl 6;
BA_ "SignalLongName" SG_ 563 SPMCA_StrPrfMd5Avl "Steering Performance Mode Customization Available : Steering Performance Mode 5 Available";
BA_ "VNSigAllNodes" SG_ 563 SPMCA_StrPrfMd5Avl 1;
BA_ "SignalType" SG_ 563 SPMCA_StrPrfMd4Avl "BLN";
BA_ "PacketOrder" SG_ 563 SPMCA_StrPrfMd4Avl 5;
BA_ "SignalLongName" SG_ 563 SPMCA_StrPrfMd4Avl "Steering Performance Mode Customization Available : Steering Performance Mode 4 Available";
BA_ "VNSigAllNodes" SG_ 563 SPMCA_StrPrfMd4Avl 1;
BA_ "SignalType" SG_ 563 SPMCA_StrPrfMd3Avl "BLN";
BA_ "PacketOrder" SG_ 563 SPMCA_StrPrfMd3Avl 4;
BA_ "SignalLongName" SG_ 563 SPMCA_StrPrfMd3Avl "Steering Performance Mode Customization Available : Steering Performance Mode 3 Available";
BA_ "VNSigAllNodes" SG_ 563 SPMCA_StrPrfMd3Avl 1;
BA_ "SignalType" SG_ 563 SPMCA_StrPrfMd2Avl "BLN";
BA_ "PacketOrder" SG_ 563 SPMCA_StrPrfMd2Avl 3;
BA_ "SignalLongName" SG_ 563 SPMCA_StrPrfMd2Avl "Steering Performance Mode Customization Available : Steering Performance Mode 2 Available";
BA_ "VNSigAllNodes" SG_ 563 SPMCA_StrPrfMd2Avl 1;
BA_ "SignalType" SG_ 563 SPMCA_StrPrfMd1Avl "BLN";
BA_ "PacketOrder" SG_ 563 SPMCA_StrPrfMd1Avl 2;
BA_ "SignalLongName" SG_ 563 SPMCA_StrPrfMd1Avl "Steering Performance Mode Customization Available : Steering Performance Mode 1 Available";
BA_ "VNSigAllNodes" SG_ 563 SPMCA_StrPrfMd1Avl 1;
BA_ "PacketOrder" SG_ 563 SPMCA_SndPrfMd6Avl 1;
BA_ "SignalType" SG_ 563 SPMCA_SndPrfMd6Avl "BLN";
BA_ "SignalLongName" SG_ 563 SPMCA_SndPrfMd6Avl "Sound Performance Mode Customization Available : Sound Performance Mode 6 Available";
BA_ "VNSigAllNodes" SG_ 563 SPMCA_SndPrfMd6Avl 1;
BA_ "SignalType" SG_ 563 SPMCA_SndPrfMd5Avl "BLN";
BA_ "PacketOrder" SG_ 563 SPMCA_SndPrfMd5Avl 6;
BA_ "SignalLongName" SG_ 563 SPMCA_SndPrfMd5Avl "Sound Performance Mode Customization Available : Sound Performance Mode 5 Available";
BA_ "VNSigAllNodes" SG_ 563 SPMCA_SndPrfMd5Avl 1;
BA_ "SignalType" SG_ 563 SPMCA_SndPrfMd4Avl "BLN";
BA_ "PacketOrder" SG_ 563 SPMCA_SndPrfMd4Avl 5;
BA_ "SignalLongName" SG_ 563 SPMCA_SndPrfMd4Avl "Sound Performance Mode Customization Available : Sound Performance Mode 4 Available";
BA_ "VNSigAllNodes" SG_ 563 SPMCA_SndPrfMd4Avl 1;
BA_ "SignalType" SG_ 563 SPMCA_SndPrfMd3Avl "BLN";
BA_ "PacketOrder" SG_ 563 SPMCA_SndPrfMd3Avl 4;
BA_ "SignalLongName" SG_ 563 SPMCA_SndPrfMd3Avl "Sound Performance Mode Customization Available : Sound Performance Mode 3 Available";
BA_ "VNSigAllNodes" SG_ 563 SPMCA_SndPrfMd3Avl 1;
BA_ "SignalType" SG_ 563 SPMCA_SndPrfMd2Avl "BLN";
BA_ "PacketOrder" SG_ 563 SPMCA_SndPrfMd2Avl 3;
BA_ "SignalLongName" SG_ 563 SPMCA_SndPrfMd2Avl "Sound Performance Mode Customization Available : Sound Performance Mode 2 Available";
BA_ "VNSigAllNodes" SG_ 563 SPMCA_SndPrfMd2Avl 1;
BA_ "SignalType" SG_ 563 SPMCA_SndPrfMd1Avl "BLN";
BA_ "PacketOrder" SG_ 563 SPMCA_SndPrfMd1Avl 2;
BA_ "SignalLongName" SG_ 563 SPMCA_SndPrfMd1Avl "Sound Performance Mode Customization Available : Sound Performance Mode 1 Available";
BA_ "VNSigAllNodes" SG_ 563 SPMCA_SndPrfMd1Avl 1;
BA_ "PacketOrder" SG_ 563 DPMCA_DispPrfMd6Avl 1;
BA_ "SignalType" SG_ 563 DPMCA_DispPrfMd6Avl "BLN";
BA_ "SignalLongName" SG_ 563 DPMCA_DispPrfMd6Avl "Display Performance Mode Customization Available : Display Performance Mode 6 Available";
BA_ "VNSigAllNodes" SG_ 563 DPMCA_DispPrfMd6Avl 1;
BA_ "SignalType" SG_ 563 DPMCA_DispPrfMd5Avl "BLN";
BA_ "PacketOrder" SG_ 563 DPMCA_DispPrfMd5Avl 6;
BA_ "SignalLongName" SG_ 563 DPMCA_DispPrfMd5Avl "Display Performance Mode Customization Available : Display Performance Mode 5 Available";
BA_ "VNSigAllNodes" SG_ 563 DPMCA_DispPrfMd5Avl 1;
BA_ "SignalType" SG_ 563 DPMCA_DispPrfMd4Avl "BLN";
BA_ "PacketOrder" SG_ 563 DPMCA_DispPrfMd4Avl 5;
BA_ "SignalLongName" SG_ 563 DPMCA_DispPrfMd4Avl "Display Performance Mode Customization Available : Display Performance Mode 4 Available";
BA_ "VNSigAllNodes" SG_ 563 DPMCA_DispPrfMd4Avl 1;
BA_ "SignalType" SG_ 563 DPMCA_DispPrfMd3Avl "BLN";
BA_ "PacketOrder" SG_ 563 DPMCA_DispPrfMd3Avl 4;
BA_ "SignalLongName" SG_ 563 DPMCA_DispPrfMd3Avl "Display Performance Mode Customization Available : Display Performance Mode 3 Available";
BA_ "VNSigAllNodes" SG_ 563 DPMCA_DispPrfMd3Avl 1;
BA_ "SignalType" SG_ 563 DPMCA_DispPrfMd2Avl "BLN";
BA_ "PacketOrder" SG_ 563 DPMCA_DispPrfMd2Avl 3;
BA_ "SignalLongName" SG_ 563 DPMCA_DispPrfMd2Avl "Display Performance Mode Customization Available : Display Performance Mode 2 Available";
BA_ "VNSigAllNodes" SG_ 563 DPMCA_DispPrfMd2Avl 1;
BA_ "SignalType" SG_ 563 DPMCA_DispPrfMd1Avl "BLN";
BA_ "PacketOrder" SG_ 563 DPMCA_DispPrfMd1Avl 2;
BA_ "SignalLongName" SG_ 563 DPMCA_DispPrfMd1Avl "Display Performance Mode Customization Available : Display Performance Mode 1 Available";
BA_ "VNSigAllNodes" SG_ 563 DPMCA_DispPrfMd1Avl 1;
BA_ "PacketOrder" SG_ 563 DPMCA_DrvlPrfMd6Avl 1;
BA_ "SignalType" SG_ 563 DPMCA_DrvlPrfMd6Avl "BLN";
BA_ "SignalLongName" SG_ 563 DPMCA_DrvlPrfMd6Avl "Driveline Performance Mode Customization Available : Driveline Performance Mode 6 Available";
BA_ "VNSigAllNodes" SG_ 563 DPMCA_DrvlPrfMd6Avl 1;
BA_ "SignalType" SG_ 563 DPMCA_DrvlPrfMd5Avl "BLN";
BA_ "PacketOrder" SG_ 563 DPMCA_DrvlPrfMd5Avl 6;
BA_ "SignalLongName" SG_ 563 DPMCA_DrvlPrfMd5Avl "Driveline Performance Mode Customization Available : Driveline Performance Mode 5 Available";
BA_ "VNSigAllNodes" SG_ 563 DPMCA_DrvlPrfMd5Avl 1;
BA_ "SignalType" SG_ 563 DPMCA_DrvlPrfMd4Avl "BLN";
BA_ "PacketOrder" SG_ 563 DPMCA_DrvlPrfMd4Avl 5;
BA_ "SignalLongName" SG_ 563 DPMCA_DrvlPrfMd4Avl "Driveline Performance Mode Customization Available : Driveline Performance Mode 4 Available";
BA_ "VNSigAllNodes" SG_ 563 DPMCA_DrvlPrfMd4Avl 1;
BA_ "SignalType" SG_ 563 DPMCA_DrvlPrfMd3Avl "BLN";
BA_ "PacketOrder" SG_ 563 DPMCA_DrvlPrfMd3Avl 4;
BA_ "SignalLongName" SG_ 563 DPMCA_DrvlPrfMd3Avl "Driveline Performance Mode Customization Available : Driveline Performance Mode 3 Available";
BA_ "VNSigAllNodes" SG_ 563 DPMCA_DrvlPrfMd3Avl 1;
BA_ "SignalType" SG_ 563 DPMCA_DrvlPrfMd2Avl "BLN";
BA_ "PacketOrder" SG_ 563 DPMCA_DrvlPrfMd2Avl 3;
BA_ "SignalLongName" SG_ 563 DPMCA_DrvlPrfMd2Avl "Driveline Performance Mode Customization Available : Driveline Performance Mode 2 Available";
BA_ "VNSigAllNodes" SG_ 563 DPMCA_DrvlPrfMd2Avl 1;
BA_ "SignalType" SG_ 563 DPMCA_DrvlPrfMd1Avl "BLN";
BA_ "PacketOrder" SG_ 563 DPMCA_DrvlPrfMd1Avl 2;
BA_ "SignalLongName" SG_ 563 DPMCA_DrvlPrfMd1Avl "Driveline Performance Mode Customization Available : Driveline Performance Mode 1 Available";
BA_ "VNSigAllNodes" SG_ 563 DPMCA_DrvlPrfMd1Avl 1;
BA_ "SignalType" SG_ 1323 TireLRTmpV "ENM";
BA_ "SignalLongName" SG_ 1323 TireLRTmpV "Tire Left Rear Temperature Validity";
BA_ "VNSigAllNodes" SG_ 1323 TireLRTmpV 1;
BA_ "SignalType" SG_ 1323 TireLRTmp "UNM";
BA_ "SignalLongName" SG_ 1323 TireLRTmp "Tire Left Rear Temperature";
BA_ "VNSigAllNodes" SG_ 1323 TireLRTmp 1;
BA_ "SignalType" SG_ 1323 TireLFTmpV "ENM";
BA_ "SignalLongName" SG_ 1323 TireLFTmpV "Tire Left Front Temperature Validity";
BA_ "VNSigAllNodes" SG_ 1323 TireLFTmpV 1;
BA_ "SignalType" SG_ 1323 TireLFTmp "UNM";
BA_ "SignalLongName" SG_ 1323 TireLFTmp "Tire Left Front Temperature";
BA_ "VNSigAllNodes" SG_ 1323 TireLFTmp 1;
BA_ "SignalType" SG_ 1323 TireRRTmpV "ENM";
BA_ "SignalLongName" SG_ 1323 TireRRTmpV "Tire Right Rear Temperature Validity";
BA_ "VNSigAllNodes" SG_ 1323 TireRRTmpV 1;
BA_ "SignalType" SG_ 1323 TireRRTmp "UNM";
BA_ "SignalLongName" SG_ 1323 TireRRTmp "Tire Right Rear Temperature";
BA_ "VNSigAllNodes" SG_ 1323 TireRRTmp 1;
BA_ "SignalType" SG_ 1323 TireRFTmpV "ENM";
BA_ "SignalLongName" SG_ 1323 TireRFTmpV "Tire Right Front Temperature Validity";
BA_ "VNSigAllNodes" SG_ 1323 TireRFTmpV 1;
BA_ "SignalType" SG_ 1323 TireRFTmp "UNM";
BA_ "SignalLongName" SG_ 1323 TireRFTmp "Tire Right Front Temperature";
BA_ "VNSigAllNodes" SG_ 1323 TireRFTmp 1;
BA_ "SignalType" SG_ 1247 RrPTCoolFanStatV "ENM";
BA_ "SignalLongName" SG_ 1247 RrPTCoolFanStatV "Rear Powertrain Cooling Fan Status Validity";
BA_ "VNSigAllNodes" SG_ 1247 RrPTCoolFanStatV 1;
BA_ "SignalType" SG_ 1247 RrPTCoolFanStat "ENM";
BA_ "SignalLongName" SG_ 1247 RrPTCoolFanStat "Rear Powertrain Cooling Fan Status";
BA_ "VNSigAllNodes" SG_ 1247 RrPTCoolFanStat 1;
BA_ "SignalType" SG_ 1247 RrPTCoolFanSpPctCmd "UNM";
BA_ "SignalLongName" SG_ 1247 RrPTCoolFanSpPctCmd "Rear Powertrain Cooling Fan Speed Percent Commanded";
BA_ "VNSigAllNodes" SG_ 1247 RrPTCoolFanSpPctCmd 1;
BA_ "SignalType" SG_ 873 FrtCmModIntgStat "ENM";
BA_ "SignalLongName" SG_ 873 FrtCmModIntgStat "Front Camera Module Integrity Status";
BA_ "VNSigAllNodes" SG_ 873 FrtCmModIntgStat 1;
BA_ "SignalType" SG_ 873 FrtCmModAsmt "ENM";
BA_ "SignalLongName" SG_ 873 FrtCmModAsmt "Front Camera Module Assessment";
BA_ "VNSigAllNodes" SG_ 873 FrtCmModAsmt 1;
BA_ "SignalType" SG_ 873 ACCMR_RptdChlng "UNM";
BA_ "PacketOrder" SG_ 873 ACCMR_RptdChlng 1;
BA_ "SignalLongName" SG_ 873 ACCMR_RptdChlng "Adaptive Cruise Control Module Response : Repeated Challenge";
BA_ "VNSigAllNodes" SG_ 873 ACCMR_RptdChlng 1;
BA_ "PacketOrder" SG_ 873 ACCMR_Answr 2;
BA_ "SignalType" SG_ 873 ACCMR_Answr "UNM";
BA_ "SignalLongName" SG_ 873 ACCMR_Answr "Adaptive Cruise Control Module Response : Answer";
BA_ "VNSigAllNodes" SG_ 873 ACCMR_Answr 1;
BA_ "SignalType" SG_ 873 AdptCrsCtrlModChlng "UNM";
BA_ "SignalLongName" SG_ 873 AdptCrsCtrlModChlng "Adaptive Cruise Control Module Challenge";
BA_ "VNSigAllNodes" SG_ 873 AdptCrsCtrlModChlng 1;
BA_ "SignalType" SG_ 306 ClntCrcFlwRtEst "UNM";
BA_ "SignalLongName" SG_ 306 ClntCrcFlwRtEst "Coolant Circulation Flow Rate Estimated";
BA_ "VNSigAllNodes" SG_ 306 ClntCrcFlwRtEst 1;
BA_ "SignalType" SG_ 723 PerfTrcEngSpdRqStat "ENM";
BA_ "SignalLongName" SG_ 723 PerfTrcEngSpdRqStat "Performance Traction Engine Speed Request Status";
BA_ "VNSigAllNodes" SG_ 723 PerfTrcEngSpdRqStat 1;
BA_ "SignalType" SG_ 723 PerfTrcEngSpdLmtStat "ENM";
BA_ "SignalLongName" SG_ 723 PerfTrcEngSpdLmtStat "Performance Traction Engine Speed Limiting Status";
BA_ "VNSigAllNodes" SG_ 723 PerfTrcEngSpdLmtStat 1;
BA_ "SignalType" SG_ 723 PerfTrcTrqRqStat "ENM";
BA_ "SignalLongName" SG_ 723 PerfTrcTrqRqStat "Performance Traction Torque Request Status";
BA_ "VNSigAllNodes" SG_ 723 PerfTrcTrqRqStat 1;
BA_ "SignalType" SG_ 723 PerfTrcTrqLmtStat "ENM";
BA_ "SignalLongName" SG_ 723 PerfTrcTrqLmtStat "Performance Traction Torque Limiting Status";
BA_ "VNSigAllNodes" SG_ 723 PerfTrcTrqLmtStat 1;
BA_ "SignalType" SG_ 405 EngDistFuelMdDefltd "BLN";
BA_ "SignalLongName" SG_ 405 EngDistFuelMdDefltd "Engine Distributed Fuel Mode Defaulted";
BA_ "VNSigAllNodes" SG_ 405 EngDistFuelMdDefltd 1;
BA_ "SignalType" SG_ 405 EngInjEnbldD "BLN";
BA_ "SignalLongName" SG_ 405 EngInjEnbldD "Engine Injector Enabled D";
BA_ "VNSigAllNodes" SG_ 405 EngInjEnbldD 1;
BA_ "SignalType" SG_ 405 EngInjEnbldC "BLN";
BA_ "SignalLongName" SG_ 405 EngInjEnbldC "Engine Injector Enabled C";
BA_ "VNSigAllNodes" SG_ 405 EngInjEnbldC 1;
BA_ "SignalType" SG_ 405 EngInjEnbldB "BLN";
BA_ "SignalLongName" SG_ 405 EngInjEnbldB "Engine Injector Enabled B";
BA_ "VNSigAllNodes" SG_ 405 EngInjEnbldB 1;
BA_ "SignalType" SG_ 405 EngInjEnbldA "BLN";
BA_ "SignalLongName" SG_ 405 EngInjEnbldA "Engine Injector Enabled A";
BA_ "VNSigAllNodes" SG_ 405 EngInjEnbldA 1;
BA_ "SignalType" SG_ 405 ThrPosV "ENM";
BA_ "SignalLongName" SG_ 405 ThrPosV "Throttle Position Validity";
BA_ "VNSigAllNodes" SG_ 405 ThrPosV 1;
BA_ "SignalType" SG_ 405 ThrPos "UNM";
BA_ "SignalLongName" SG_ 405 ThrPos "Throttle Position";
BA_ "VNSigAllNodes" SG_ 405 ThrPos 1;
BA_ "SignalType" SG_ 405 MassAirFloV "ENM";
BA_ "SignalLongName" SG_ 405 MassAirFloV "Mass Air Flow Validity";
BA_ "VNSigAllNodes" SG_ 405 MassAirFloV 1;
BA_ "SignalType" SG_ 405 MassAirFlo "UNM";
BA_ "SignalLongName" SG_ 405 MassAirFlo "Mass Air Flow";
BA_ "VNSigAllNodes" SG_ 405 MassAirFlo 1;
BA_ "SignalType" SG_ 405 EngManfldAbsPrsERV "ENM";
BA_ "SignalLongName" SG_ 405 EngManfldAbsPrsERV "Engine Manifold Absolute Pressure Extended Range Validity";
BA_ "VNSigAllNodes" SG_ 405 EngManfldAbsPrsERV 1;
BA_ "SignalType" SG_ 405 EngManfldAbsPrsER "UNM";
BA_ "SignalLongName" SG_ 405 EngManfldAbsPrsER "Engine Manifold Absolute Pressure Extended Range";
BA_ "VNSigAllNodes" SG_ 405 EngManfldAbsPrsER 1;
BA_ "SignalType" SG_ 419 EngRunng "BLN";
BA_ "SignalLongName" SG_ 419 EngRunng "Engine Running";
BA_ "VNSigAllNodes" SG_ 419 EngRunng 1;
BA_ "SignalType" SG_ 289 ARDM_RawData "UNM";
BA_ "PacketOrder" SG_ 289 ARDM_RawData 1;
BA_ "SignalLongName" SG_ 289 ARDM_RawData "ADASIS Raw Data Multiplexed : Raw Data";
BA_ "VNSigAllNodes" SG_ 289 ARDM_RawData 1;
BA_ "SignalType" SG_ 289 ARDM_MsgType "ENM";
BA_ "PacketOrder" SG_ 289 ARDM_MsgType 1;
BA_ "SignalLongName" SG_ 289 ARDM_MsgType "ADASIS Raw Data Multiplexed : Message Type";
BA_ "VNSigAllNodes" SG_ 289 ARDM_MsgType 1;
BA_ "SignalType" SG_ 871 ACCModIntgStat "ENM";
BA_ "SignalLongName" SG_ 871 ACCModIntgStat "Adaptive Cruise Control Module Integrity Status";
BA_ "VNSigAllNodes" SG_ 871 ACCModIntgStat 1;
BA_ "SignalType" SG_ 871 AdptCrsCtrlModAsmt "ENM";
BA_ "SignalLongName" SG_ 871 AdptCrsCtrlModAsmt "Adaptive Cruise Control Module Assessment";
BA_ "VNSigAllNodes" SG_ 871 AdptCrsCtrlModAsmt 1;
BA_ "PacketOrder" SG_ 871 FCMR_RptdChlng 1;
BA_ "SignalType" SG_ 871 FCMR_RptdChlng "UNM";
BA_ "SignalLongName" SG_ 871 FCMR_RptdChlng "Front Camera Module Response : Repeated Challenge";
BA_ "VNSigAllNodes" SG_ 871 FCMR_RptdChlng 1;
BA_ "SignalType" SG_ 871 FCMR_Answr "UNM";
BA_ "PacketOrder" SG_ 871 FCMR_Answr 2;
BA_ "SignalLongName" SG_ 871 FCMR_Answr "Front Camera Module Response : Answer";
BA_ "VNSigAllNodes" SG_ 871 FCMR_Answr 1;
BA_ "SignalType" SG_ 871 FrtCmModChlng "UNM";
BA_ "SignalLongName" SG_ 871 FrtCmModChlng "Front Camera Module Challenge";
BA_ "VNSigAllNodes" SG_ 871 FrtCmModChlng 1;
BA_ "SignalType" SG_ 800 FCACtrlBrkSysCmdPrtVl "UNM";
BA_ "SignalLongName" SG_ 800 FCACtrlBrkSysCmdPrtVl "Forward Collision Alert Control Brake System Command Protection Value";
BA_ "VNSigAllNodes" SG_ 800 FCACtrlBrkSysCmdPrtVl 1;
BA_ "PacketOrder" SG_ 800 FCACBSC_CtrlAcc 2;
BA_ "SignalType" SG_ 800 FCACBSC_CtrlAcc "SNM";
BA_ "SignalLongName" SG_ 800 FCACBSC_CtrlAcc "Forward Collision Alert Control Brake System Command : Control Acceleration";
BA_ "VNSigAllNodes" SG_ 800 FCACBSC_CtrlAcc 1;
BA_ "SignalType" SG_ 800 FCACBSC_AutBrkRpRt "ENM";
BA_ "PacketOrder" SG_ 800 FCACBSC_AutBrkRpRt 4;
BA_ "SignalLongName" SG_ 800 FCACBSC_AutBrkRpRt "Forward Collision Alert Control Brake System Command : Automatic Braking Ramp Rate";
BA_ "VNSigAllNodes" SG_ 800 FCACBSC_AutBrkRpRt 1;
BA_ "PacketOrder" SG_ 800 FCACBSC_AutBrkRqTp 2;
BA_ "SignalType" SG_ 800 FCACBSC_AutBrkRqTp "ENM";
BA_ "SignalLongName" SG_ 800 FCACBSC_AutBrkRqTp "Forward Collision Alert Control Brake System Command : Automatic Braking Request Type";
BA_ "VNSigAllNodes" SG_ 800 FCACBSC_AutBrkRqTp 1;
BA_ "SignalType" SG_ 800 FCACBSC_AutBrkRqd "BLN";
BA_ "PacketOrder" SG_ 800 FCACBSC_AutBrkRqd 3;
BA_ "SignalLongName" SG_ 800 FCACBSC_AutBrkRqd "Forward Collision Alert Control Brake System Command : Automatic Braking Requested";
BA_ "VNSigAllNodes" SG_ 800 FCACBSC_AutBrkRqd 1;
BA_ "SignalType" SG_ 800 FCACtrlBrkSysCmdRC "UNM";
BA_ "SignalLongName" SG_ 800 FCACtrlBrkSysCmdRC "Forward Collision Alert Control Brake System Command Rolling Count";
BA_ "VNSigAllNodes" SG_ 800 FCACtrlBrkSysCmdRC 1;
BA_ "SignalType" SG_ 388 HndsOffStrWhlDtStV "ENM";
BA_ "SignalLongName" SG_ 388 HndsOffStrWhlDtStV "Hands Off Steering Wheel Detection State Validity";
BA_ "VNSigAllNodes" SG_ 388 HndsOffStrWhlDtStV 1;
BA_ "SignalType" SG_ 388 HndsOffStrWhlDtSt "ENM";
BA_ "SignalLongName" SG_ 388 HndsOffStrWhlDtSt "Hands Off Steering Wheel Detection State";
BA_ "VNSigAllNodes" SG_ 388 HndsOffStrWhlDtSt 1;
BA_ "SignalType" SG_ 388 HndsOffStrWhlDtMd "ENM";
BA_ "SignalLongName" SG_ 388 HndsOffStrWhlDtMd "Hands Off Steering Wheel Detection Mode";
BA_ "VNSigAllNodes" SG_ 388 HndsOffStrWhlDtMd 1;
BA_ "SignalType" SG_ 388 LKATrqOvrlDlvdPrtVl "UNM";
BA_ "SignalLongName" SG_ 388 LKATrqOvrlDlvdPrtVl "Lane Keeping Assist Torque Overlay Delivered Protection Value";
BA_ "VNSigAllNodes" SG_ 388 LKATrqOvrlDlvdPrtVl 1;
BA_ "SignalType" SG_ 388 LKATrqOvrlDltTrqDlvd "SNM";
BA_ "SignalLongName" SG_ 388 LKATrqOvrlDltTrqDlvd "Lane Keeping Assist Torque Overlay Delta Torque Delivered";
BA_ "VNSigAllNodes" SG_ 388 LKATrqOvrlDltTrqDlvd 1;
BA_ "SignalType" SG_ 388 LKATrqOvrlDlvdRC "UNM";
BA_ "SignalLongName" SG_ 388 LKATrqOvrlDlvdRC "Lane Keeping Assist Torque Overlay Delivered Rolling Count";
BA_ "VNSigAllNodes" SG_ 388 LKATrqOvrlDlvdRC 1;
BA_ "SignalType" SG_ 388 LKAElPwrStTtlTqDlvd "SNM";
BA_ "SignalLongName" SG_ 388 LKAElPwrStTtlTqDlvd "Lane Keeping Assist Electrical Power Steering Total Torque Delivered";
BA_ "VNSigAllNodes" SG_ 388 LKAElPwrStTtlTqDlvd 1;
BA_ "SignalType" SG_ 388 LKATrqOvrlTrqDStat "ENM";
BA_ "SignalLongName" SG_ 388 LKATrqOvrlTrqDStat "Lane Keeping Assist Torque Overlay Torque Delivered Status";
BA_ "VNSigAllNodes" SG_ 388 LKATrqOvrlTrqDStat 1;
BA_ "SignalType" SG_ 384 LKATqOvrDltCmdPrtVl "UNM";
BA_ "SignalLongName" SG_ 384 LKATqOvrDltCmdPrtVl "Lane Keeping Assist Torque Overlay Delta Command Protection Value";
BA_ "VNSigAllNodes" SG_ 384 LKATqOvrDltCmdPrtVl 1;
BA_ "SignalType" SG_ 384 LKATqOvrDltCmdRC "UNM";
BA_ "SignalLongName" SG_ 384 LKATqOvrDltCmdRC "Lane Keeping Assist Torque Overlay Delta Command Rolling Count";
BA_ "VNSigAllNodes" SG_ 384 LKATqOvrDltCmdRC 1;
BA_ "SignalType" SG_ 384 LKATODC_TrqVl "SNM";
BA_ "PacketOrder" SG_ 384 LKATODC_TrqVl 1;
BA_ "SignalLongName" SG_ 384 LKATODC_TrqVl "Lane Keeping Assist Torque Overlay Delta Command : Torque Value";
BA_ "VNSigAllNodes" SG_ 384 LKATODC_TrqVl 1;
BA_ "PacketOrder" SG_ 384 LKATODC_TrqRqAct 2;
BA_ "SignalType" SG_ 384 LKATODC_TrqRqAct "BLN";
BA_ "SignalLongName" SG_ 384 LKATODC_TrqRqAct "Lane Keeping Assist Torque Overlay Delta Command : Torque Request Active";
BA_ "VNSigAllNodes" SG_ 384 LKATODC_TrqRqAct 1;
BA_ "SignalType" SG_ 866 ColPrSysHzrdLghtsReq "ENM";
BA_ "SignalLongName" SG_ 866 ColPrSysHzrdLghtsReq "Collision Preparation System Hazard Lights Request";
BA_ "VNSigAllNodes" SG_ 866 ColPrSysHzrdLghtsReq 1;
BA_ "SignalType" SG_ 866 ColPrSysWndwsReq "ENM";
BA_ "SignalLongName" SG_ 866 ColPrSysWndwsReq "Collision Preparation System Windows Request";
BA_ "VNSigAllNodes" SG_ 866 ColPrSysWndwsReq 1;
BA_ "SignalType" SG_ 866 ColPrSysDrsReq "ENM";
BA_ "SignalLongName" SG_ 866 ColPrSysDrsReq "Collision Preparation System Doors Request";
BA_ "VNSigAllNodes" SG_ 866 ColPrSysDrsReq 1;
BA_ "SignalType" SG_ 866 ColPrSysSnrfReq "ENM";
BA_ "SignalLongName" SG_ 866 ColPrSysSnrfReq "Collision Preparation System Sunroof Request";
BA_ "VNSigAllNodes" SG_ 866 ColPrSysSnrfReq 1;
BA_ "SignalType" SG_ 866 CPSInfotmntMtReq "ENM";
BA_ "SignalLongName" SG_ 866 CPSInfotmntMtReq "Collision Preparation System Infotainment Mute Request";
BA_ "VNSigAllNodes" SG_ 866 CPSInfotmntMtReq 1;
BA_ "SignalType" SG_ 866 StBltTgtSetAvl "BLN";
BA_ "SignalLongName" SG_ 866 StBltTgtSetAvl "Seat Belt Tightening Settings Available";
BA_ "VNSigAllNodes" SG_ 866 StBltTgtSetAvl 1;
BA_ "SignalType" SG_ 866 StBltTgtCrtSetVal "ENM";
BA_ "SignalLongName" SG_ 866 StBltTgtCrtSetVal "Seat Belt Tightening Current Setting Value";
BA_ "VNSigAllNodes" SG_ 866 StBltTgtCrtSetVal 1;
BA_ "SignalType" SG_ 866 MotStBltUnblIO "BLN";
BA_ "SignalLongName" SG_ 866 MotStBltUnblIO "Motorized Seat Belt Unavailable Indication On";
BA_ "VNSigAllNodes" SG_ 866 MotStBltUnblIO 1;
BA_ "SignalType" SG_ 866 MotStBltFldIO "BLN";
BA_ "SignalLongName" SG_ 866 MotStBltFldIO "Motorized Seat Belt Failed Indication On";
BA_ "VNSigAllNodes" SG_ 866 MotStBltFldIO 1;
BA_ "SignalType" SG_ 866 RegenBrkAxTrqAch "UNM";
BA_ "SignalLongName" SG_ 866 RegenBrkAxTrqAch "Regenerative Braking Axle Torque Achieved";
BA_ "VNSigAllNodes" SG_ 866 RegenBrkAxTrqAch 1;
BA_ "SignalType" SG_ 951 AltFuelLvlPrcnt "UNM";
BA_ "SignalLongName" SG_ 951 AltFuelLvlPrcnt "Alternative Fuel Level Percent";
BA_ "VNSigAllNodes" SG_ 951 AltFuelLvlPrcnt 1;
BA_ "SignalType" SG_ 951 FuelInjCntrlModInjFltAct "BLN";
BA_ "SignalLongName" SG_ 951 FuelInjCntrlModInjFltAct "Fuel Injector Control Module Injection Fault Active";
BA_ "VNSigAllNodes" SG_ 951 FuelInjCntrlModInjFltAct 1;
BA_ "SignalType" SG_ 951 AFRP_RailPrs "UNM";
BA_ "PacketOrder" SG_ 951 AFRP_RailPrs 2;
BA_ "SignalLongName" SG_ 951 AFRP_RailPrs "Alternative Fuel Rail Pressure : Rail Pressure";
BA_ "VNSigAllNodes" SG_ 951 AFRP_RailPrs 1;
BA_ "SignalType" SG_ 951 AFRP_SnsTyp "ENM";
BA_ "PacketOrder" SG_ 951 AFRP_SnsTyp 1;
BA_ "SignalLongName" SG_ 951 AFRP_SnsTyp "Alternative Fuel Rail Pressure : Sensor Type";
BA_ "VNSigAllNodes" SG_ 951 AFRP_SnsTyp 1;
BA_ "SignalType" SG_ 951 FICMDS3_DTCStatus "ENM";
BA_ "PacketOrder" SG_ 951 FICMDS3_DTCStatus 2;
BA_ "SignalLongName" SG_ 951 FICMDS3_DTCStatus "Fuel Injector Control Module Diagnostic Status 3 : Diagnostic Trouble Code Status";
BA_ "VNSigAllNodes" SG_ 951 FICMDS3_DTCStatus 1;
BA_ "SignalType" SG_ 951 FICMDS3_DTCIndx "UNM";
BA_ "PacketOrder" SG_ 951 FICMDS3_DTCIndx 1;
BA_ "SignalLongName" SG_ 951 FICMDS3_DTCIndx "Fuel Injector Control Module Diagnostic Status 3 : Diagnostic Trouble Code Index";
BA_ "VNSigAllNodes" SG_ 951 FICMDS3_DTCIndx 1;
BA_ "SignalType" SG_ 951 FICMDS2_DTCStatus "ENM";
BA_ "PacketOrder" SG_ 951 FICMDS2_DTCStatus 2;
BA_ "SignalLongName" SG_ 951 FICMDS2_DTCStatus "Fuel Injector Control Module Diagnostic Status 2 : Diagnostic Trouble Code Status";
BA_ "VNSigAllNodes" SG_ 951 FICMDS2_DTCStatus 1;
BA_ "SignalType" SG_ 951 FICMDS2_DTCIndx "UNM";
BA_ "PacketOrder" SG_ 951 FICMDS2_DTCIndx 1;
BA_ "SignalLongName" SG_ 951 FICMDS2_DTCIndx "Fuel Injector Control Module Diagnostic Status 2 : Diagnostic Trouble Code Index";
BA_ "VNSigAllNodes" SG_ 951 FICMDS2_DTCIndx 1;
BA_ "SignalType" SG_ 951 FICMDS1_DTCStatus "ENM";
BA_ "PacketOrder" SG_ 951 FICMDS1_DTCStatus 2;
BA_ "SignalLongName" SG_ 951 FICMDS1_DTCStatus "Fuel Injector Control Module Diagnostic Status 1 : Diagnostic Trouble Code Status";
BA_ "VNSigAllNodes" SG_ 951 FICMDS1_DTCStatus 1;
BA_ "SignalType" SG_ 951 FICMDS1_DTCIndx "UNM";
BA_ "PacketOrder" SG_ 951 FICMDS1_DTCIndx 1;
BA_ "SignalLongName" SG_ 951 FICMDS1_DTCIndx "Fuel Injector Control Module Diagnostic Status 1 : Diagnostic Trouble Code Index";
BA_ "VNSigAllNodes" SG_ 951 FICMDS1_DTCIndx 1;
BA_ "SignalType" SG_ 949 AltFuelRFuelTrmLmtOff "SNM";
BA_ "SignalLongName" SG_ 949 AltFuelRFuelTrmLmtOff "Alternative Fuel Rich Fuel Trim Limit Offset";
BA_ "VNSigAllNodes" SG_ 949 AltFuelRFuelTrmLmtOff 1;
BA_ "SignalType" SG_ 949 AltFuelLnFuelTrmLmtOff "SNM";
BA_ "SignalLongName" SG_ 949 AltFuelLnFuelTrmLmtOff "Alternative Fuel Lean Fuel Trim Limit Offset";
BA_ "VNSigAllNodes" SG_ 949 AltFuelLnFuelTrmLmtOff 1;
BA_ "SignalType" SG_ 949 AltFuelInjMinPlsOffst "SNM";
BA_ "SignalLongName" SG_ 949 AltFuelInjMinPlsOffst "Alternative Fuel Injector Min Pulse Offset";
BA_ "VNSigAllNodes" SG_ 949 AltFuelInjMinPlsOffst 1;
BA_ "SignalType" SG_ 949 AltFuelInjOpnOffst "SNM";
BA_ "SignalLongName" SG_ 949 AltFuelInjOpnOffst "Alternative Fuel Injector Opening Offset";
BA_ "VNSigAllNodes" SG_ 949 AltFuelInjOpnOffst 1;
BA_ "SignalType" SG_ 949 AltFuelInjFlwOffst "SNM";
BA_ "SignalLongName" SG_ 949 AltFuelInjFlwOffst "Alternative Fuel Injector Flow Offset";
BA_ "VNSigAllNodes" SG_ 949 AltFuelInjFlwOffst 1;
BA_ "SignalType" SG_ 949 AltFuelEqvlntRatBsOffst "SNM";
BA_ "SignalLongName" SG_ 949 AltFuelEqvlntRatBsOffst "Alternative Fuel Equivalence Ratio Bias Offset";
BA_ "VNSigAllNodes" SG_ 949 AltFuelEqvlntRatBsOffst 1;
BA_ "SignalType" SG_ 949 AltFuelPst02BsOffst "SNM";
BA_ "SignalLongName" SG_ 949 AltFuelPst02BsOffst "Alternative Fuel Post O2 Bias Offset";
BA_ "VNSigAllNodes" SG_ 949 AltFuelPst02BsOffst 1;
BA_ "SignalType" SG_ 1223 EngSnPwrECoolLpTmpV "ENM";
BA_ "SignalLongName" SG_ 1223 EngSnPwrECoolLpTmpV "Engine Sensed Power Electronics Cooling Loop Temperature Validity";
BA_ "VNSigAllNodes" SG_ 1223 EngSnPwrECoolLpTmpV 1;
BA_ "SignalType" SG_ 1223 EngSnPwrECoolLpTmp "UNM";
BA_ "SignalLongName" SG_ 1223 EngSnPwrECoolLpTmp "Engine Sensed Power Electronics Cooling Loop Temperature";
BA_ "VNSigAllNodes" SG_ 1223 EngSnPwrECoolLpTmp 1;
BA_ "SignalType" SG_ 1223 PropSysOffTmeV "ENM";
BA_ "SignalLongName" SG_ 1223 PropSysOffTmeV "Propulsion System Off Time Validity";
BA_ "VNSigAllNodes" SG_ 1223 PropSysOffTmeV 1;
BA_ "SignalType" SG_ 1223 PropSysOffTmeM "ENM";
BA_ "SignalLongName" SG_ 1223 PropSysOffTmeM "Propulsion System Off Time Mask";
BA_ "VNSigAllNodes" SG_ 1223 PropSysOffTmeM 1;
BA_ "SignalType" SG_ 1223 PropSysOffTme "UNM";
BA_ "SignalLongName" SG_ 1223 PropSysOffTme "Propulsion System Off Time";
BA_ "VNSigAllNodes" SG_ 1223 PropSysOffTme 1;
BA_ "SignalType" SG_ 1227 BattThrmlCondOffTmeV "ENM";
BA_ "SignalLongName" SG_ 1227 BattThrmlCondOffTmeV "Battery Thermal Conditioning Off Time Validity";
BA_ "VNSigAllNodes" SG_ 1227 BattThrmlCondOffTmeV 1;
BA_ "SignalType" SG_ 1227 BattThrmlCondOffTmeM "ENM";
BA_ "SignalLongName" SG_ 1227 BattThrmlCondOffTmeM "Battery Thermal Conditioning Off Time Mask";
BA_ "VNSigAllNodes" SG_ 1227 BattThrmlCondOffTmeM 1;
BA_ "SignalType" SG_ 1227 BattThrmlCondOffTme "UNM";
BA_ "SignalLongName" SG_ 1227 BattThrmlCondOffTme "Battery Thermal Conditioning Off Time";
BA_ "VNSigAllNodes" SG_ 1227 BattThrmlCondOffTme 1;
BA_ "SignalType" SG_ 1227 OffBrdChrgOffTmeV "ENM";
BA_ "SignalLongName" SG_ 1227 OffBrdChrgOffTmeV "Off Board Charging Off Time Validity";
BA_ "VNSigAllNodes" SG_ 1227 OffBrdChrgOffTmeV 1;
BA_ "SignalType" SG_ 1227 OffBrdChrgOffTmeM "ENM";
BA_ "SignalLongName" SG_ 1227 OffBrdChrgOffTmeM "Off Board Charging Off Time Mask";
BA_ "VNSigAllNodes" SG_ 1227 OffBrdChrgOffTmeM 1;
BA_ "SignalType" SG_ 1227 OffBrdChrgOffTme "UNM";
BA_ "SignalLongName" SG_ 1227 OffBrdChrgOffTme "Off Board Charging Off Time";
BA_ "VNSigAllNodes" SG_ 1227 OffBrdChrgOffTme 1;
BA_ "SignalType" SG_ 543 PTOTpStpSpdCsStReq "ENM";
BA_ "SignalLongName" SG_ 543 PTOTpStpSpdCsStReq "Power Take Off Tap Step Speed Customization Setting Request";
BA_ "VNSigAllNodes" SG_ 543 PTOTpStpSpdCsStReq 1;
BA_ "SignalType" SG_ 543 PTOStdbySpdCsStReq "ENM";
BA_ "SignalLongName" SG_ 543 PTOStdbySpdCsStReq "Power Take Off Standby Speed Customization Setting Request";
BA_ "VNSigAllNodes" SG_ 543 PTOStdbySpdCsStReq 1;
BA_ "SignalType" SG_ 543 PTOEngRnTmrCsStRq "ENM";
BA_ "SignalLongName" SG_ 543 PTOEngRnTmrCsStRq "Power Take Off Engine Run Timer Customization Setting Request";
BA_ "VNSigAllNodes" SG_ 543 PTOEngRnTmrCsStRq 1;
BA_ "SignalType" SG_ 543 PTOSet2SpdCsStReq "ENM";
BA_ "SignalLongName" SG_ 543 PTOSet2SpdCsStReq "Power Take Off Set 2 Speed Customization Setting Request";
BA_ "VNSigAllNodes" SG_ 543 PTOSet2SpdCsStReq 1;
BA_ "SignalType" SG_ 543 PTOSet1SpdCsStReq "ENM";
BA_ "SignalLongName" SG_ 543 PTOSet1SpdCsStReq "Power Take Off Set 1 Speed Customization Setting Request";
BA_ "VNSigAllNodes" SG_ 543 PTOSet1SpdCsStReq 1;
BA_ "SignalType" SG_ 544 PTOAudExtAlertReq "BLN";
BA_ "SignalLongName" SG_ 544 PTOAudExtAlertReq "Power Take Off Audible External Alert Request";
BA_ "VNSigAllNodes" SG_ 544 PTOAudExtAlertReq 1;
BA_ "SignalType" SG_ 544 PTOTransInGearIO "BLN";
BA_ "SignalLongName" SG_ 544 PTOTransInGearIO "Power Take Off Transmission In Gear Indication On";
BA_ "VNSigAllNodes" SG_ 544 PTOTransInGearIO 1;
BA_ "SignalType" SG_ 544 PTOTpStpSpdCsStAvl "BLN";
BA_ "SignalLongName" SG_ 544 PTOTpStpSpdCsStAvl "Power Take Off Tap Step Speed Customization Setting Available";
BA_ "VNSigAllNodes" SG_ 544 PTOTpStpSpdCsStAvl 1;
BA_ "SignalType" SG_ 544 PTOTpStSpdCsCrStVal "ENM";
BA_ "SignalLongName" SG_ 544 PTOTpStSpdCsCrStVal "Power Take Off Tap Step Speed Customization Current Setting Value";
BA_ "VNSigAllNodes" SG_ 544 PTOTpStSpdCsCrStVal 1;
BA_ "SignalType" SG_ 544 PTOStdbySpdCsStAvl "BLN";
BA_ "SignalLongName" SG_ 544 PTOStdbySpdCsStAvl "Power Take Off Standby Speed Customization Setting Available";
BA_ "VNSigAllNodes" SG_ 544 PTOStdbySpdCsStAvl 1;
BA_ "SignalType" SG_ 544 PTOStdbSpdCsCrStVal "ENM";
BA_ "SignalLongName" SG_ 544 PTOStdbSpdCsCrStVal "Power Take Off Standby Speed Customization Current Setting Value";
BA_ "VNSigAllNodes" SG_ 544 PTOStdbSpdCsCrStVal 1;
BA_ "SignalType" SG_ 544 PTOSetPrkBrkIO "BLN";
BA_ "SignalLongName" SG_ 544 PTOSetPrkBrkIO "Power Take Off Set Park Brake Indication On";
BA_ "VNSigAllNodes" SG_ 544 PTOSetPrkBrkIO 1;
BA_ "SignalType" SG_ 544 PTOSet2SpdCsStAvl "BLN";
BA_ "SignalLongName" SG_ 544 PTOSet2SpdCsStAvl "Power Take Off Set 2 Speed Customization Setting Available";
BA_ "VNSigAllNodes" SG_ 544 PTOSet2SpdCsStAvl 1;
BA_ "SignalType" SG_ 544 PTOSet2SpdCsCrStVal "ENM";
BA_ "SignalLongName" SG_ 544 PTOSet2SpdCsCrStVal "Power Take Off Set 2 Speed Customization Current Setting Value";
BA_ "VNSigAllNodes" SG_ 544 PTOSet2SpdCsCrStVal 1;
BA_ "SignalType" SG_ 544 PTOSet1SpdCsStAvl "BLN";
BA_ "SignalLongName" SG_ 544 PTOSet1SpdCsStAvl "Power Take Off Set 1 Speed Customization Setting Available";
BA_ "VNSigAllNodes" SG_ 544 PTOSet1SpdCsStAvl 1;
BA_ "SignalType" SG_ 544 PTOSet1SpdCsCrStVal "ENM";
BA_ "SignalLongName" SG_ 544 PTOSet1SpdCsCrStVal "Power Take Off Set 1 Speed Customization Current Setting Value";
BA_ "VNSigAllNodes" SG_ 544 PTOSet1SpdCsCrStVal 1;
BA_ "SignalType" SG_ 544 PTORelCltPedIO "BLN";
BA_ "SignalLongName" SG_ 544 PTORelCltPedIO "Power Take Off Release Clutch Pedal Indication On";
BA_ "VNSigAllNodes" SG_ 544 PTORelCltPedIO 1;
BA_ "SignalType" SG_ 544 PTORelBrkPedIO "BLN";
BA_ "SignalLongName" SG_ 544 PTORelBrkPedIO "Power Take Off Release Brake Pedal Indication On";
BA_ "VNSigAllNodes" SG_ 544 PTORelBrkPedIO 1;
BA_ "SignalType" SG_ 544 PTORelAccPedIO "BLN";
BA_ "SignalLongName" SG_ 544 PTORelAccPedIO "Power Take Off Release Accelerator Pedal Indication On";
BA_ "VNSigAllNodes" SG_ 544 PTORelAccPedIO 1;
BA_ "SignalType" SG_ 544 PTORedEngSpdIO "BLN";
BA_ "SignalLongName" SG_ 544 PTORedEngSpdIO "Power Take Off Reduce Engine Speed Indication On";
BA_ "VNSigAllNodes" SG_ 544 PTORedEngSpdIO 1;
BA_ "SignalType" SG_ 544 PTOPrsRelCltPedIO "BLN";
BA_ "SignalLongName" SG_ 544 PTOPrsRelCltPedIO "Power Take Off Press and Release Clutch Pedal Indication On";
BA_ "VNSigAllNodes" SG_ 544 PTOPrsRelCltPedIO 1;
BA_ "SignalType" SG_ 544 PTOPrsRelBrkPedIO "BLN";
BA_ "SignalLongName" SG_ 544 PTOPrsRelBrkPedIO "Power Take Off Press and Release Brake Pedal Indication On";
BA_ "VNSigAllNodes" SG_ 544 PTOPrsRelBrkPedIO 1;
BA_ "SignalType" SG_ 544 PTOEngRnTmrCsStAvl "BLN";
BA_ "SignalLongName" SG_ 544 PTOEngRnTmrCsStAvl "Power Take Off Engine Run Timer Customization Setting Available";
BA_ "VNSigAllNodes" SG_ 544 PTOEngRnTmrCsStAvl 1;
BA_ "SignalType" SG_ 544 PTOEnRnTmCsCrStVal "ENM";
BA_ "SignalLongName" SG_ 544 PTOEnRnTmCsCrStVal "Power Take Off Engine Run Timer Customization Current Setting Value";
BA_ "VNSigAllNodes" SG_ 544 PTOEnRnTmCsCrStVal 1;
BA_ "SignalType" SG_ 544 PTOEngmntStatInd "ENM";
BA_ "SignalLongName" SG_ 544 PTOEngmntStatInd "Power Take Off Engagement Status Indication";
BA_ "VNSigAllNodes" SG_ 544 PTOEngmntStatInd 1;
BA_ "SignalType" SG_ 544 PTODisengCrsCntlIO "BLN";
BA_ "SignalLongName" SG_ 544 PTODisengCrsCntlIO "Power Take Off Disengage Cruise Control Indication On";
BA_ "VNSigAllNodes" SG_ 544 PTODisengCrsCntlIO 1;
BA_REL_ "GenSigSuprvResp" BU_SG_REL_ FCM_HS SG_ 844 IMUProtYawRt 1;
BA_REL_ "GenSigTimeoutMsg" BU_SG_REL_ FCM_HS SG_ 844 IMUProtYawRt 844;
BA_REL_ "GenSigTimeoutTime" BU_SG_REL_ FCM_HS SG_ 844 IMUProtYawRt 250;
BA_REL_ "GenSigSuprvResp" BU_SG_REL_ FCM_HS SG_ 844 IMUProtYawRt 1;
BA_REL_ "GenSigTimeoutMsg" BU_SG_REL_ FCM_HS SG_ 844 IMUProtYawRt 844;
BA_REL_ "GenSigTimeoutTime" BU_SG_REL_ FCM_HS SG_ 844 IMUProtYawRt 250;
BA_REL_ "GenSigSuprvResp" BU_SG_REL_ FCM_HS SG_ 844 IMUProtLonAcc 1;
BA_REL_ "GenSigTimeoutMsg" BU_SG_REL_ FCM_HS SG_ 844 IMUProtLonAcc 844;
BA_REL_ "GenSigTimeoutTime" BU_SG_REL_ FCM_HS SG_ 844 IMUProtLonAcc 250;
BA_REL_ "GenSigSuprvResp" BU_SG_REL_ FCM_HS SG_ 844 IMUProtLatAcc 1;
BA_REL_ "GenSigTimeoutMsg" BU_SG_REL_ FCM_HS SG_ 844 IMUProtLatAcc 844;
BA_REL_ "GenSigTimeoutTime" BU_SG_REL_ FCM_HS SG_ 844 IMUProtLatAcc 250;
BA_REL_ "GenSigSuprvResp" BU_SG_REL_ FCM_HS SG_ 844 IMUProtChksum 1;
BA_REL_ "GenSigTimeoutMsg" BU_SG_REL_ FCM_HS SG_ 844 IMUProtChksum 844;
BA_REL_ "GenSigTimeoutTime" BU_SG_REL_ FCM_HS SG_ 844 IMUProtChksum 250;
BA_REL_ "GenSigSuprvResp" BU_SG_REL_ FCM_HS SG_ 844 IMUProtChksum 1;
BA_REL_ "GenSigTimeoutMsg" BU_SG_REL_ FCM_HS SG_ 844 IMUProtChksum 844;
BA_REL_ "GenSigTimeoutTime" BU_SG_REL_ FCM_HS SG_ 844 IMUProtChksum 250;
BA_REL_ "GenSigSuprvResp" BU_SG_REL_ FCM_HS SG_ 844 IMUProtARC 1;
BA_REL_ "GenSigTimeoutMsg" BU_SG_REL_ FCM_HS SG_ 844 IMUProtARC 844;
BA_REL_ "GenSigTimeoutTime" BU_SG_REL_ FCM_HS SG_ 844 IMUProtARC 250;
BA_REL_ "GenSigSuprvResp" BU_SG_REL_ FCM_HS SG_ 844 IMUProtARC 1;
BA_REL_ "GenSigTimeoutMsg" BU_SG_REL_ FCM_HS SG_ 844 IMUProtARC 844;
BA_REL_ "GenSigTimeoutTime" BU_SG_REL_ FCM_HS SG_ 844 IMUProtARC 250;
BA_REL_ "GenSigSuprvResp" BU_SG_REL_ BCM_HS SG_ 806 DCCnvStblznErrIO 1;
BA_REL_ "GenSigTimeoutMsg" BU_SG_REL_ BCM_HS SG_ 806 DCCnvStblznErrIO 806;
BA_REL_ "GenSigTimeoutTime" BU_SG_REL_ BCM_HS SG_ 806 DCCnvStblznErrIO 1250;
BA_REL_ "GenSigSuprvResp" BU_SG_REL_ TCM_HS SG_ 426 EngPrdctStdyStTorq 1;
BA_REL_ "GenSigTimeoutMsg" BU_SG_REL_ TCM_HS SG_ 426 EngPrdctStdyStTorq 426;
BA_REL_ "GenSigTimeoutTime" BU_SG_REL_ TCM_HS SG_ 426 EngPrdctStdyStTorq 250;
BA_REL_ "GenSigSuprvResp" BU_SG_REL_ TCM_HS SG_ 426 CrnkShftTrqMinOffCap 1;
BA_REL_ "GenSigTimeoutMsg" BU_SG_REL_ TCM_HS SG_ 426 CrnkShftTrqMinOffCap 426;
BA_REL_ "GenSigTimeoutTime" BU_SG_REL_ TCM_HS SG_ 426 CrnkShftTrqMinOffCap 250;
BA_REL_ "GenSigSuprvResp" BU_SG_REL_ TCM_HS SG_ 426 CrksftTqMinRunImCap 1;
BA_REL_ "GenSigTimeoutMsg" BU_SG_REL_ TCM_HS SG_ 426 CrksftTqMinRunImCap 426;
BA_REL_ "GenSigTimeoutTime" BU_SG_REL_ TCM_HS SG_ 426 CrksftTqMinRunImCap 250;
BA_REL_ "GenSigSuprvResp" BU_SG_REL_ BCM_HS SG_ 1231 DslExhFluidDistTIndcmt 1;
BA_REL_ "GenSigTimeoutMsg" BU_SG_REL_ BCM_HS SG_ 1231 DslExhFluidDistTIndcmt 1231;
BA_REL_ "GenSigTimeoutTime" BU_SG_REL_ BCM_HS SG_ 1231 DslExhFluidDistTIndcmt 2500;
BA_REL_ "GenSigSuprvResp" BU_SG_REL_ BCM_HS SG_ 1231 DslExhFluidLvlPrcnt 1;
BA_REL_ "GenSigTimeoutMsg" BU_SG_REL_ BCM_HS SG_ 1231 DslExhFluidLvlPrcnt 1231;
BA_REL_ "GenSigTimeoutTime" BU_SG_REL_ BCM_HS SG_ 1231 DslExhFluidLvlPrcnt 2500;
BA_REL_ "GenSigSuprvResp" BU_SG_REL_ ECM_HS SG_ 963 CltTmpCntlMdEmRMAct 1;
BA_REL_ "GenSigTimeoutMsg" BU_SG_REL_ ECM_HS SG_ 963 CltTmpCntlMdEmRMAct 963;
BA_REL_ "GenSigTimeoutTime" BU_SG_REL_ ECM_HS SG_ 963 CltTmpCntlMdEmRMAct 250;
BA_REL_ "GenSigSuprvResp" BU_SG_REL_ ECM_HS SG_ 963 CTCMERDTC_SysDes 1;
BA_REL_ "GenSigTimeoutMsg" BU_SG_REL_ ECM_HS SG_ 963 CTCMERDTC_SysDes 963;
BA_REL_ "GenSigTimeoutTime" BU_SG_REL_ ECM_HS SG_ 963 CTCMERDTC_SysDes 250;
BA_REL_ "GenSigSuprvResp" BU_SG_REL_ ECM_HS SG_ 963 CTCMERDTC_CdNum 1;
BA_REL_ "GenSigTimeoutMsg" BU_SG_REL_ ECM_HS SG_ 963 CTCMERDTC_CdNum 963;
BA_REL_ "GenSigTimeoutTime" BU_SG_REL_ ECM_HS SG_ 963 CTCMERDTC_CdNum 250;
BA_REL_ "GenSigSuprvResp" BU_SG_REL_ PCM_HS SG_ 955 RdctHtrCrntFdbckRC 1;
BA_REL_ "GenSigTimeoutMsg" BU_SG_REL_ PCM_HS SG_ 955 RdctHtrCrntFdbckRC 955;
BA_REL_ "GenSigTimeoutTime" BU_SG_REL_ PCM_HS SG_ 955 RdctHtrCrntFdbckRC 250;
BA_REL_ "GenSigSuprvResp" BU_SG_REL_ ECM_HS SG_ 955 RdctHtrCrntFdbckRC 1;
BA_REL_ "GenSigTimeoutMsg" BU_SG_REL_ ECM_HS SG_ 955 RdctHtrCrntFdbckRC 955;
BA_REL_ "GenSigTimeoutTime" BU_SG_REL_ ECM_HS SG_ 955 RdctHtrCrntFdbckRC 250;
BA_REL_ "GenSigSuprvResp" BU_SG_REL_ PCM_HS SG_ 955 RdctHtrCctStatPV 1;
BA_REL_ "GenSigTimeoutMsg" BU_SG_REL_ PCM_HS SG_ 955 RdctHtrCctStatPV 955;
BA_REL_ "GenSigTimeoutTime" BU_SG_REL_ PCM_HS SG_ 955 RdctHtrCctStatPV 250;
BA_REL_ "GenSigSuprvResp" BU_SG_REL_ ECM_HS SG_ 955 RdctHtrCctStatPV 1;
BA_REL_ "GenSigTimeoutMsg" BU_SG_REL_ ECM_HS SG_ 955 RdctHtrCctStatPV 955;
BA_REL_ "GenSigTimeoutTime" BU_SG_REL_ ECM_HS SG_ 955 RdctHtrCctStatPV 250;
BA_REL_ "GenSigSuprvResp" BU_SG_REL_ PCM_HS SG_ 955 RdctHtrCCrntFdbckPVa 1;
BA_REL_ "GenSigTimeoutMsg" BU_SG_REL_ PCM_HS SG_ 955 RdctHtrCCrntFdbckPVa 955;
BA_REL_ "GenSigTimeoutTime" BU_SG_REL_ PCM_HS SG_ 955 RdctHtrCCrntFdbckPVa 250;
BA_REL_ "GenSigSuprvResp" BU_SG_REL_ ECM_HS SG_ 955 RdctHtrCCrntFdbckPVa 1;
BA_REL_ "GenSigTimeoutMsg" BU_SG_REL_ ECM_HS SG_ 955 RdctHtrCCrntFdbckPVa 955;
BA_REL_ "GenSigTimeoutTime" BU_SG_REL_ ECM_HS SG_ 955 RdctHtrCCrntFdbckPVa 250;
BA_REL_ "GenSigSuprvResp" BU_SG_REL_ ECM_HS SG_ 955 RdctHtrCCrntFdbckPVa 1;
BA_REL_ "GenSigTimeoutMsg" BU_SG_REL_ ECM_HS SG_ 955 RdctHtrCCrntFdbckPVa 955;
BA_REL_ "GenSigTimeoutTime" BU_SG_REL_ ECM_HS SG_ 955 RdctHtrCCrntFdbckPVa 250;
BA_REL_ "GenSigSuprvResp" BU_SG_REL_ PCM_HS SG_ 955 RdctHtrBCrntFdbckPVa 1;
BA_REL_ "GenSigTimeoutMsg" BU_SG_REL_ PCM_HS SG_ 955 RdctHtrBCrntFdbckPVa 955;
BA_REL_ "GenSigTimeoutTime" BU_SG_REL_ PCM_HS SG_ 955 RdctHtrBCrntFdbckPVa 250;
BA_REL_ "GenSigSuprvResp" BU_SG_REL_ ECM_HS SG_ 955 RdctHtrBCrntFdbckPVa 1;
BA_REL_ "GenSigTimeoutMsg" BU_SG_REL_ ECM_HS SG_ 955 RdctHtrBCrntFdbckPVa 955;
BA_REL_ "GenSigTimeoutTime" BU_SG_REL_ ECM_HS SG_ 955 RdctHtrBCrntFdbckPVa 250;
BA_REL_ "GenSigSuprvResp" BU_SG_REL_ ECM_HS SG_ 955 RdctHtrBCrntFdbckPVa 1;
BA_REL_ "GenSigTimeoutMsg" BU_SG_REL_ ECM_HS SG_ 955 RdctHtrBCrntFdbckPVa 955;
BA_REL_ "GenSigTimeoutTime" BU_SG_REL_ ECM_HS SG_ 955 RdctHtrBCrntFdbckPVa 250;
BA_REL_ "GenSigSuprvResp" BU_SG_REL_ PCM_HS SG_ 955 RdctHtrACrntFdbckPVa 1;
BA_REL_ "GenSigTimeoutMsg" BU_SG_REL_ PCM_HS SG_ 955 RdctHtrACrntFdbckPVa 955;
BA_REL_ "GenSigTimeoutTime" BU_SG_REL_ PCM_HS SG_ 955 RdctHtrACrntFdbckPVa 250;
BA_REL_ "GenSigSuprvResp" BU_SG_REL_ ECM_HS SG_ 955 RdctHtrACrntFdbckPVa 1;
BA_REL_ "GenSigTimeoutMsg" BU_SG_REL_ ECM_HS SG_ 955 RdctHtrACrntFdbckPVa 955;
BA_REL_ "GenSigTimeoutTime" BU_SG_REL_ ECM_HS SG_ 955 RdctHtrACrntFdbckPVa 250;
BA_REL_ "GenSigSuprvResp" BU_SG_REL_ ECM_HS SG_ 955 RdctHtrACrntFdbckPVa 1;
BA_REL_ "GenSigTimeoutMsg" BU_SG_REL_ ECM_HS SG_ 955 RdctHtrACrntFdbckPVa 955;
BA_REL_ "GenSigTimeoutTime" BU_SG_REL_ ECM_HS SG_ 955 RdctHtrACrntFdbckPVa 250;
BA_REL_ "GenSigSuprvResp" BU_SG_REL_ PCM_HS SG_ 955 RdctHtrCCrntFdbck 1;
BA_REL_ "GenSigTimeoutMsg" BU_SG_REL_ PCM_HS SG_ 955 RdctHtrCCrntFdbck 955;
BA_REL_ "GenSigTimeoutTime" BU_SG_REL_ PCM_HS SG_ 955 RdctHtrCCrntFdbck 250;
BA_REL_ "GenSigSuprvResp" BU_SG_REL_ ECM_HS SG_ 955 RdctHtrCCrntFdbck 1;
BA_REL_ "GenSigTimeoutMsg" BU_SG_REL_ ECM_HS SG_ 955 RdctHtrCCrntFdbck 955;
BA_REL_ "GenSigTimeoutTime" BU_SG_REL_ ECM_HS SG_ 955 RdctHtrCCrntFdbck 250;
BA_REL_ "GenSigSuprvResp" BU_SG_REL_ ECM_HS SG_ 955 RdctHtrCCrntFdbck 1;
BA_REL_ "GenSigTimeoutMsg" BU_SG_REL_ ECM_HS SG_ 955 RdctHtrCCrntFdbck 955;
BA_REL_ "GenSigTimeoutTime" BU_SG_REL_ ECM_HS SG_ 955 RdctHtrCCrntFdbck 250;
BA_REL_ "GenSigSuprvResp" BU_SG_REL_ PCM_HS SG_ 955 RdctHtrBCrntFdbck 1;
BA_REL_ "GenSigTimeoutMsg" BU_SG_REL_ PCM_HS SG_ 955 RdctHtrBCrntFdbck 955;
BA_REL_ "GenSigTimeoutTime" BU_SG_REL_ PCM_HS SG_ 955 RdctHtrBCrntFdbck 250;
BA_REL_ "GenSigSuprvResp" BU_SG_REL_ ECM_HS SG_ 955 RdctHtrBCrntFdbck 1;
BA_REL_ "GenSigTimeoutMsg" BU_SG_REL_ ECM_HS SG_ 955 RdctHtrBCrntFdbck 955;
BA_REL_ "GenSigTimeoutTime" BU_SG_REL_ ECM_HS SG_ 955 RdctHtrBCrntFdbck 250;
BA_REL_ "GenSigSuprvResp" BU_SG_REL_ ECM_HS SG_ 955 RdctHtrBCrntFdbck 1;
BA_REL_ "GenSigTimeoutMsg" BU_SG_REL_ ECM_HS SG_ 955 RdctHtrBCrntFdbck 955;
BA_REL_ "GenSigTimeoutTime" BU_SG_REL_ ECM_HS SG_ 955 RdctHtrBCrntFdbck 250;
BA_REL_ "GenSigSuprvResp" BU_SG_REL_ PCM_HS SG_ 955 RdctHtrACrntFdbck 1;
BA_REL_ "GenSigTimeoutMsg" BU_SG_REL_ PCM_HS SG_ 955 RdctHtrACrntFdbck 955;
BA_REL_ "GenSigTimeoutTime" BU_SG_REL_ PCM_HS SG_ 955 RdctHtrACrntFdbck 250;
BA_REL_ "GenSigSuprvResp" BU_SG_REL_ ECM_HS SG_ 955 RdctHtrACrntFdbck 1;
BA_REL_ "GenSigTimeoutMsg" BU_SG_REL_ ECM_HS SG_ 955 RdctHtrACrntFdbck 955;
BA_REL_ "GenSigTimeoutTime" BU_SG_REL_ ECM_HS SG_ 955 RdctHtrACrntFdbck 250;
BA_REL_ "GenSigSuprvResp" BU_SG_REL_ ECM_HS SG_ 955 RdctHtrACrntFdbck 1;
BA_REL_ "GenSigTimeoutMsg" BU_SG_REL_ ECM_HS SG_ 955 RdctHtrACrntFdbck 955;
BA_REL_ "GenSigTimeoutTime" BU_SG_REL_ ECM_HS SG_ 955 RdctHtrACrntFdbck 250;
BA_REL_ "GenSigSuprvResp" BU_SG_REL_ TCM_HS SG_ 208 WhlSlipRRWhl 1;
BA_REL_ "GenSigTimeoutMsg" BU_SG_REL_ TCM_HS SG_ 208 WhlSlipRRWhl 208;
BA_REL_ "GenSigTimeoutTime" BU_SG_REL_ TCM_HS SG_ 208 WhlSlipRRWhl 250;
BA_REL_ "GenSigSuprvResp" BU_SG_REL_ TCM_HS SG_ 208 WhlSlipLRWhl 1;
BA_REL_ "GenSigTimeoutMsg" BU_SG_REL_ TCM_HS SG_ 208 WhlSlipLRWhl 208;
BA_REL_ "GenSigTimeoutTime" BU_SG_REL_ TCM_HS SG_ 208 WhlSlipLRWhl 250;
BA_REL_ "GenSigSuprvResp" BU_SG_REL_ TCM_HS SG_ 208 WhlSlipRFWhl 1;
BA_REL_ "GenSigTimeoutMsg" BU_SG_REL_ TCM_HS SG_ 208 WhlSlipRFWhl 208;
BA_REL_ "GenSigTimeoutTime" BU_SG_REL_ TCM_HS SG_ 208 WhlSlipRFWhl 250;
BA_REL_ "GenSigSuprvResp" BU_SG_REL_ TCM_HS SG_ 208 WhlSlipLFWhl 1;
BA_REL_ "GenSigTimeoutMsg" BU_SG_REL_ TCM_HS SG_ 208 WhlSlipLFWhl 208;
BA_REL_ "GenSigTimeoutTime" BU_SG_REL_ TCM_HS SG_ 208 WhlSlipLFWhl 250;
BA_REL_ "GenSigSuprvResp" BU_SG_REL_ BCM_HS SG_ 563 SPMCA_SusPrfMd6Avl 1;
BA_REL_ "GenSigTimeoutMsg" BU_SG_REL_ BCM_HS SG_ 563 SPMCA_SusPrfMd6Avl 563;
BA_REL_ "GenSigTimeoutTime" BU_SG_REL_ BCM_HS SG_ 563 SPMCA_SusPrfMd6Avl 5000;
BA_REL_ "GenSigSuprvResp" BU_SG_REL_ BCM_HS SG_ 563 SPMCA_SusPrfMd5Avl 1;
BA_REL_ "GenSigTimeoutMsg" BU_SG_REL_ BCM_HS SG_ 563 SPMCA_SusPrfMd5Avl 563;
BA_REL_ "GenSigTimeoutTime" BU_SG_REL_ BCM_HS SG_ 563 SPMCA_SusPrfMd5Avl 5000;
BA_REL_ "GenSigSuprvResp" BU_SG_REL_ BCM_HS SG_ 563 SPMCA_SusPrfMd4Avl 1;
BA_REL_ "GenSigTimeoutMsg" BU_SG_REL_ BCM_HS SG_ 563 SPMCA_SusPrfMd4Avl 563;
BA_REL_ "GenSigTimeoutTime" BU_SG_REL_ BCM_HS SG_ 563 SPMCA_SusPrfMd4Avl 5000;
BA_REL_ "GenSigSuprvResp" BU_SG_REL_ BCM_HS SG_ 563 SPMCA_SusPrfMd3Avl 1;
BA_REL_ "GenSigTimeoutMsg" BU_SG_REL_ BCM_HS SG_ 563 SPMCA_SusPrfMd3Avl 563;
BA_REL_ "GenSigTimeoutTime" BU_SG_REL_ BCM_HS SG_ 563 SPMCA_SusPrfMd3Avl 5000;
BA_REL_ "GenSigSuprvResp" BU_SG_REL_ BCM_HS SG_ 563 SPMCA_SusPrfMd2Avl 1;
BA_REL_ "GenSigTimeoutMsg" BU_SG_REL_ BCM_HS SG_ 563 SPMCA_SusPrfMd2Avl 563;
BA_REL_ "GenSigTimeoutTime" BU_SG_REL_ BCM_HS SG_ 563 SPMCA_SusPrfMd2Avl 5000;
BA_REL_ "GenSigSuprvResp" BU_SG_REL_ BCM_HS SG_ 563 SPMCA_SusPrfMd1Avl 1;
BA_REL_ "GenSigTimeoutMsg" BU_SG_REL_ BCM_HS SG_ 563 SPMCA_SusPrfMd1Avl 563;
BA_REL_ "GenSigTimeoutTime" BU_SG_REL_ BCM_HS SG_ 563 SPMCA_SusPrfMd1Avl 5000;
BA_REL_ "GenSigSuprvResp" BU_SG_REL_ BCM_HS SG_ 563 SPMCA_StrPrfMd6Avl 1;
BA_REL_ "GenSigTimeoutMsg" BU_SG_REL_ BCM_HS SG_ 563 SPMCA_StrPrfMd6Avl 563;
BA_REL_ "GenSigTimeoutTime" BU_SG_REL_ BCM_HS SG_ 563 SPMCA_StrPrfMd6Avl 5000;
BA_REL_ "GenSigSuprvResp" BU_SG_REL_ BCM_HS SG_ 563 SPMCA_StrPrfMd5Avl 1;
BA_REL_ "GenSigTimeoutMsg" BU_SG_REL_ BCM_HS SG_ 563 SPMCA_StrPrfMd5Avl 563;
BA_REL_ "GenSigTimeoutTime" BU_SG_REL_ BCM_HS SG_ 563 SPMCA_StrPrfMd5Avl 5000;
BA_REL_ "GenSigSuprvResp" BU_SG_REL_ BCM_HS SG_ 563 SPMCA_StrPrfMd4Avl 1;
BA_REL_ "GenSigTimeoutMsg" BU_SG_REL_ BCM_HS SG_ 563 SPMCA_StrPrfMd4Avl 563;
BA_REL_ "GenSigTimeoutTime" BU_SG_REL_ BCM_HS SG_ 563 SPMCA_StrPrfMd4Avl 5000;
BA_REL_ "GenSigSuprvResp" BU_SG_REL_ BCM_HS SG_ 563 SPMCA_StrPrfMd3Avl 1;
BA_REL_ "GenSigTimeoutMsg" BU_SG_REL_ BCM_HS SG_ 563 SPMCA_StrPrfMd3Avl 563;
BA_REL_ "GenSigTimeoutTime" BU_SG_REL_ BCM_HS SG_ 563 SPMCA_StrPrfMd3Avl 5000;
BA_REL_ "GenSigSuprvResp" BU_SG_REL_ BCM_HS SG_ 563 SPMCA_StrPrfMd2Avl 1;
BA_REL_ "GenSigTimeoutMsg" BU_SG_REL_ BCM_HS SG_ 563 SPMCA_StrPrfMd2Avl 563;
BA_REL_ "GenSigTimeoutTime" BU_SG_REL_ BCM_HS SG_ 563 SPMCA_StrPrfMd2Avl 5000;
BA_REL_ "GenSigSuprvResp" BU_SG_REL_ BCM_HS SG_ 563 SPMCA_StrPrfMd1Avl 1;
BA_REL_ "GenSigTimeoutMsg" BU_SG_REL_ BCM_HS SG_ 563 SPMCA_StrPrfMd1Avl 563;
BA_REL_ "GenSigTimeoutTime" BU_SG_REL_ BCM_HS SG_ 563 SPMCA_StrPrfMd1Avl 5000;
BA_REL_ "GenSigSuprvResp" BU_SG_REL_ BCM_HS SG_ 563 SPMCA_SndPrfMd6Avl 1;
BA_REL_ "GenSigTimeoutMsg" BU_SG_REL_ BCM_HS SG_ 563 SPMCA_SndPrfMd6Avl 563;
BA_REL_ "GenSigTimeoutTime" BU_SG_REL_ BCM_HS SG_ 563 SPMCA_SndPrfMd6Avl 5000;
BA_REL_ "GenSigSuprvResp" BU_SG_REL_ BCM_HS SG_ 563 SPMCA_SndPrfMd5Avl 1;
BA_REL_ "GenSigTimeoutMsg" BU_SG_REL_ BCM_HS SG_ 563 SPMCA_SndPrfMd5Avl 563;
BA_REL_ "GenSigTimeoutTime" BU_SG_REL_ BCM_HS SG_ 563 SPMCA_SndPrfMd5Avl 5000;
BA_REL_ "GenSigSuprvResp" BU_SG_REL_ BCM_HS SG_ 563 SPMCA_SndPrfMd4Avl 1;
BA_REL_ "GenSigTimeoutMsg" BU_SG_REL_ BCM_HS SG_ 563 SPMCA_SndPrfMd4Avl 563;
BA_REL_ "GenSigTimeoutTime" BU_SG_REL_ BCM_HS SG_ 563 SPMCA_SndPrfMd4Avl 5000;
BA_REL_ "GenSigSuprvResp" BU_SG_REL_ BCM_HS SG_ 563 SPMCA_SndPrfMd3Avl 1;
BA_REL_ "GenSigTimeoutMsg" BU_SG_REL_ BCM_HS SG_ 563 SPMCA_SndPrfMd3Avl 563;
BA_REL_ "GenSigTimeoutTime" BU_SG_REL_ BCM_HS SG_ 563 SPMCA_SndPrfMd3Avl 5000;
BA_REL_ "GenSigSuprvResp" BU_SG_REL_ BCM_HS SG_ 563 SPMCA_SndPrfMd2Avl 1;
BA_REL_ "GenSigTimeoutMsg" BU_SG_REL_ BCM_HS SG_ 563 SPMCA_SndPrfMd2Avl 563;
BA_REL_ "GenSigTimeoutTime" BU_SG_REL_ BCM_HS SG_ 563 SPMCA_SndPrfMd2Avl 5000;
BA_REL_ "GenSigSuprvResp" BU_SG_REL_ BCM_HS SG_ 563 SPMCA_SndPrfMd1Avl 1;
BA_REL_ "GenSigTimeoutMsg" BU_SG_REL_ BCM_HS SG_ 563 SPMCA_SndPrfMd1Avl 563;
BA_REL_ "GenSigTimeoutTime" BU_SG_REL_ BCM_HS SG_ 563 SPMCA_SndPrfMd1Avl 5000;
BA_REL_ "GenSigSuprvResp" BU_SG_REL_ BCM_HS SG_ 563 DPMCA_DispPrfMd6Avl 1;
BA_REL_ "GenSigTimeoutMsg" BU_SG_REL_ BCM_HS SG_ 563 DPMCA_DispPrfMd6Avl 563;
BA_REL_ "GenSigTimeoutTime" BU_SG_REL_ BCM_HS SG_ 563 DPMCA_DispPrfMd6Avl 5000;
BA_REL_ "GenSigSuprvResp" BU_SG_REL_ BCM_HS SG_ 563 DPMCA_DispPrfMd5Avl 1;
BA_REL_ "GenSigTimeoutMsg" BU_SG_REL_ BCM_HS SG_ 563 DPMCA_DispPrfMd5Avl 563;
BA_REL_ "GenSigTimeoutTime" BU_SG_REL_ BCM_HS SG_ 563 DPMCA_DispPrfMd5Avl 5000;
BA_REL_ "GenSigSuprvResp" BU_SG_REL_ BCM_HS SG_ 563 DPMCA_DispPrfMd4Avl 1;
BA_REL_ "GenSigTimeoutMsg" BU_SG_REL_ BCM_HS SG_ 563 DPMCA_DispPrfMd4Avl 563;
BA_REL_ "GenSigTimeoutTime" BU_SG_REL_ BCM_HS SG_ 563 DPMCA_DispPrfMd4Avl 5000;
BA_REL_ "GenSigSuprvResp" BU_SG_REL_ BCM_HS SG_ 563 DPMCA_DispPrfMd3Avl 1;
BA_REL_ "GenSigTimeoutMsg" BU_SG_REL_ BCM_HS SG_ 563 DPMCA_DispPrfMd3Avl 563;
BA_REL_ "GenSigTimeoutTime" BU_SG_REL_ BCM_HS SG_ 563 DPMCA_DispPrfMd3Avl 5000;
BA_REL_ "GenSigSuprvResp" BU_SG_REL_ BCM_HS SG_ 563 DPMCA_DispPrfMd2Avl 1;
BA_REL_ "GenSigTimeoutMsg" BU_SG_REL_ BCM_HS SG_ 563 DPMCA_DispPrfMd2Avl 563;
BA_REL_ "GenSigTimeoutTime" BU_SG_REL_ BCM_HS SG_ 563 DPMCA_DispPrfMd2Avl 5000;
BA_REL_ "GenSigSuprvResp" BU_SG_REL_ BCM_HS SG_ 563 DPMCA_DispPrfMd1Avl 1;
BA_REL_ "GenSigTimeoutMsg" BU_SG_REL_ BCM_HS SG_ 563 DPMCA_DispPrfMd1Avl 563;
BA_REL_ "GenSigTimeoutTime" BU_SG_REL_ BCM_HS SG_ 563 DPMCA_DispPrfMd1Avl 5000;
BA_REL_ "GenSigSuprvResp" BU_SG_REL_ BCM_HS SG_ 563 DPMCA_DrvlPrfMd6Avl 1;
BA_REL_ "GenSigTimeoutMsg" BU_SG_REL_ BCM_HS SG_ 563 DPMCA_DrvlPrfMd6Avl 563;
BA_REL_ "GenSigTimeoutTime" BU_SG_REL_ BCM_HS SG_ 563 DPMCA_DrvlPrfMd6Avl 5000;
BA_REL_ "GenSigSuprvResp" BU_SG_REL_ BCM_HS SG_ 563 DPMCA_DrvlPrfMd5Avl 1;
BA_REL_ "GenSigTimeoutMsg" BU_SG_REL_ BCM_HS SG_ 563 DPMCA_DrvlPrfMd5Avl 563;
BA_REL_ "GenSigTimeoutTime" BU_SG_REL_ BCM_HS SG_ 563 DPMCA_DrvlPrfMd5Avl 5000;
BA_REL_ "GenSigSuprvResp" BU_SG_REL_ BCM_HS SG_ 563 DPMCA_DrvlPrfMd4Avl 1;
BA_REL_ "GenSigTimeoutMsg" BU_SG_REL_ BCM_HS SG_ 563 DPMCA_DrvlPrfMd4Avl 563;
BA_REL_ "GenSigTimeoutTime" BU_SG_REL_ BCM_HS SG_ 563 DPMCA_DrvlPrfMd4Avl 5000;
BA_REL_ "GenSigSuprvResp" BU_SG_REL_ BCM_HS SG_ 563 DPMCA_DrvlPrfMd3Avl 1;
BA_REL_ "GenSigTimeoutMsg" BU_SG_REL_ BCM_HS SG_ 563 DPMCA_DrvlPrfMd3Avl 563;
BA_REL_ "GenSigTimeoutTime" BU_SG_REL_ BCM_HS SG_ 563 DPMCA_DrvlPrfMd3Avl 5000;
BA_REL_ "GenSigSuprvResp" BU_SG_REL_ BCM_HS SG_ 563 DPMCA_DrvlPrfMd2Avl 1;
BA_REL_ "GenSigTimeoutMsg" BU_SG_REL_ BCM_HS SG_ 563 DPMCA_DrvlPrfMd2Avl 563;
BA_REL_ "GenSigTimeoutTime" BU_SG_REL_ BCM_HS SG_ 563 DPMCA_DrvlPrfMd2Avl 5000;
BA_REL_ "GenSigSuprvResp" BU_SG_REL_ BCM_HS SG_ 563 DPMCA_DrvlPrfMd1Avl 1;
BA_REL_ "GenSigTimeoutMsg" BU_SG_REL_ BCM_HS SG_ 563 DPMCA_DrvlPrfMd1Avl 563;
BA_REL_ "GenSigTimeoutTime" BU_SG_REL_ BCM_HS SG_ 563 DPMCA_DrvlPrfMd1Avl 5000;
BA_REL_ "GenSigSuprvResp" BU_SG_REL_ EBCM_OBD_HS SG_ 1323 TireLRTmp 1;
BA_REL_ "GenSigTimeoutMsg" BU_SG_REL_ EBCM_OBD_HS SG_ 1323 TireLRTmp 1323;
BA_REL_ "GenSigTimeoutTime" BU_SG_REL_ EBCM_OBD_HS SG_ 1323 TireLRTmp 2500;
BA_REL_ "GenSigSuprvResp" BU_SG_REL_ EBCM_HS SG_ 1323 TireLRTmp 1;
BA_REL_ "GenSigTimeoutMsg" BU_SG_REL_ EBCM_HS SG_ 1323 TireLRTmp 1323;
BA_REL_ "GenSigTimeoutTime" BU_SG_REL_ EBCM_HS SG_ 1323 TireLRTmp 2500;
BA_REL_ "GenSigSuprvResp" BU_SG_REL_ ICCM_OBD_HS SG_ 1323 TireLRTmp 1;
BA_REL_ "GenSigTimeoutMsg" BU_SG_REL_ ICCM_OBD_HS SG_ 1323 TireLRTmp 1323;
BA_REL_ "GenSigTimeoutTime" BU_SG_REL_ ICCM_OBD_HS SG_ 1323 TireLRTmp 2500;
BA_REL_ "GenSigSuprvResp" BU_SG_REL_ ICCM_HS SG_ 1323 TireLRTmp 1;
BA_REL_ "GenSigTimeoutMsg" BU_SG_REL_ ICCM_HS SG_ 1323 TireLRTmp 1323;
BA_REL_ "GenSigTimeoutTime" BU_SG_REL_ ICCM_HS SG_ 1323 TireLRTmp 2500;
BA_REL_ "GenSigSuprvResp" BU_SG_REL_ RDCM_HS SG_ 1323 TireLRTmp 1;
BA_REL_ "GenSigTimeoutMsg" BU_SG_REL_ RDCM_HS SG_ 1323 TireLRTmp 1323;
BA_REL_ "GenSigTimeoutTime" BU_SG_REL_ RDCM_HS SG_ 1323 TireLRTmp 2500;
BA_REL_ "GenSigSuprvResp" BU_SG_REL_ EBCM_OBD_HS SG_ 1323 TireLFTmp 1;
BA_REL_ "GenSigTimeoutMsg" BU_SG_REL_ EBCM_OBD_HS SG_ 1323 TireLFTmp 1323;
BA_REL_ "GenSigTimeoutTime" BU_SG_REL_ EBCM_OBD_HS SG_ 1323 TireLFTmp 2500;
BA_REL_ "GenSigSuprvResp" BU_SG_REL_ EBCM_HS SG_ 1323 TireLFTmp 1;
BA_REL_ "GenSigTimeoutMsg" BU_SG_REL_ EBCM_HS SG_ 1323 TireLFTmp 1323;
BA_REL_ "GenSigTimeoutTime" BU_SG_REL_ EBCM_HS SG_ 1323 TireLFTmp 2500;
BA_REL_ "GenSigSuprvResp" BU_SG_REL_ ICCM_OBD_HS SG_ 1323 TireLFTmp 1;
BA_REL_ "GenSigTimeoutMsg" BU_SG_REL_ ICCM_OBD_HS SG_ 1323 TireLFTmp 1323;
BA_REL_ "GenSigTimeoutTime" BU_SG_REL_ ICCM_OBD_HS SG_ 1323 TireLFTmp 2500;
BA_REL_ "GenSigSuprvResp" BU_SG_REL_ ICCM_HS SG_ 1323 TireLFTmp 1;
BA_REL_ "GenSigTimeoutMsg" BU_SG_REL_ ICCM_HS SG_ 1323 TireLFTmp 1323;
BA_REL_ "GenSigTimeoutTime" BU_SG_REL_ ICCM_HS SG_ 1323 TireLFTmp 2500;
BA_REL_ "GenSigSuprvResp" BU_SG_REL_ RDCM_HS SG_ 1323 TireLFTmp 1;
BA_REL_ "GenSigTimeoutMsg" BU_SG_REL_ RDCM_HS SG_ 1323 TireLFTmp 1323;
BA_REL_ "GenSigTimeoutTime" BU_SG_REL_ RDCM_HS SG_ 1323 TireLFTmp 2500;
BA_REL_ "GenSigSuprvResp" BU_SG_REL_ EBCM_OBD_HS SG_ 1323 TireRRTmp 1;
BA_REL_ "GenSigTimeoutMsg" BU_SG_REL_ EBCM_OBD_HS SG_ 1323 TireRRTmp 1323;
BA_REL_ "GenSigTimeoutTime" BU_SG_REL_ EBCM_OBD_HS SG_ 1323 TireRRTmp 2500;
BA_REL_ "GenSigSuprvResp" BU_SG_REL_ EBCM_HS SG_ 1323 TireRRTmp 1;
BA_REL_ "GenSigTimeoutMsg" BU_SG_REL_ EBCM_HS SG_ 1323 TireRRTmp 1323;
BA_REL_ "GenSigTimeoutTime" BU_SG_REL_ EBCM_HS SG_ 1323 TireRRTmp 2500;
BA_REL_ "GenSigSuprvResp" BU_SG_REL_ ICCM_OBD_HS SG_ 1323 TireRRTmp 1;
BA_REL_ "GenSigTimeoutMsg" BU_SG_REL_ ICCM_OBD_HS SG_ 1323 TireRRTmp 1323;
BA_REL_ "GenSigTimeoutTime" BU_SG_REL_ ICCM_OBD_HS SG_ 1323 TireRRTmp 2500;
BA_REL_ "GenSigSuprvResp" BU_SG_REL_ ICCM_HS SG_ 1323 TireRRTmp 1;
BA_REL_ "GenSigTimeoutMsg" BU_SG_REL_ ICCM_HS SG_ 1323 TireRRTmp 1323;
BA_REL_ "GenSigTimeoutTime" BU_SG_REL_ ICCM_HS SG_ 1323 TireRRTmp 2500;
BA_REL_ "GenSigSuprvResp" BU_SG_REL_ RDCM_HS SG_ 1323 TireRRTmp 1;
BA_REL_ "GenSigTimeoutMsg" BU_SG_REL_ RDCM_HS SG_ 1323 TireRRTmp 1323;
BA_REL_ "GenSigTimeoutTime" BU_SG_REL_ RDCM_HS SG_ 1323 TireRRTmp 2500;
BA_REL_ "GenSigSuprvResp" BU_SG_REL_ EBCM_OBD_HS SG_ 1323 TireRFTmp 1;
BA_REL_ "GenSigTimeoutMsg" BU_SG_REL_ EBCM_OBD_HS SG_ 1323 TireRFTmp 1323;
BA_REL_ "GenSigTimeoutTime" BU_SG_REL_ EBCM_OBD_HS SG_ 1323 TireRFTmp 2500;
BA_REL_ "GenSigSuprvResp" BU_SG_REL_ EBCM_HS SG_ 1323 TireRFTmp 1;
BA_REL_ "GenSigTimeoutMsg" BU_SG_REL_ EBCM_HS SG_ 1323 TireRFTmp 1323;
BA_REL_ "GenSigTimeoutTime" BU_SG_REL_ EBCM_HS SG_ 1323 TireRFTmp 2500;
BA_REL_ "GenSigSuprvResp" BU_SG_REL_ ICCM_OBD_HS SG_ 1323 TireRFTmp 1;
BA_REL_ "GenSigTimeoutMsg" BU_SG_REL_ ICCM_OBD_HS SG_ 1323 TireRFTmp 1323;
BA_REL_ "GenSigTimeoutTime" BU_SG_REL_ ICCM_OBD_HS SG_ 1323 TireRFTmp 2500;
BA_REL_ "GenSigSuprvResp" BU_SG_REL_ ICCM_HS SG_ 1323 TireRFTmp 1;
BA_REL_ "GenSigTimeoutMsg" BU_SG_REL_ ICCM_HS SG_ 1323 TireRFTmp 1323;
BA_REL_ "GenSigTimeoutTime" BU_SG_REL_ ICCM_HS SG_ 1323 TireRFTmp 2500;
BA_REL_ "GenSigSuprvResp" BU_SG_REL_ RDCM_HS SG_ 1323 TireRFTmp 1;
BA_REL_ "GenSigTimeoutMsg" BU_SG_REL_ RDCM_HS SG_ 1323 TireRFTmp 1323;
BA_REL_ "GenSigTimeoutTime" BU_SG_REL_ RDCM_HS SG_ 1323 TireRFTmp 2500;
BA_REL_ "GenSigSuprvResp" BU_SG_REL_ TCM_HS SG_ 1247 RrPTCoolFanStat 1;
BA_REL_ "GenSigTimeoutMsg" BU_SG_REL_ TCM_HS SG_ 1247 RrPTCoolFanStat 1247;
BA_REL_ "GenSigTimeoutTime" BU_SG_REL_ TCM_HS SG_ 1247 RrPTCoolFanStat 1250;
BA_REL_ "GenSigSuprvResp" BU_SG_REL_ TCM_HS SG_ 1247 RrPTCoolFanSpPctCmd 1;
BA_REL_ "GenSigTimeoutMsg" BU_SG_REL_ TCM_HS SG_ 1247 RrPTCoolFanSpPctCmd 1247;
BA_REL_ "GenSigTimeoutTime" BU_SG_REL_ TCM_HS SG_ 1247 RrPTCoolFanSpPctCmd 1250;
BA_REL_ "GenSigSuprvResp" BU_SG_REL_ FCM_HS SG_ 873 FrtCmModIntgStat 1;
BA_REL_ "GenSigTimeoutMsg" BU_SG_REL_ FCM_HS SG_ 873 FrtCmModIntgStat 873;
BA_REL_ "GenSigTimeoutTime" BU_SG_REL_ FCM_HS SG_ 873 FrtCmModIntgStat 250;
BA_REL_ "GenSigSuprvResp" BU_SG_REL_ FCM_HS SG_ 873 FrtCmModAsmt 1;
BA_REL_ "GenSigTimeoutMsg" BU_SG_REL_ FCM_HS SG_ 873 FrtCmModAsmt 873;
BA_REL_ "GenSigTimeoutTime" BU_SG_REL_ FCM_HS SG_ 873 FrtCmModAsmt 250;
BA_REL_ "GenSigSuprvResp" BU_SG_REL_ FCM_HS SG_ 873 ACCMR_RptdChlng 1;
BA_REL_ "GenSigTimeoutMsg" BU_SG_REL_ FCM_HS SG_ 873 ACCMR_RptdChlng 873;
BA_REL_ "GenSigTimeoutTime" BU_SG_REL_ FCM_HS SG_ 873 ACCMR_RptdChlng 250;
BA_REL_ "GenSigSuprvResp" BU_SG_REL_ FCM_HS SG_ 873 ACCMR_Answr 1;
BA_REL_ "GenSigTimeoutMsg" BU_SG_REL_ FCM_HS SG_ 873 ACCMR_Answr 873;
BA_REL_ "GenSigTimeoutTime" BU_SG_REL_ FCM_HS SG_ 873 ACCMR_Answr 250;
BA_REL_ "GenSigSuprvResp" BU_SG_REL_ FCM_HS SG_ 873 AdptCrsCtrlModChlng 1;
BA_REL_ "GenSigTimeoutMsg" BU_SG_REL_ FCM_HS SG_ 873 AdptCrsCtrlModChlng 873;
BA_REL_ "GenSigTimeoutTime" BU_SG_REL_ FCM_HS SG_ 873 AdptCrsCtrlModChlng 250;
BA_REL_ "GenSigSuprvResp" BU_SG_REL_ FICM_HS SG_ 405 ThrPos 1;
BA_REL_ "GenSigTimeoutMsg" BU_SG_REL_ FICM_HS SG_ 405 ThrPos 405;
BA_REL_ "GenSigTimeoutTime" BU_SG_REL_ FICM_HS SG_ 405 ThrPos 250;
BA_REL_ "GenSigSuprvResp" BU_SG_REL_ VCM_HS SG_ 405 MassAirFlo 1;
BA_REL_ "GenSigTimeoutMsg" BU_SG_REL_ VCM_HS SG_ 405 MassAirFlo 405;
BA_REL_ "GenSigTimeoutTime" BU_SG_REL_ VCM_HS SG_ 405 MassAirFlo 250;
BA_REL_ "GenSigSuprvResp" BU_SG_REL_ FICM_HS SG_ 405 MassAirFlo 1;
BA_REL_ "GenSigTimeoutMsg" BU_SG_REL_ FICM_HS SG_ 405 MassAirFlo 405;
BA_REL_ "GenSigTimeoutTime" BU_SG_REL_ FICM_HS SG_ 405 MassAirFlo 250;
BA_REL_ "GenSigSuprvResp" BU_SG_REL_ FICM_HS SG_ 405 EngManfldAbsPrsER 1;
BA_REL_ "GenSigTimeoutMsg" BU_SG_REL_ FICM_HS SG_ 405 EngManfldAbsPrsER 405;
BA_REL_ "GenSigTimeoutTime" BU_SG_REL_ FICM_HS SG_ 405 EngManfldAbsPrsER 250;
BA_REL_ "GenSigSuprvResp" BU_SG_REL_ BCM_HS SG_ 419 EngRunng 1;
BA_REL_ "GenSigTimeoutMsg" BU_SG_REL_ BCM_HS SG_ 419 EngRunng 419;
BA_REL_ "GenSigTimeoutTime" BU_SG_REL_ BCM_HS SG_ 419 EngRunng 250;
BA_REL_ "GenSigSuprvResp" BU_SG_REL_ DCDC_HS SG_ 419 EngRunng 1;
BA_REL_ "GenSigTimeoutMsg" BU_SG_REL_ DCDC_HS SG_ 419 EngRunng 419;
BA_REL_ "GenSigTimeoutTime" BU_SG_REL_ DCDC_HS SG_ 419 EngRunng 250;
BA_REL_ "GenSigSuprvResp" BU_SG_REL_ TCCM_HS SG_ 419 EngRunng 1;
BA_REL_ "GenSigTimeoutMsg" BU_SG_REL_ TCCM_HS SG_ 419 EngRunng 419;
BA_REL_ "GenSigTimeoutTime" BU_SG_REL_ TCCM_HS SG_ 419 EngRunng 250;
BA_REL_ "GenSigSuprvResp" BU_SG_REL_ Dummy_HS SG_ 289 ARDM_RawData 1;
BA_REL_ "GenSigTimeoutMsg" BU_SG_REL_ Dummy_HS SG_ 289 ARDM_RawData 289;
BA_REL_ "GenSigTimeoutTime" BU_SG_REL_ Dummy_HS SG_ 289 ARDM_RawData 250;
BA_REL_ "GenSigSuprvResp" BU_SG_REL_ Dummy_HS SG_ 289 ARDM_MsgType 1;
BA_REL_ "GenSigTimeoutMsg" BU_SG_REL_ Dummy_HS SG_ 289 ARDM_MsgType 289;
BA_REL_ "GenSigTimeoutTime" BU_SG_REL_ Dummy_HS SG_ 289 ARDM_MsgType 250;
BA_REL_ "GenSigSuprvResp" BU_SG_REL_ ACC_HS SG_ 871 ACCModIntgStat 1;
BA_REL_ "GenSigTimeoutMsg" BU_SG_REL_ ACC_HS SG_ 871 ACCModIntgStat 871;
BA_REL_ "GenSigTimeoutTime" BU_SG_REL_ ACC_HS SG_ 871 ACCModIntgStat 250;
BA_REL_ "GenSigSuprvResp" BU_SG_REL_ ACC_HS SG_ 871 AdptCrsCtrlModAsmt 1;
BA_REL_ "GenSigTimeoutMsg" BU_SG_REL_ ACC_HS SG_ 871 AdptCrsCtrlModAsmt 871;
BA_REL_ "GenSigTimeoutTime" BU_SG_REL_ ACC_HS SG_ 871 AdptCrsCtrlModAsmt 250;
BA_REL_ "GenSigSuprvResp" BU_SG_REL_ ACC_HS SG_ 871 FCMR_RptdChlng 1;
BA_REL_ "GenSigTimeoutMsg" BU_SG_REL_ ACC_HS SG_ 871 FCMR_RptdChlng 871;
BA_REL_ "GenSigTimeoutTime" BU_SG_REL_ ACC_HS SG_ 871 FCMR_RptdChlng 250;
BA_REL_ "GenSigSuprvResp" BU_SG_REL_ ACC_HS SG_ 871 FCMR_Answr 1;
BA_REL_ "GenSigTimeoutMsg" BU_SG_REL_ ACC_HS SG_ 871 FCMR_Answr 871;
BA_REL_ "GenSigTimeoutTime" BU_SG_REL_ ACC_HS SG_ 871 FCMR_Answr 250;
BA_REL_ "GenSigSuprvResp" BU_SG_REL_ ACC_HS SG_ 871 FrtCmModChlng 1;
BA_REL_ "GenSigTimeoutMsg" BU_SG_REL_ ACC_HS SG_ 871 FrtCmModChlng 871;
BA_REL_ "GenSigTimeoutTime" BU_SG_REL_ ACC_HS SG_ 871 FrtCmModChlng 250;
BA_REL_ "GenSigSuprvResp" BU_SG_REL_ EBCM_OBD_HS SG_ 800 FCACtrlBrkSysCmdPrtVl 1;
BA_REL_ "GenSigTimeoutMsg" BU_SG_REL_ EBCM_OBD_HS SG_ 800 FCACtrlBrkSysCmdPrtVl 800;
BA_REL_ "GenSigTimeoutTime" BU_SG_REL_ EBCM_OBD_HS SG_ 800 FCACtrlBrkSysCmdPrtVl 250;
BA_REL_ "GenSigSuprvResp" BU_SG_REL_ EBCM_HS SG_ 800 FCACtrlBrkSysCmdPrtVl 1;
BA_REL_ "GenSigTimeoutMsg" BU_SG_REL_ EBCM_HS SG_ 800 FCACtrlBrkSysCmdPrtVl 800;
BA_REL_ "GenSigTimeoutTime" BU_SG_REL_ EBCM_HS SG_ 800 FCACtrlBrkSysCmdPrtVl 250;
BA_REL_ "GenSigSuprvResp" BU_SG_REL_ EBCM_OBD_HS SG_ 800 FCACBSC_CtrlAcc 1;
BA_REL_ "GenSigTimeoutMsg" BU_SG_REL_ EBCM_OBD_HS SG_ 800 FCACBSC_CtrlAcc 800;
BA_REL_ "GenSigTimeoutTime" BU_SG_REL_ EBCM_OBD_HS SG_ 800 FCACBSC_CtrlAcc 250;
BA_REL_ "GenSigSuprvResp" BU_SG_REL_ EBCM_HS SG_ 800 FCACBSC_CtrlAcc 1;
BA_REL_ "GenSigTimeoutMsg" BU_SG_REL_ EBCM_HS SG_ 800 FCACBSC_CtrlAcc 800;
BA_REL_ "GenSigTimeoutTime" BU_SG_REL_ EBCM_HS SG_ 800 FCACBSC_CtrlAcc 250;
BA_REL_ "GenSigSuprvResp" BU_SG_REL_ EBCM_OBD_HS SG_ 800 FCACBSC_AutBrkRpRt 1;
BA_REL_ "GenSigTimeoutMsg" BU_SG_REL_ EBCM_OBD_HS SG_ 800 FCACBSC_AutBrkRpRt 800;
BA_REL_ "GenSigTimeoutTime" BU_SG_REL_ EBCM_OBD_HS SG_ 800 FCACBSC_AutBrkRpRt 250;
BA_REL_ "GenSigSuprvResp" BU_SG_REL_ EBCM_HS SG_ 800 FCACBSC_AutBrkRpRt 1;
BA_REL_ "GenSigTimeoutMsg" BU_SG_REL_ EBCM_HS SG_ 800 FCACBSC_AutBrkRpRt 800;
BA_REL_ "GenSigTimeoutTime" BU_SG_REL_ EBCM_HS SG_ 800 FCACBSC_AutBrkRpRt 250;
BA_REL_ "GenSigSuprvResp" BU_SG_REL_ EBCM_OBD_HS SG_ 800 FCACBSC_AutBrkRqTp 1;
BA_REL_ "GenSigTimeoutMsg" BU_SG_REL_ EBCM_OBD_HS SG_ 800 FCACBSC_AutBrkRqTp 800;
BA_REL_ "GenSigTimeoutTime" BU_SG_REL_ EBCM_OBD_HS SG_ 800 FCACBSC_AutBrkRqTp 250;
BA_REL_ "GenSigSuprvResp" BU_SG_REL_ EBCM_HS SG_ 800 FCACBSC_AutBrkRqTp 1;
BA_REL_ "GenSigTimeoutMsg" BU_SG_REL_ EBCM_HS SG_ 800 FCACBSC_AutBrkRqTp 800;
BA_REL_ "GenSigTimeoutTime" BU_SG_REL_ EBCM_HS SG_ 800 FCACBSC_AutBrkRqTp 250;
BA_REL_ "GenSigSuprvResp" BU_SG_REL_ EBCM_OBD_HS SG_ 800 FCACBSC_AutBrkRqd 1;
BA_REL_ "GenSigTimeoutMsg" BU_SG_REL_ EBCM_OBD_HS SG_ 800 FCACBSC_AutBrkRqd 800;
BA_REL_ "GenSigTimeoutTime" BU_SG_REL_ EBCM_OBD_HS SG_ 800 FCACBSC_AutBrkRqd 250;
BA_REL_ "GenSigSuprvResp" BU_SG_REL_ EBCM_HS SG_ 800 FCACBSC_AutBrkRqd 1;
BA_REL_ "GenSigTimeoutMsg" BU_SG_REL_ EBCM_HS SG_ 800 FCACBSC_AutBrkRqd 800;
BA_REL_ "GenSigTimeoutTime" BU_SG_REL_ EBCM_HS SG_ 800 FCACBSC_AutBrkRqd 250;
BA_REL_ "GenSigSuprvResp" BU_SG_REL_ EBCM_OBD_HS SG_ 800 FCACtrlBrkSysCmdRC 1;
BA_REL_ "GenSigTimeoutMsg" BU_SG_REL_ EBCM_OBD_HS SG_ 800 FCACtrlBrkSysCmdRC 800;
BA_REL_ "GenSigTimeoutTime" BU_SG_REL_ EBCM_OBD_HS SG_ 800 FCACtrlBrkSysCmdRC 250;
BA_REL_ "GenSigSuprvResp" BU_SG_REL_ EBCM_HS SG_ 800 FCACtrlBrkSysCmdRC 1;
BA_REL_ "GenSigTimeoutMsg" BU_SG_REL_ EBCM_HS SG_ 800 FCACtrlBrkSysCmdRC 800;
BA_REL_ "GenSigTimeoutTime" BU_SG_REL_ EBCM_HS SG_ 800 FCACtrlBrkSysCmdRC 250;
BA_REL_ "GenSigSuprvResp" BU_SG_REL_ FCM_HS SG_ 388 HndsOffStrWhlDtSt 1;
BA_REL_ "GenSigTimeoutMsg" BU_SG_REL_ FCM_HS SG_ 388 HndsOffStrWhlDtSt 388;
BA_REL_ "GenSigTimeoutTime" BU_SG_REL_ FCM_HS SG_ 388 HndsOffStrWhlDtSt 250;
BA_REL_ "GenSigSuprvResp" BU_SG_REL_ FCM_HS SG_ 388 HndsOffStrWhlDtMd 1;
BA_REL_ "GenSigTimeoutMsg" BU_SG_REL_ FCM_HS SG_ 388 HndsOffStrWhlDtMd 388;
BA_REL_ "GenSigTimeoutTime" BU_SG_REL_ FCM_HS SG_ 388 HndsOffStrWhlDtMd 250;
BA_REL_ "GenSigSuprvResp" BU_SG_REL_ FCM_HS SG_ 388 LKATrqOvrlDlvdPrtVl 1;
BA_REL_ "GenSigTimeoutMsg" BU_SG_REL_ FCM_HS SG_ 388 LKATrqOvrlDlvdPrtVl 388;
BA_REL_ "GenSigTimeoutTime" BU_SG_REL_ FCM_HS SG_ 388 LKATrqOvrlDlvdPrtVl 250;
BA_REL_ "GenSigSuprvResp" BU_SG_REL_ FCM_HS SG_ 388 LKATrqOvrlDltTrqDlvd 1;
BA_REL_ "GenSigTimeoutMsg" BU_SG_REL_ FCM_HS SG_ 388 LKATrqOvrlDltTrqDlvd 388;
BA_REL_ "GenSigTimeoutTime" BU_SG_REL_ FCM_HS SG_ 388 LKATrqOvrlDltTrqDlvd 250;
BA_REL_ "GenSigSuprvResp" BU_SG_REL_ FCM_HS SG_ 388 LKATrqOvrlDlvdRC 1;
BA_REL_ "GenSigTimeoutMsg" BU_SG_REL_ FCM_HS SG_ 388 LKATrqOvrlDlvdRC 388;
BA_REL_ "GenSigTimeoutTime" BU_SG_REL_ FCM_HS SG_ 388 LKATrqOvrlDlvdRC 250;
BA_REL_ "GenSigSuprvResp" BU_SG_REL_ FCM_HS SG_ 388 LKAElPwrStTtlTqDlvd 1;
BA_REL_ "GenSigTimeoutMsg" BU_SG_REL_ FCM_HS SG_ 388 LKAElPwrStTtlTqDlvd 388;
BA_REL_ "GenSigTimeoutTime" BU_SG_REL_ FCM_HS SG_ 388 LKAElPwrStTtlTqDlvd 250;
BA_REL_ "GenSigSuprvResp" BU_SG_REL_ FCM_HS SG_ 388 LKATrqOvrlTrqDStat 1;
BA_REL_ "GenSigTimeoutMsg" BU_SG_REL_ FCM_HS SG_ 388 LKATrqOvrlTrqDStat 388;
BA_REL_ "GenSigTimeoutTime" BU_SG_REL_ FCM_HS SG_ 388 LKATrqOvrlTrqDStat 250;
BA_REL_ "GenSigSuprvResp" BU_SG_REL_ EPS_HS SG_ 384 LKATqOvrDltCmdPrtVl 1;
BA_REL_ "GenSigTimeoutMsg" BU_SG_REL_ EPS_HS SG_ 384 LKATqOvrDltCmdPrtVl 384;
BA_REL_ "GenSigTimeoutTime" BU_SG_REL_ EPS_HS SG_ 384 LKATqOvrDltCmdPrtVl 250;
BA_REL_ "GenSigSuprvResp" BU_SG_REL_ EPS_HS SG_ 384 LKATqOvrDltCmdRC 1;
BA_REL_ "GenSigTimeoutMsg" BU_SG_REL_ EPS_HS SG_ 384 LKATqOvrDltCmdRC 384;
BA_REL_ "GenSigTimeoutTime" BU_SG_REL_ EPS_HS SG_ 384 LKATqOvrDltCmdRC 250;
BA_REL_ "GenSigSuprvResp" BU_SG_REL_ EPS_HS SG_ 384 LKATODC_TrqVl 1;
BA_REL_ "GenSigTimeoutMsg" BU_SG_REL_ EPS_HS SG_ 384 LKATODC_TrqVl 384;
BA_REL_ "GenSigTimeoutTime" BU_SG_REL_ EPS_HS SG_ 384 LKATODC_TrqVl 250;
BA_REL_ "GenSigSuprvResp" BU_SG_REL_ EPS_HS SG_ 384 LKATODC_TrqRqAct 1;
BA_REL_ "GenSigTimeoutMsg" BU_SG_REL_ EPS_HS SG_ 384 LKATODC_TrqRqAct 384;
BA_REL_ "GenSigTimeoutTime" BU_SG_REL_ EPS_HS SG_ 384 LKATODC_TrqRqAct 250;
BA_REL_ "GenSigSuprvResp" BU_SG_REL_ VICM_HS SG_ 866 RegenBrkAxTrqAch 1;
BA_REL_ "GenSigTimeoutMsg" BU_SG_REL_ VICM_HS SG_ 866 RegenBrkAxTrqAch 866;
BA_REL_ "GenSigTimeoutTime" BU_SG_REL_ VICM_HS SG_ 866 RegenBrkAxTrqAch 250;
BA_REL_ "GenSigSuprvResp" BU_SG_REL_ VICM_HS SG_ 1223 EngSnPwrECoolLpTmp 1;
BA_REL_ "GenSigTimeoutMsg" BU_SG_REL_ VICM_HS SG_ 1223 EngSnPwrECoolLpTmp 1223;
BA_REL_ "GenSigTimeoutTime" BU_SG_REL_ VICM_HS SG_ 1223 EngSnPwrECoolLpTmp 1250;
BA_REL_ "GenSigSuprvResp" BU_SG_REL_ VICM2_HS SG_ 1223 PropSysOffTme 1;
BA_REL_ "GenSigTimeoutMsg" BU_SG_REL_ VICM2_HS SG_ 1223 PropSysOffTme 1223;
BA_REL_ "GenSigTimeoutTime" BU_SG_REL_ VICM2_HS SG_ 1223 PropSysOffTme 1250;
BA_REL_ "GenSigSuprvResp" BU_SG_REL_ EBCM_OBD_HS SG_ 1223 PropSysOffTme 1;
BA_REL_ "GenSigTimeoutMsg" BU_SG_REL_ EBCM_OBD_HS SG_ 1223 PropSysOffTme 1223;
BA_REL_ "GenSigTimeoutTime" BU_SG_REL_ EBCM_OBD_HS SG_ 1223 PropSysOffTme 1250;
BA_REL_ "GenSigSuprvResp" BU_SG_REL_ EBCM_HS SG_ 1223 PropSysOffTme 1;
BA_REL_ "GenSigTimeoutMsg" BU_SG_REL_ EBCM_HS SG_ 1223 PropSysOffTme 1223;
BA_REL_ "GenSigTimeoutTime" BU_SG_REL_ EBCM_HS SG_ 1223 PropSysOffTme 1250;
BA_REL_ "GenSigSuprvResp" BU_SG_REL_ VICM_HS SG_ 1223 PropSysOffTme 1;
BA_REL_ "GenSigTimeoutMsg" BU_SG_REL_ VICM_HS SG_ 1223 PropSysOffTme 1223;
BA_REL_ "GenSigTimeoutTime" BU_SG_REL_ VICM_HS SG_ 1223 PropSysOffTme 1250;
BA_REL_ "GenSigSuprvResp" BU_SG_REL_ PTO_HS SG_ 543 PTOTpStpSpdCsStReq 1;
BA_REL_ "GenSigTimeoutMsg" BU_SG_REL_ PTO_HS SG_ 543 PTOTpStpSpdCsStReq 543;
BA_REL_ "GenSigTimeoutTime" BU_SG_REL_ PTO_HS SG_ 543 PTOTpStpSpdCsStReq 250;
BA_REL_ "GenSigSuprvResp" BU_SG_REL_ PTO_HS SG_ 543 PTOStdbySpdCsStReq 1;
BA_REL_ "GenSigTimeoutMsg" BU_SG_REL_ PTO_HS SG_ 543 PTOStdbySpdCsStReq 543;
BA_REL_ "GenSigTimeoutTime" BU_SG_REL_ PTO_HS SG_ 543 PTOStdbySpdCsStReq 250;
BA_REL_ "GenSigSuprvResp" BU_SG_REL_ PTO_HS SG_ 543 PTOEngRnTmrCsStRq 1;
BA_REL_ "GenSigTimeoutMsg" BU_SG_REL_ PTO_HS SG_ 543 PTOEngRnTmrCsStRq 543;
BA_REL_ "GenSigTimeoutTime" BU_SG_REL_ PTO_HS SG_ 543 PTOEngRnTmrCsStRq 250;
BA_REL_ "GenSigSuprvResp" BU_SG_REL_ PTO_HS SG_ 543 PTOSet2SpdCsStReq 1;
BA_REL_ "GenSigTimeoutMsg" BU_SG_REL_ PTO_HS SG_ 543 PTOSet2SpdCsStReq 543;
BA_REL_ "GenSigTimeoutTime" BU_SG_REL_ PTO_HS SG_ 543 PTOSet2SpdCsStReq 250;
BA_REL_ "GenSigSuprvResp" BU_SG_REL_ PTO_HS SG_ 543 PTOSet1SpdCsStReq 1;
BA_REL_ "GenSigTimeoutMsg" BU_SG_REL_ PTO_HS SG_ 543 PTOSet1SpdCsStReq 543;
BA_REL_ "GenSigTimeoutTime" BU_SG_REL_ PTO_HS SG_ 543 PTOSet1SpdCsStReq 250;
BA_REL_ "GenSigSuprvResp" BU_SG_REL_ BCM_HS SG_ 544 PTOAudExtAlertReq 1;
BA_REL_ "GenSigTimeoutMsg" BU_SG_REL_ BCM_HS SG_ 544 PTOAudExtAlertReq 544;
BA_REL_ "GenSigTimeoutTime" BU_SG_REL_ BCM_HS SG_ 544 PTOAudExtAlertReq 625;
BA_REL_ "GenSigSuprvResp" BU_SG_REL_ BCM_HS SG_ 544 PTOTransInGearIO 1;
BA_REL_ "GenSigTimeoutMsg" BU_SG_REL_ BCM_HS SG_ 544 PTOTransInGearIO 544;
BA_REL_ "GenSigTimeoutTime" BU_SG_REL_ BCM_HS SG_ 544 PTOTransInGearIO 625;
BA_REL_ "GenSigSuprvResp" BU_SG_REL_ BCM_HS SG_ 544 PTOTpStpSpdCsStAvl 1;
BA_REL_ "GenSigTimeoutMsg" BU_SG_REL_ BCM_HS SG_ 544 PTOTpStpSpdCsStAvl 544;
BA_REL_ "GenSigTimeoutTime" BU_SG_REL_ BCM_HS SG_ 544 PTOTpStpSpdCsStAvl 625;
BA_REL_ "GenSigSuprvResp" BU_SG_REL_ BCM_HS SG_ 544 PTOTpStSpdCsCrStVal 1;
BA_REL_ "GenSigTimeoutMsg" BU_SG_REL_ BCM_HS SG_ 544 PTOTpStSpdCsCrStVal 544;
BA_REL_ "GenSigTimeoutTime" BU_SG_REL_ BCM_HS SG_ 544 PTOTpStSpdCsCrStVal 625;
BA_REL_ "GenSigSuprvResp" BU_SG_REL_ BCM_HS SG_ 544 PTOStdbySpdCsStAvl 1;
BA_REL_ "GenSigTimeoutMsg" BU_SG_REL_ BCM_HS SG_ 544 PTOStdbySpdCsStAvl 544;
BA_REL_ "GenSigTimeoutTime" BU_SG_REL_ BCM_HS SG_ 544 PTOStdbySpdCsStAvl 625;
BA_REL_ "GenSigSuprvResp" BU_SG_REL_ BCM_HS SG_ 544 PTOStdbSpdCsCrStVal 1;
BA_REL_ "GenSigTimeoutMsg" BU_SG_REL_ BCM_HS SG_ 544 PTOStdbSpdCsCrStVal 544;
BA_REL_ "GenSigTimeoutTime" BU_SG_REL_ BCM_HS SG_ 544 PTOStdbSpdCsCrStVal 625;
BA_REL_ "GenSigSuprvResp" BU_SG_REL_ BCM_HS SG_ 544 PTOSetPrkBrkIO 1;
BA_REL_ "GenSigTimeoutMsg" BU_SG_REL_ BCM_HS SG_ 544 PTOSetPrkBrkIO 544;
BA_REL_ "GenSigTimeoutTime" BU_SG_REL_ BCM_HS SG_ 544 PTOSetPrkBrkIO 625;
BA_REL_ "GenSigSuprvResp" BU_SG_REL_ BCM_HS SG_ 544 PTOSet2SpdCsStAvl 1;
BA_REL_ "GenSigTimeoutMsg" BU_SG_REL_ BCM_HS SG_ 544 PTOSet2SpdCsStAvl 544;
BA_REL_ "GenSigTimeoutTime" BU_SG_REL_ BCM_HS SG_ 544 PTOSet2SpdCsStAvl 625;
BA_REL_ "GenSigSuprvResp" BU_SG_REL_ BCM_HS SG_ 544 PTOSet2SpdCsCrStVal 1;
BA_REL_ "GenSigTimeoutMsg" BU_SG_REL_ BCM_HS SG_ 544 PTOSet2SpdCsCrStVal 544;
BA_REL_ "GenSigTimeoutTime" BU_SG_REL_ BCM_HS SG_ 544 PTOSet2SpdCsCrStVal 625;
BA_REL_ "GenSigSuprvResp" BU_SG_REL_ BCM_HS SG_ 544 PTOSet1SpdCsStAvl 1;
BA_REL_ "GenSigTimeoutMsg" BU_SG_REL_ BCM_HS SG_ 544 PTOSet1SpdCsStAvl 544;
BA_REL_ "GenSigTimeoutTime" BU_SG_REL_ BCM_HS SG_ 544 PTOSet1SpdCsStAvl 625;
BA_REL_ "GenSigSuprvResp" BU_SG_REL_ BCM_HS SG_ 544 PTOSet1SpdCsCrStVal 1;
BA_REL_ "GenSigTimeoutMsg" BU_SG_REL_ BCM_HS SG_ 544 PTOSet1SpdCsCrStVal 544;
BA_REL_ "GenSigTimeoutTime" BU_SG_REL_ BCM_HS SG_ 544 PTOSet1SpdCsCrStVal 625;
BA_REL_ "GenSigSuprvResp" BU_SG_REL_ BCM_HS SG_ 544 PTORelCltPedIO 1;
BA_REL_ "GenSigTimeoutMsg" BU_SG_REL_ BCM_HS SG_ 544 PTORelCltPedIO 544;
BA_REL_ "GenSigTimeoutTime" BU_SG_REL_ BCM_HS SG_ 544 PTORelCltPedIO 625;
BA_REL_ "GenSigSuprvResp" BU_SG_REL_ BCM_HS SG_ 544 PTORelBrkPedIO 1;
BA_REL_ "GenSigTimeoutMsg" BU_SG_REL_ BCM_HS SG_ 544 PTORelBrkPedIO 544;
BA_REL_ "GenSigTimeoutTime" BU_SG_REL_ BCM_HS SG_ 544 PTORelBrkPedIO 625;
BA_REL_ "GenSigSuprvResp" BU_SG_REL_ BCM_HS SG_ 544 PTORelAccPedIO 1;
BA_REL_ "GenSigTimeoutMsg" BU_SG_REL_ BCM_HS SG_ 544 PTORelAccPedIO 544;
BA_REL_ "GenSigTimeoutTime" BU_SG_REL_ BCM_HS SG_ 544 PTORelAccPedIO 625;
BA_REL_ "GenSigSuprvResp" BU_SG_REL_ BCM_HS SG_ 544 PTORedEngSpdIO 1;
BA_REL_ "GenSigTimeoutMsg" BU_SG_REL_ BCM_HS SG_ 544 PTORedEngSpdIO 544;
BA_REL_ "GenSigTimeoutTime" BU_SG_REL_ BCM_HS SG_ 544 PTORedEngSpdIO 625;
BA_REL_ "GenSigSuprvResp" BU_SG_REL_ BCM_HS SG_ 544 PTOPrsRelCltPedIO 1;
BA_REL_ "GenSigTimeoutMsg" BU_SG_REL_ BCM_HS SG_ 544 PTOPrsRelCltPedIO 544;
BA_REL_ "GenSigTimeoutTime" BU_SG_REL_ BCM_HS SG_ 544 PTOPrsRelCltPedIO 625;
BA_REL_ "GenSigSuprvResp" BU_SG_REL_ BCM_HS SG_ 544 PTOPrsRelBrkPedIO 1;
BA_REL_ "GenSigTimeoutMsg" BU_SG_REL_ BCM_HS SG_ 544 PTOPrsRelBrkPedIO 544;
BA_REL_ "GenSigTimeoutTime" BU_SG_REL_ BCM_HS SG_ 544 PTOPrsRelBrkPedIO 625;
BA_REL_ "GenSigSuprvResp" BU_SG_REL_ BCM_HS SG_ 544 PTOEngRnTmrCsStAvl 1;
BA_REL_ "GenSigTimeoutMsg" BU_SG_REL_ BCM_HS SG_ 544 PTOEngRnTmrCsStAvl 544;
BA_REL_ "GenSigTimeoutTime" BU_SG_REL_ BCM_HS SG_ 544 PTOEngRnTmrCsStAvl 625;
BA_REL_ "GenSigSuprvResp" BU_SG_REL_ BCM_HS SG_ 544 PTOEnRnTmCsCrStVal 1;
BA_REL_ "GenSigTimeoutMsg" BU_SG_REL_ BCM_HS SG_ 544 PTOEnRnTmCsCrStVal 544;
BA_REL_ "GenSigTimeoutTime" BU_SG_REL_ BCM_HS SG_ 544 PTOEnRnTmCsCrStVal 625;
BA_REL_ "GenSigSuprvResp" BU_SG_REL_ BCM_HS SG_ 544 PTOEngmntStatInd 1;
BA_REL_ "GenSigTimeoutMsg" BU_SG_REL_ BCM_HS SG_ 544 PTOEngmntStatInd 544;
BA_REL_ "GenSigTimeoutTime" BU_SG_REL_ BCM_HS SG_ 544 PTOEngmntStatInd 625;
BA_REL_ "GenSigSuprvResp" BU_SG_REL_ BCM_HS SG_ 544 PTODisengCrsCntlIO 1;
BA_REL_ "GenSigTimeoutMsg" BU_SG_REL_ BCM_HS SG_ 544 PTODisengCrsCntlIO 544;
BA_REL_ "GenSigTimeoutTime" BU_SG_REL_ BCM_HS SG_ 544 PTODisengCrsCntlIO 625;
VAL_ 844 IMUProtYawRtM 0 "Don't Use Data" 1 "Use Data" ;
VAL_ 844 IMUProtLonAccM 0 "Don't Use Data" 1 "Use Data" ;
VAL_ 844 IMUProtLatAccM 0 "Don't Use Data" 1 "Use Data" ;
VAL_ 308 PFAS_SrvPedAlrtIO 1 "true" 0 "false" ;
VAL_ 308 PFAS_PFASysStat 0 "Disable" 1 "Active" 2 "Fault" 3 "Unused and Reserved" ;
VAL_ 308 PFAS_PFASndGenEn 1 "true" 0 "false" ;
VAL_ 308 PFAS_PFARevSnd 0 "No Action" 1 "Sound #1" 2 "Sound #2" 3 "Sound #3" ;
VAL_ 308 PFAS_PFAFwdSnd 0 "No Action" 1 "Sound #1" 2 "Sound #2" 3 "Sound #3" ;
VAL_ 308 PedFrndlyAlrtCsSetAvl 1 "true" 0 "false" ;
VAL_ 308 PedFrndlyAlrtCsCrStVal 0 "No Value" 1 "Off" 2 "On" ;
VAL_ 806 DCCnvStblznErrIO 1 "true" 0 "false" ;
VAL_ 426 EngPrdctStdyStTorqV 1 "Invalid" 0 "Valid" ;
VAL_ 426 CrnkShftTrqMinOffCapV 1 "Invalid" 0 "Valid" ;
VAL_ 426 CrksftTqMinRunImCapV 1 "Invalid" 0 "Valid" ;
VAL_ 1231 DslExhFluidLvlPrcntV 1 "Invalid" 0 "Valid" ;
VAL_ 963 CltTmpCntlMdEmRMAct 1 "true" 0 "false" ;
VAL_ 963 CTCMERDTC_SysDes 0 "P0-Powertrain Codes SAE Controlled" 1 "P1-Powertrain Codes MFG Controlled" 2 "P2-Powertrain Codes Reserved" 3 "P3-Powertrain Codes Reserved" 4 "C0-Chassis Codes SAE Controlled" 5 "C1-Chassis Codes MFG Controlled" 6 "C2-Chassis Codes Reserved" 7 "C3-Chassis Codes Reserved" 8 "B0-Body Codes SAE Controlled" 9 "B1-Body Codes MFG Controlled" 10 "B2-Body Codes Reserved" 11 "B3-Body Codes Reserved" 12 "U0-Network Codes SAE Controlled" 13 "U1-Network Codes MFG Controlled" 14 "U2- Network Codes Reserved" 15 "U3-Network Codes Reserved" ;
VAL_ 955 RHCS_RdctHtrCCurrV 1 "Invalid" 0 "Valid" ;
VAL_ 955 RHCS_RdctHtrBCurrV 1 "Invalid" 0 "Valid" ;
VAL_ 955 RHCS_RdctHtrACurrV 1 "Invalid" 0 "Valid" ;
VAL_ 563 SPMCA_SusPrfMd6Avl 1 "true" 0 "false" ;
VAL_ 563 SPMCA_SusPrfMd5Avl 1 "true" 0 "false" ;
VAL_ 563 SPMCA_SusPrfMd4Avl 1 "true" 0 "false" ;
VAL_ 563 SPMCA_SusPrfMd3Avl 1 "true" 0 "false" ;
VAL_ 563 SPMCA_SusPrfMd2Avl 1 "true" 0 "false" ;
VAL_ 563 SPMCA_SusPrfMd1Avl 1 "true" 0 "false" ;
VAL_ 563 SPMCA_StrPrfMd6Avl 1 "true" 0 "false" ;
VAL_ 563 SPMCA_StrPrfMd5Avl 1 "true" 0 "false" ;
VAL_ 563 SPMCA_StrPrfMd4Avl 1 "true" 0 "false" ;
VAL_ 563 SPMCA_StrPrfMd3Avl 1 "true" 0 "false" ;
VAL_ 563 SPMCA_StrPrfMd2Avl 1 "true" 0 "false" ;
VAL_ 563 SPMCA_StrPrfMd1Avl 1 "true" 0 "false" ;
VAL_ 563 SPMCA_SndPrfMd6Avl 1 "true" 0 "false" ;
VAL_ 563 SPMCA_SndPrfMd5Avl 1 "true" 0 "false" ;
VAL_ 563 SPMCA_SndPrfMd4Avl 1 "true" 0 "false" ;
VAL_ 563 SPMCA_SndPrfMd3Avl 1 "true" 0 "false" ;
VAL_ 563 SPMCA_SndPrfMd2Avl 1 "true" 0 "false" ;
VAL_ 563 SPMCA_SndPrfMd1Avl 1 "true" 0 "false" ;
VAL_ 563 DPMCA_DispPrfMd6Avl 1 "true" 0 "false" ;
VAL_ 563 DPMCA_DispPrfMd5Avl 1 "true" 0 "false" ;
VAL_ 563 DPMCA_DispPrfMd4Avl 1 "true" 0 "false" ;
VAL_ 563 DPMCA_DispPrfMd3Avl 1 "true" 0 "false" ;
VAL_ 563 DPMCA_DispPrfMd2Avl 1 "true" 0 "false" ;
VAL_ 563 DPMCA_DispPrfMd1Avl 1 "true" 0 "false" ;
VAL_ 563 DPMCA_DrvlPrfMd6Avl 1 "true" 0 "false" ;
VAL_ 563 DPMCA_DrvlPrfMd5Avl 1 "true" 0 "false" ;
VAL_ 563 DPMCA_DrvlPrfMd4Avl 1 "true" 0 "false" ;
VAL_ 563 DPMCA_DrvlPrfMd3Avl 1 "true" 0 "false" ;
VAL_ 563 DPMCA_DrvlPrfMd2Avl 1 "true" 0 "false" ;
VAL_ 563 DPMCA_DrvlPrfMd1Avl 1 "true" 0 "false" ;
VAL_ 1323 TireLRTmpV 1 "Invalid" 0 "Valid" ;
VAL_ 1323 TireLFTmpV 1 "Invalid" 0 "Valid" ;
VAL_ 1323 TireRRTmpV 1 "Invalid" 0 "Valid" ;
VAL_ 1323 TireRFTmpV 1 "Invalid" 0 "Valid" ;
VAL_ 1247 RrPTCoolFanStatV 1 "Invalid" 0 "Valid" ;
VAL_ 1247 RrPTCoolFanStat 0 "Off" 1 "On" ;
VAL_ 873 FrtCmModIntgStat 0 "Pass" 1 "Fail" ;
VAL_ 873 FrtCmModAsmt 0 "No Problem" 1 "Improper Response" 2 "Repeated Challenge" ;
VAL_ 723 PerfTrcEngSpdRqStat 6 "Control System Failure Permanent" 5 "Control System Failure Temporary" 4 "Serial Data Failure Permanent" 3 "Serial Data Failure Temporary" 2 "Lost Arbitration" 1 "Request Honored" 0 "No Request" ;
VAL_ 723 PerfTrcEngSpdLmtStat 3 "Rate & Value Limited" 2 "Value Limited" 1 "Rate Limited" 0 "Not Limited" ;
VAL_ 723 PerfTrcTrqRqStat 6 "Control System Failure Permanent" 5 "Control System Failure Temporary" 4 "Serial Data Failure Permanent" 3 "Serial Data Failure Temporary" 2 "Lost Arbitration" 1 "Request Honored" 0 "No Request" ;
VAL_ 723 PerfTrcTrqLmtStat 3 "Rate & Value Limited" 2 "Value Limited" 1 "Rate Limited" 0 "Not Limited" ;
VAL_ 405 EngDistFuelMdDefltd 1 "true" 0 "false" ;
VAL_ 405 EngInjEnbldD 1 "true" 0 "false" ;
VAL_ 405 EngInjEnbldC 1 "true" 0 "false" ;
VAL_ 405 EngInjEnbldB 1 "true" 0 "false" ;
VAL_ 405 EngInjEnbldA 1 "true" 0 "false" ;
VAL_ 405 ThrPosV 1 "Invalid" 0 "Valid" ;
VAL_ 405 MassAirFloV 1 "Invalid" 0 "Valid" ;
VAL_ 405 EngManfldAbsPrsERV 1 "Invalid" 0 "Valid" ;
VAL_ 419 EngRunng 1 "true" 0 "false" ;
VAL_ 289 ARDM_MsgType 0 "Reserved 1" 1 "Position" 2 "Segment" 3 "Stub" 4 "Profile Short" 5 "Profile Long" 6 "Meta Data" 7 "Reserved 2" ;
VAL_ 871 ACCModIntgStat 0 "Pass" 1 "Fail" ;
VAL_ 871 AdptCrsCtrlModAsmt 0 "No Problem" 1 "Improper Response" 2 "Repeated Challenge" ;
VAL_ 800 FCACBSC_AutBrkRpRt 0 "None" 1 "Light" 2 "Full" 3 "Reserved" ;
VAL_ 800 FCACBSC_AutBrkRqTp 0 "None" 1 "Prefill" 2 "Haptic Pulse" 3 "Brake Per Requested Decel" 4 "Apply Park Brake" 5 "Hold" 6 "Lower Panic Brake Threshold" 7 "Reserved" 8 "Object Detected/Confirmation" ;
VAL_ 800 FCACBSC_AutBrkRqd 1 "true" 0 "false" ;
VAL_ 388 HndsOffStrWhlDtStV 1 "Invalid" 0 "Valid" ;
VAL_ 388 HndsOffStrWhlDtSt 0 "Hands Off" 1 "Hands On" ;
VAL_ 388 HndsOffStrWhlDtMd 0 "Disabled" 1 "Enabled" 2 "Failed" ;
VAL_ 388 LKATrqOvrlTrqDStat 0 "Inactive" 1 "Active" 2 "Temporarily Limited" 3 "Permanently Failed" ;
VAL_ 384 LKATODC_TrqRqAct 1 "true" 0 "false" ;
VAL_ 866 ColPrSysHzrdLghtsReq 0 "No Action" 1 "Activate" 2 "Deactivate" 3 "Reserved" ;
VAL_ 866 ColPrSysWndwsReq 0 "No Action" 1 "Close" 2 "Open" 3 "Reserved" ;
VAL_ 866 ColPrSysDrsReq 0 "No Action" 1 "Lock All" 2 "Unlock All" 3 "Reserved" ;
VAL_ 866 ColPrSysSnrfReq 0 "No Action" 1 "Close" 2 "Open" 3 "Reserved" ;
VAL_ 866 CPSInfotmntMtReq 0 "No Mute" 1 "Unused and Reserved 1" 2 "Unused and Reserved 2" 3 "Mute" ;
VAL_ 866 StBltTgtSetAvl 1 "true" 0 "false" ;
VAL_ 866 StBltTgtCrtSetVal 0 "No Action" 1 "Low" 2 "Normal" 3 "Performance" 4 "Locked" ;
VAL_ 866 MotStBltUnblIO 1 "true" 0 "false" ;
VAL_ 866 MotStBltFldIO 1 "true" 0 "false" ;
VAL_ 951 FuelInjCntrlModInjFltAct 1 "true" 0 "false" ;
VAL_ 951 AFRP_SnsTyp 3 "Gauge Pressure" 2 "Absolute Pressure" 1 "Pressure Relative Manifold Vacuum" 0 "Not Supported" ;
VAL_ 951 FICMDS3_DTCStatus 4 "Diagnostic Failed" 3 "Diagnostic Passed" 2 "No Status to Report" 1 "Critically Disabled" 0 "Not Supported" ;
VAL_ 951 FICMDS2_DTCStatus 4 "Diagnostic Failed" 3 "Diagnostic Passed" 2 "No Status to Report" 1 "Critically Disabled" 0 "Not Supported" ;
VAL_ 951 FICMDS1_DTCStatus 4 "Diagnostic Failed" 3 "Diagnostic Passed" 2 "No Status to Report" 1 "Critically Disabled" 0 "Not Supported" ;
VAL_ 1223 EngSnPwrECoolLpTmpV 1 "Invalid" 0 "Valid" ;
VAL_ 1223 PropSysOffTmeV 1 "Invalid" 0 "Valid" ;
VAL_ 1223 PropSysOffTmeM 1 "Use Data" 0 "Don't Use Data" ;
VAL_ 1227 BattThrmlCondOffTmeV 1 "Invalid" 0 "Valid" ;
VAL_ 1227 BattThrmlCondOffTmeM 1 "Use Data" 0 "Don't Use Data" ;
VAL_ 1227 OffBrdChrgOffTmeV 1 "Invalid" 0 "Valid" ;
VAL_ 1227 OffBrdChrgOffTmeM 1 "Use Data" 0 "Don't Use Data" ;
VAL_ 543 PTOTpStpSpdCsStReq 0 "No Action" 1 "5 rpm" 2 "10 rpm" 3 "25 rpm" 4 "50 rpm" 5 "100 rpm" 6 "250 rpm" 7 "500 rpm" ;
VAL_ 543 PTOStdbySpdCsStReq 0 "No Action" 1 "900 rpm" 2 "1000 rpm" 3 "1100 rpm" 4 "1200 rpm" 5 "1300 rpm" 6 "1400 rpm" 7 "1500 rpm" ;
VAL_ 543 PTOEngRnTmrCsStRq 0 "No Action" 1 "10 min" 2 "30 min" 3 "90 min" 4 "120 min" 5 "150 min" 6 "180 min" 7 "210 min" 8 "240 min" 9 "270 min" 10 "300 min" 11 "330 min" 12 "360 min" 13 "390 min" 14 "420 min" 15 "450 min" ;
VAL_ 543 PTOSet2SpdCsStReq 0 "No Action" 1 "1900 rpm" 2 "2000 rpm" 3 "2100 rpm" 4 "2200 rpm" 5 "2300 rpm" 6 "2400 rpm" 7 "2500 rpm" 8 "2600 rpm" 9 "2700 rpm" 10 "2800 rpm" 11 "2900 rpm" 12 "3000 rpm" 13 "3100 rpm" 14 "3200 rpm" 15 "3300 rpm" ;
VAL_ 543 PTOSet1SpdCsStReq 0 "No Action" 1 "1100 rpm" 2 "1200 rpm" 3 "1300 rpm" 4 "1400 rpm" 5 "1500 rpm" 6 "1600 rpm" 7 "1700 rpm" 8 "1800 rpm" 9 "1900 rpm" 10 "2000 rpm" 11 "2100 rpm" 12 "2200 rpm" 13 "2300 rpm" 14 "2400 rpm" 15 "2500 rpm" ;
VAL_ 544 PTOAudExtAlertReq 1 "true" 0 "false" ;
VAL_ 544 PTOTransInGearIO 1 "true" 0 "false" ;
VAL_ 544 PTOTpStpSpdCsStAvl 1 "true" 0 "false" ;
VAL_ 544 PTOTpStSpdCsCrStVal 0 "No Action" 1 "5 rpm" 2 "10 rpm" 3 "25 rpm" 4 "50 rpm" 5 "100 rpm" 6 "250 rpm" 7 "500 rpm" ;
VAL_ 544 PTOStdbySpdCsStAvl 1 "true" 0 "false" ;
VAL_ 544 PTOStdbSpdCsCrStVal 0 "No Action" 1 "900 rpm" 2 "1000 rpm" 3 "1100 rpm" 4 "1200 rpm" 5 "1300 rpm" 6 "1400 rpm" 7 "1500 rpm" ;
VAL_ 544 PTOSetPrkBrkIO 1 "true" 0 "false" ;
VAL_ 544 PTOSet2SpdCsStAvl 1 "true" 0 "false" ;
VAL_ 544 PTOSet2SpdCsCrStVal 0 "No Action" 1 "1900 rpm" 2 "2000 rpm" 3 "2100 rpm" 4 "2200 rpm" 5 "2300 rpm" 6 "2400 rpm" 7 "2500 rpm" 8 "2600 rpm" 9 "2700 rpm" 10 "2800 rpm" 11 "2900 rpm" 12 "3000 rpm" 13 "3100 rpm" 14 "3200 rpm" 15 "3300 rpm" ;
VAL_ 544 PTOSet1SpdCsStAvl 1 "true" 0 "false" ;
VAL_ 544 PTOSet1SpdCsCrStVal 0 "No Action" 1 "1100 rpm" 2 "1200 rpm" 3 "1300 rpm" 4 "1400 rpm" 5 "1500 rpm" 6 "1600 rpm" 7 "1700 rpm" 8 "1800 rpm" 9 "1900 rpm" 10 "2000 rpm" 11 "2100 rpm" 12 "2200 rpm" 13 "2300 rpm" 14 "2400 rpm" 15 "2500 rpm" ;
VAL_ 544 PTORelCltPedIO 1 "true" 0 "false" ;
VAL_ 544 PTORelBrkPedIO 1 "true" 0 "false" ;
VAL_ 544 PTORelAccPedIO 1 "true" 0 "false" ;
VAL_ 544 PTORedEngSpdIO 1 "true" 0 "false" ;
VAL_ 544 PTOPrsRelCltPedIO 1 "true" 0 "false" ;
VAL_ 544 PTOPrsRelBrkPedIO 1 "true" 0 "false" ;
VAL_ 544 PTOEngRnTmrCsStAvl 1 "true" 0 "false" ;
VAL_ 544 PTOEnRnTmCsCrStVal 0 "No Action" 1 "10 min" 2 "30 min" 3 "90 min" 4 "120 min" 5 "150 min" 6 "180 min" 7 "210 min" 8 "240 min" 9 "270 min" 10 "300 min" 11 "330 min" 12 "360 min" 13 "390 min" 14 "420 min" 15 "450 min" ;
VAL_ 544 PTOEngmntStatInd 0 "No Indication" 1 "Continuous Indication" 2 "Slow Flashing Indication" 3 "Fast Flashing Indication" ;
VAL_ 544 PTODisengCrsCntlIO 1 "true" 0 "false" ;
SIG_GROUP_ 308 PedFrndlyAlrtStat 1 : PFAS_SrvPedAlrtIO PFAS_PFASysStat PFAS_PFASndVolCtrl PFAS_PFASndGenEn PFAS_PFARevSnd PFAS_PFAFwdSnd PFAS_PFACrsOvrSpd;
SIG_GROUP_ 963 CoolTmpCntlMdERDTC 1 : CTCMERDTC_SysDes CTCMERDTC_CdNum;
SIG_GROUP_ 955 RdctHtrCctStat 1 : RHCS_RdctHtrCCurrV RHCS_RdctHtrBCurrV RHCS_RdctHtrACurrV;
SIG_GROUP_ 563 SusPerfMdCustAvl 1 : SPMCA_SusPrfMd6Avl SPMCA_SusPrfMd5Avl SPMCA_SusPrfMd4Avl SPMCA_SusPrfMd3Avl SPMCA_SusPrfMd2Avl SPMCA_SusPrfMd1Avl;
SIG_GROUP_ 563 StrPerfMdCustAvl 1 : SPMCA_StrPrfMd6Avl SPMCA_StrPrfMd5Avl SPMCA_StrPrfMd4Avl SPMCA_StrPrfMd3Avl SPMCA_StrPrfMd2Avl SPMCA_StrPrfMd1Avl;
SIG_GROUP_ 563 SndPerfMdCustAvl 1 : SPMCA_SndPrfMd6Avl SPMCA_SndPrfMd5Avl SPMCA_SndPrfMd4Avl SPMCA_SndPrfMd3Avl SPMCA_SndPrfMd2Avl SPMCA_SndPrfMd1Avl;
SIG_GROUP_ 563 DispPerfCustMdAvl 1 : DPMCA_DispPrfMd6Avl DPMCA_DispPrfMd5Avl DPMCA_DispPrfMd4Avl DPMCA_DispPrfMd3Avl DPMCA_DispPrfMd2Avl DPMCA_DispPrfMd1Avl;
SIG_GROUP_ 563 DrvlnPerfMdCustAvl 1 : DPMCA_DrvlPrfMd6Avl DPMCA_DrvlPrfMd5Avl DPMCA_DrvlPrfMd4Avl DPMCA_DrvlPrfMd3Avl DPMCA_DrvlPrfMd2Avl DPMCA_DrvlPrfMd1Avl;
SIG_GROUP_ 873 AdptCrsCtrlModRsp 1 : ACCMR_RptdChlng ACCMR_Answr;
SIG_GROUP_ 289 ADASISRawDatMplxd 1 : ARDM_RawData ARDM_MsgType;
SIG_GROUP_ 871 FrtCmModRsp 1 : FCMR_RptdChlng FCMR_Answr;
SIG_GROUP_ 800 FCACtrlBrkSysCmd 1 : FCACBSC_CtrlAcc FCACBSC_AutBrkRpRt FCACBSC_AutBrkRqTp FCACBSC_AutBrkRqd;
SIG_GROUP_ 384 LKATqOvrDltCmd 1 : LKATODC_TrqVl LKATODC_TrqRqAct;
SIG_GROUP_ 951 AltFuelRailPrs 1 : AFRP_RailPrs AFRP_SnsTyp;
SIG_GROUP_ 951 FuelInjCntrlModDiagSt3 1 : FICMDS3_DTCStatus FICMDS3_DTCIndx;
SIG_GROUP_ 951 FuelInjCntrlModDiagSt2 1 : FICMDS2_DTCStatus FICMDS2_DTCIndx;
SIG_GROUP_ 951 FuelInjCntrlModDiagSt1 1 : FICMDS1_DTCStatus FICMDS1_DTCIndx;
